VERSION ""

NS_ :

BS_:

BU_: ARM APIM_CDC APIM_CISM APIM ESPM DSP APIM_CIM FCIMB RACM_RCIM HUD_ADV WCM TRM_ITRM ACM GWM _delete IPC GENERIC TSTR

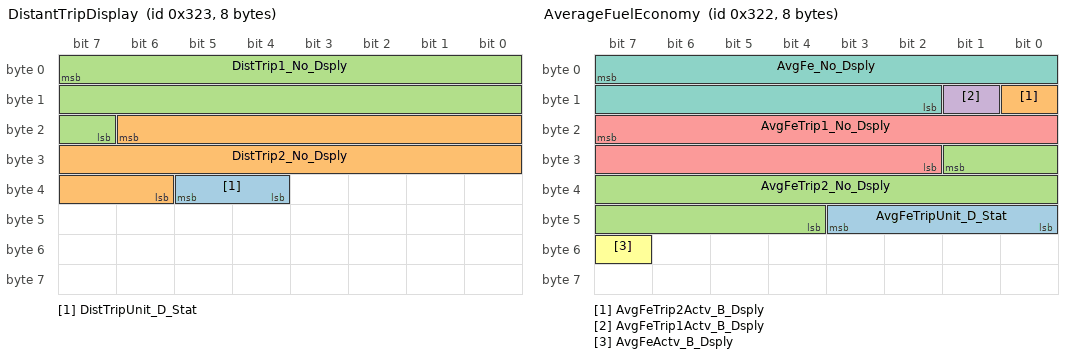
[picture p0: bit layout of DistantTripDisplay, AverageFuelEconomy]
BO_ 803 DistantTripDisplay: 8 IPC
 SG_ DistTripUnit_D_Stat : 37|2@0+ (1,0) [0|3] "SED"  APIM,APIM_CISM
 SG_ DistTrip2_No_Dsply : 22|17@0+ (0.1,0) [0|13107.1] "unitless"  APIM,APIM_CISM
 SG_ DistTrip1_No_Dsply : 7|17@0+ (0.1,0) [0|13107.1] "unitless"  APIM,APIM_CISM

BO_ 802 AverageFuelEconomy: 8 IPC
 SG_ AvgFeTripUnit_D_Stat : 43|4@0+ (1,0) [0|15] "SED"  APIM,APIM_CISM
 SG_ AvgFeTrip2Actv_B_Dsply : 8|1@0+ (1,0) [0|1] "SED"  APIM,APIM_CISM
 SG_ AvgFeTrip2_No_Dsply : 25|14@0+ (0.1,0) [0|1638.3] "unitless"  APIM,APIM_CISM
 SG_ AvgFeTrip1Actv_B_Dsply : 9|1@0+ (1,0) [0|1] "SED"  APIM,APIM_CISM
 SG_ AvgFeTrip1_No_Dsply : 23|14@0+ (0.1,0) [0|1638.3] "unitless"  APIM,APIM_CISM
 SG_ AvgFeActv_B_Dsply : 55|1@0+ (1,0) [0|1] "SED"  APIM,APIM_CISM
 SG_ AvgFe_No_Dsply : 7|14@0+ (0.1,0) [0|1638.3] "unitless"  APIM,APIM_CISM

BO_ 812 TimerDisplay_Data: 8 IPC
 SG_ TimerTrip2_T_Dsply : 29|26@0+ (1,0) [0|67108863] "second"  APIM,APIM_CISM
 SG_ TimerTrip1_T_Dsply : 7|26@0+ (1,0) [0|67108863] "second"  APIM,APIM_CISM

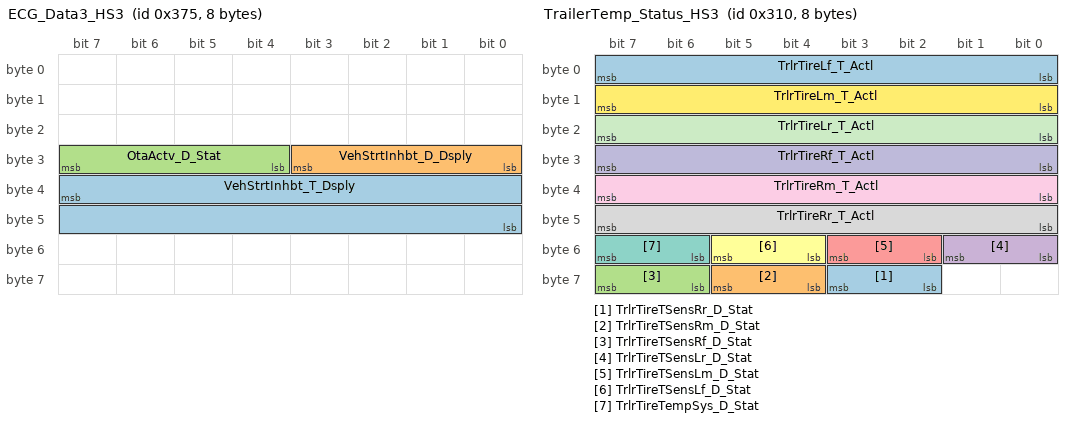
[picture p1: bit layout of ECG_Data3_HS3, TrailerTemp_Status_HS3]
BO_ 885 ECG_Data3_HS3: 8 GWM
 SG_ VehStrtInhbt_T_Dsply : 39|16@0+ (1,0) [0|65535] "second"  APIM_CDC,APIM_CIM,IPC
 SG_ VehStrtInhbt_D_Dsply : 27|4@0+ (1,0) [0|15] "SED"  APIM_CDC,APIM_CIM,IPC
 SG_ OtaActv_D_Stat : 31|4@0+ (1,0) [0|15] "SED"  APIM_CDC,APIM_CIM,IPC

BO_ 784 TrailerTemp_Status_HS3: 8 GWM
 SG_ TrlrTireTSensRr_D_Stat : 59|2@0+ (1,0) [0|3] "SED"  APIM_CDC,APIM_CIM,IPC
 SG_ TrlrTireTSensRm_D_Stat : 61|2@0+ (1,0) [0|3] "SED"  APIM_CDC,APIM_CIM,IPC
 SG_ TrlrTireTSensRf_D_Stat : 63|2@0+ (1,0) [0|3] "SED"  APIM_CDC,APIM_CIM,IPC
 SG_ TrlrTireTSensLr_D_Stat : 49|2@0+ (1,0) [0|3] "SED"  APIM_CDC,APIM_CIM,IPC
 SG_ TrlrTireTSensLm_D_Stat : 51|2@0+ (1,0) [0|3] "SED"  APIM_CDC,APIM_CIM,IPC
 SG_ TrlrTireTSensLf_D_Stat : 53|2@0+ (1,0) [0|3] "SED"  APIM_CDC,IPC,APIM_CIM
 SG_ TrlrTireTempSys_D_Stat : 55|2@0+ (1,0) [0|3] "SED"  APIM_CDC,IPC,APIM_CIM
 SG_ TrlrTireRr_T_Actl : 47|8@0+ (1,-60) [-60|193] "degC"  APIM_CDC,IPC,APIM_CIM
 SG_ TrlrTireRm_T_Actl : 39|8@0+ (1,-60) [-60|193] "degC"  APIM_CDC,IPC,APIM_CIM
 SG_ TrlrTireRf_T_Actl : 31|8@0+ (1,-60) [-60|193] "degC"  APIM_CDC,IPC,APIM_CIM
 SG_ TrlrTireLr_T_Actl : 23|8@0+ (1,-60) [-60|193] "degC"  APIM_CDC,APIM_CIM,IPC
 SG_ TrlrTireLm_T_Actl : 15|8@0+ (1,-60) [-60|193] "degC"  APIM_CDC,APIM_CIM,IPC
 SG_ TrlrTireLf_T_Actl : 7|8@0+ (1,-60) [-60|193] "degC"  APIM_CDC,APIM_CIM,IPC

BO_ 1119 LocationServices_Data2: 8 APIM_CIM
 SG_ LocationServices_2 : 7|64@0+ (1,0) [0|1.84467440737096E+019] "unitless"  GWM,IPC

BO_ 1118 LocationServices_Data1: 8 APIM_CIM
 SG_ LocationServices_1 : 7|64@0+ (1,0) [0|1.84467440737096E+019] "unitless"  IPC,GWM

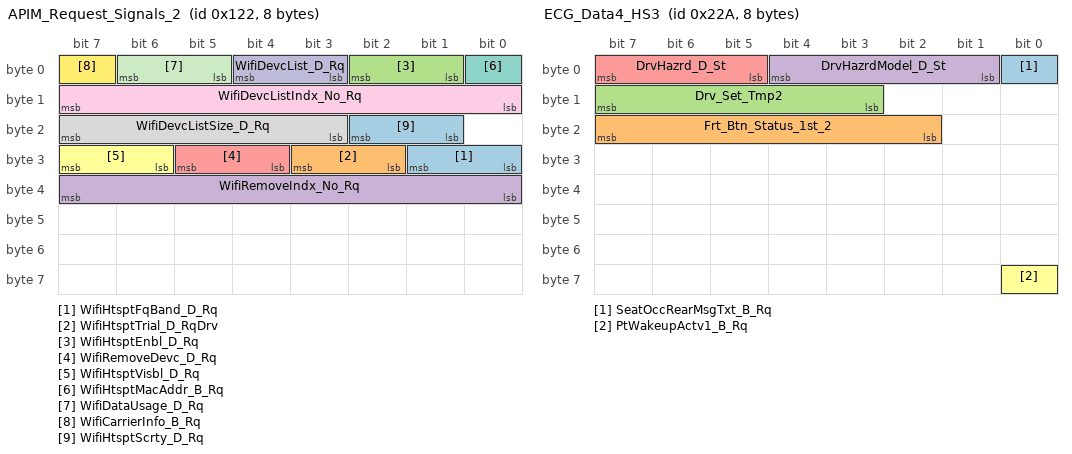
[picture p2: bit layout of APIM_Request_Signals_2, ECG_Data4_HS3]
BO_ 290 APIM_Request_Signals_2: 8 APIM
 SG_ WifiHtsptFqBand_D_Rq : 25|2@0+ (1,0) [0|3] "SED"  GWM
 SG_ WifiHtsptTrial_D_RqDrv : 27|2@0+ (1,0) [0|3] "SED"  GWM
 SG_ WifiHtsptEnbl_D_Rq : 2|2@0+ (1,0) [0|3] "SED"  GWM
 SG_ WifiRemoveIndx_No_Rq : 39|8@0+ (1,0) [0|255] "unitless"  GWM
 SG_ WifiRemoveDevc_D_Rq : 29|2@0+ (1,0) [0|3] "SED"  GWM
 SG_ WifiHtsptVisbl_D_Rq : 31|2@0+ (1,0) [0|3] "SED"  GWM
 SG_ WifiHtsptMacAddr_B_Rq : 0|1@0+ (1,0) [0|1] "SED"  GWM
 SG_ WifiDevcListSize_D_Rq : 23|5@0+ (1,0) [0|31] "unitless"  GWM
 SG_ WifiDevcListIndx_No_Rq : 15|8@0+ (1,0) [0|255] "unitless"  GWM
 SG_ WifiDevcList_D_Rq : 4|2@0+ (1,0) [0|3] "SED"  GWM
 SG_ WifiDataUsage_D_Rq : 6|2@0+ (1,0) [0|3] "SED"  GWM
 SG_ WifiCarrierInfo_B_Rq : 7|1@0+ (1,0) [0|1] "SED"  GWM
 SG_ WifiHtsptScrty_D_Rq : 18|2@0+ (1,0) [0|3] "SED"  GWM

BO_ 554 ECG_Data4_HS3: 8 GWM
 SG_ SeatOccRearMsgTxt_B_Rq : 0|1@0+ (1,0) [0|1] "SED"  APIM_CDC,APIM,APIM_CIM,APIM_CISM
 SG_ Frt_Btn_Status_1st_2 : 23|6@0+ (1,0) [0|63] "SED"  RACM_RCIM
 SG_ Drv_Set_Tmp2 : 15|5@0+ (1,0) [0|31] "SED"  RACM_RCIM
 SG_ DrvHazrdModel_D_St : 4|4@0+ (1,0) [0|15] "SED"  APIM_CDC,APIM,APIM_CISM,APIM_CIM,IPC
 SG_ DrvHazrd_D_St : 7|3@0+ (1,0) [0|7] "SED"  APIM_CDC,APIM,APIM_CISM,APIM_CIM,IPC
 SG_ PtWakeupActv1_B_Rq : 56|1@0+ (1,0) [0|1] "SED"  APIM_CDC,APIM,APIM_CISM,APIM_CIM

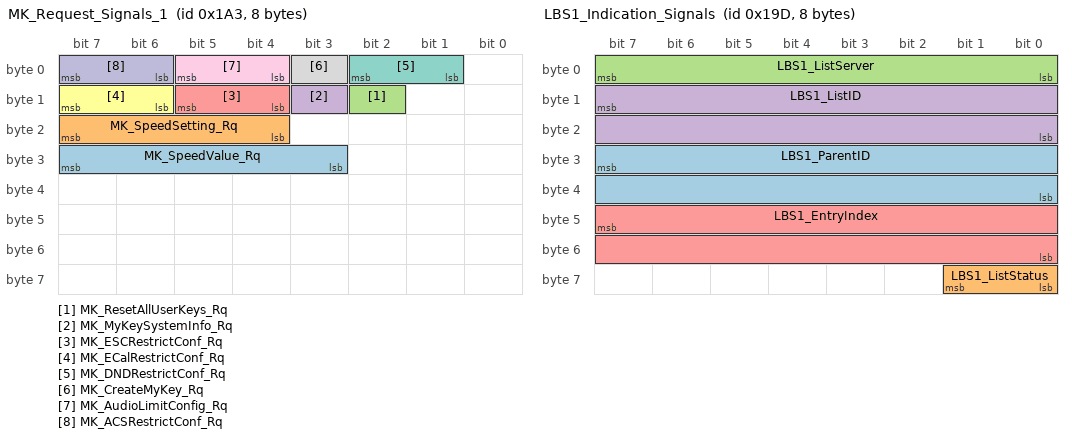
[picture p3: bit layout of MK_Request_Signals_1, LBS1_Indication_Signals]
BO_ 419 MK_Request_Signals_1: 8 APIM
 SG_ MK_SpeedValue_Rq : 31|5@0+ (1,0) [0|31] "SED"  IPC
 SG_ MK_SpeedSetting_Rq : 23|4@0+ (1,0) [0|15] "SED"  IPC
 SG_ MK_ResetAllUserKeys_Rq : 10|1@0+ (1,0) [0|1] "SED"  IPC
 SG_ MK_MyKeySystemInfo_Rq : 11|1@0+ (1,0) [0|1] "SED"  IPC
 SG_ MK_ESCRestrictConf_Rq : 13|2@0+ (1,0) [0|3] "SED"  IPC
 SG_ MK_ECalRestrictConf_Rq : 15|2@0+ (1,0) [0|3] "SED"  IPC
 SG_ MK_DNDRestrictConf_Rq : 2|2@0+ (1,0) [0|3] "SED"  IPC
 SG_ MK_CreateMyKey_Rq : 3|1@0+ (1,0) [0|1] "SED"  IPC
 SG_ MK_AudioLimitConfig_Rq : 5|2@0+ (1,0) [0|3] "SED"  IPC
 SG_ MK_ACSRestrictConf_Rq : 7|2@0+ (1,0) [0|3] "SED"  IPC

BO_ 542 LocationServices_3_HS3: 8 GWM
 SG_ LocationServices_3 : 7|64@0+ (1,0) [0|1.84467440737096E+019] "unitless"  APIM_CDC,APIM,APIM_CISM,APIM_CIM,IPC,ACM

BO_ 413 LBS1_Indication_Signals: 8 APIM
 SG_ LBS1_ParentID : 31|16@0+ (1,0) [0|65535] "unitless"  RACM_RCIM,IPC
 SG_ LBS1_ListStatus : 57|2@0+ (1,0) [0|3] "SED"  RACM_RCIM,IPC
 SG_ LBS1_ListServer : 7|8@0+ (1,0) [0|255] "unitless"  RACM_RCIM,IPC
 SG_ LBS1_ListID : 15|16@0+ (1,0) [0|65535] "unitless"  RACM_RCIM,IPC
 SG_ LBS1_EntryIndex : 47|16@0+ (1,0) [0|65535] "unitless"  RACM_RCIM,IPC

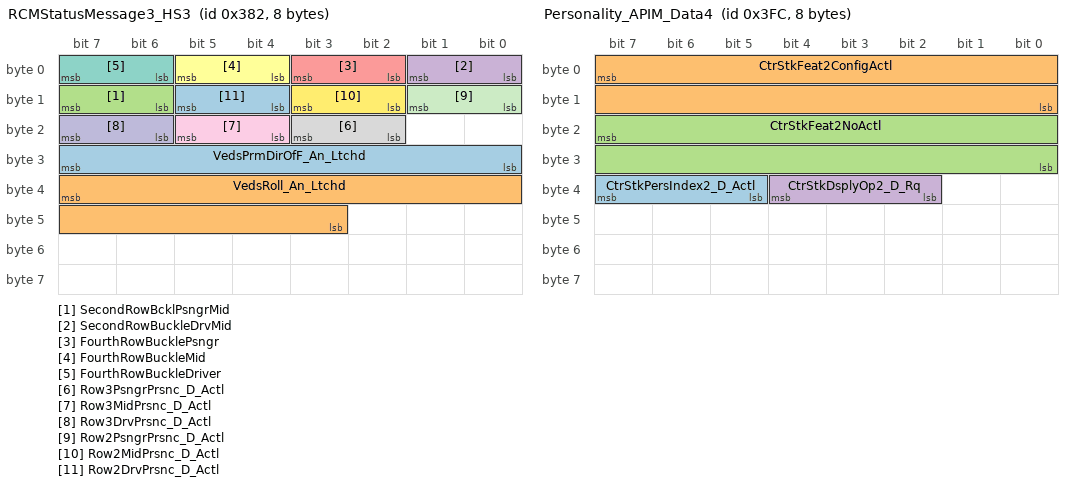
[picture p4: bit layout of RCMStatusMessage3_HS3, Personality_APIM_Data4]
BO_ 898 RCMStatusMessage3_HS3: 8 GWM
 SG_ VedsPrmDirOfF_An_Ltchd : 31|8@0+ (2,-180) [-178|326] "degree"  APIM_CDC,APIM_CIM,APIM_CISM,APIM
 SG_ VedsRoll_An_Ltchd : 39|13@0+ (0.5,-2048) [-2047.5|2046.5] "degree"  APIM_CDC,APIM_CIM,APIM_CISM,APIM
 SG_ SecondRowBcklPsngrMid : 15|2@0+ (1,0) [0|3] "SED"  APIM_CDC,APIM_CIM,IPC
 SG_ SecondRowBuckleDrvMid : 1|2@0+ (1,0) [0|3] "SED"  APIM_CDC,APIM_CIM,IPC
 SG_ FourthRowBucklePsngr : 3|2@0+ (1,0) [0|3] "SED"  APIM_CDC,APIM_CIM,IPC
 SG_ FourthRowBuckleMid : 5|2@0+ (1,0) [0|3] "SED"  APIM_CDC,APIM_CIM,IPC
 SG_ FourthRowBuckleDriver : 7|2@0+ (1,0) [0|3] "SED"  APIM_CDC,APIM_CIM,IPC
 SG_ Row3PsngrPrsnc_D_Actl : 19|2@0+ (1,0) [0|3] "SED"  APIM_CDC,APIM,APIM_CIM,APIM_CISM,IPC
 SG_ Row3MidPrsnc_D_Actl : 21|2@0+ (1,0) [0|3] "SED"  APIM_CDC,APIM,APIM_CIM,APIM_CISM,IPC
 SG_ Row3DrvPrsnc_D_Actl : 23|2@0+ (1,0) [0|3] "SED"  APIM_CDC,APIM,APIM_CIM,APIM_CISM,IPC
 SG_ Row2PsngrPrsnc_D_Actl : 9|2@0+ (1,0) [0|3] "SED"  APIM_CDC,APIM,APIM_CIM,APIM_CISM,IPC
 SG_ Row2MidPrsnc_D_Actl : 11|2@0+ (1,0) [0|3] "SED"  APIM_CDC,APIM,APIM_CIM,APIM_CISM,IPC
 SG_ Row2DrvPrsnc_D_Actl : 13|2@0+ (1,0) [0|3] "SED"  APIM_CDC,APIM,APIM_CIM,APIM_CISM,IPC

BO_ 1020 Personality_APIM_Data4: 8 APIM_CIM
 SG_ CtrStkPersIndex2_D_Actl : 39|3@0+ (1,0) [0|7] "SED"  HUD_ADV,IPC
 SG_ CtrStkFeat2ConfigActl : 7|16@0+ (1,0) [0|65535] "Undefined"  HUD_ADV,IPC
 SG_ CtrStkFeat2NoActl : 23|16@0+ (1,0) [0|65535] "Undefined"  HUD_ADV,IPC
 SG_ CtrStkDsplyOp2_D_Rq : 36|3@0+ (1,0) [0|7] "SED"  HUD_ADV,IPC

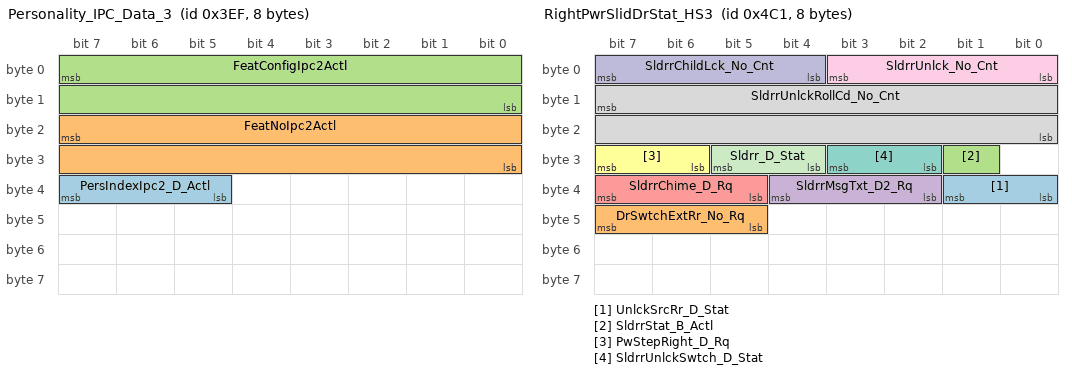
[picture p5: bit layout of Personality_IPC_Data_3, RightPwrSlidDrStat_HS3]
BO_ 1007 Personality_IPC_Data_3: 8 IPC
 SG_ PersIndexIpc2_D_Actl : 39|3@0+ (1,0) [0|7] "SED"  APIM,APIM_CISM
 SG_ FeatNoIpc2Actl : 23|16@0+ (1,0) [0|65535] "Number"  APIM,APIM_CISM
 SG_ FeatConfigIpc2Actl : 7|16@0+ (1,0) [0|65535] "unitless"  APIM,APIM_CISM

BO_ 1217 RightPwrSlidDrStat_HS3: 8 GWM
 SG_ UnlckSrcRr_D_Stat : 33|2@0+ (1,0) [0|3] "SED" Vector__XXX
 SG_ DrSwtchExtRr_No_Rq : 47|3@0+ (1,0) [0|7] "unitless" Vector__XXX
 SG_ SldrrStat_B_Actl : 25|1@0+ (1,0) [0|1] "SED"  APIM_CDC,APIM_CIM,IPC
 SG_ SldrrMsgTxt_D2_Rq : 36|3@0+ (1,0) [0|7] "SED"  APIM_CDC,APIM_CIM,IPC
 SG_ SldrrChime_D_Rq : 39|3@0+ (1,0) [0|7] "SED"  APIM_CDC,APIM_CIM,IPC
 SG_ PwStepRight_D_Rq : 31|2@0+ (1,0) [0|3] "SED" Vector__XXX
 SG_ SldrrUnlckSwtch_D_Stat : 27|2@0+ (1,0) [0|3] "SED" Vector__XXX
 SG_ SldrrUnlckRollCd_No_Cnt : 15|16@0+ (1,0) [0|65535] "unitless" Vector__XXX
 SG_ SldrrUnlck_No_Cnt : 3|4@0+ (1,0) [0|15] "unitless" Vector__XXX
 SG_ SldrrChildLck_No_Cnt : 7|4@0+ (1,0) [0|15] "unitless" Vector__XXX
 SG_ Sldrr_D_Stat : 29|2@0+ (1,0) [0|3] "SED" Vector__XXX

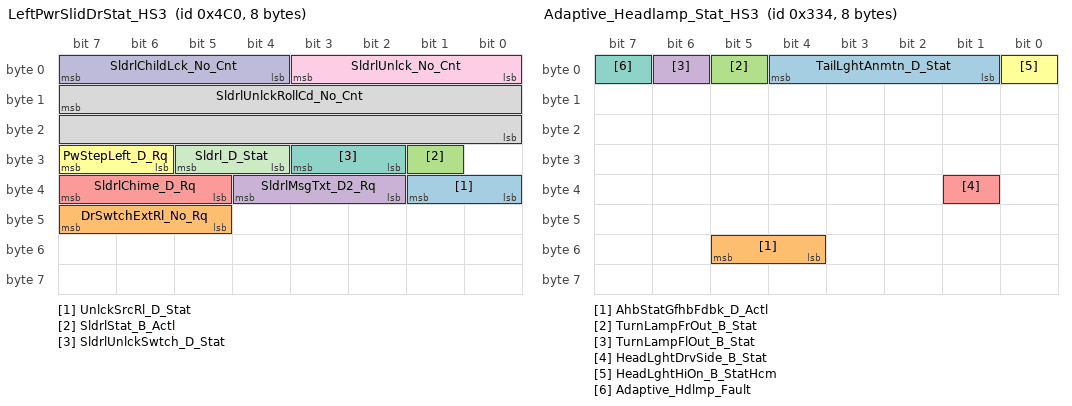
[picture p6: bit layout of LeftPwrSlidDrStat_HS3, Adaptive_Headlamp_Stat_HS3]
BO_ 1216 LeftPwrSlidDrStat_HS3: 8 GWM
 SG_ UnlckSrcRl_D_Stat : 33|2@0+ (1,0) [0|3] "SED" Vector__XXX
 SG_ DrSwtchExtRl_No_Rq : 47|3@0+ (1,0) [0|7] "unitless" Vector__XXX
 SG_ SldrlStat_B_Actl : 25|1@0+ (1,0) [0|1] "SED"  APIM_CDC,APIM_CIM,IPC
 SG_ SldrlMsgTxt_D2_Rq : 36|3@0+ (1,0) [0|7] "SED"  APIM_CDC,APIM_CIM,IPC
 SG_ SldrlChime_D_Rq : 39|3@0+ (1,0) [0|7] "SED"  APIM_CDC,APIM_CIM,IPC
 SG_ PwStepLeft_D_Rq : 31|2@0+ (1,0) [0|3] "SED" Vector__XXX
 SG_ SldrlUnlckSwtch_D_Stat : 27|2@0+ (1,0) [0|3] "SED" Vector__XXX
 SG_ SldrlUnlckRollCd_No_Cnt : 15|16@0+ (1,0) [0|65535] "unitless" Vector__XXX
 SG_ SldrlUnlck_No_Cnt : 3|4@0+ (1,0) [0|15] "unitless" Vector__XXX
 SG_ SldrlChildLck_No_Cnt : 7|4@0+ (1,0) [0|15] "unitless" Vector__XXX
 SG_ Sldrl_D_Stat : 29|2@0+ (1,0) [0|3] "SED" Vector__XXX

BO_ 820 Adaptive_Headlamp_Stat_HS3: 8 GWM
 SG_ TailLghtAnmtn_D_Stat : 4|4@0+ (1,0) [0|15] "SED"  APIM
 SG_ AhbStatGfhbFdbk_D_Actl : 53|2@0+ (1,0) [0|3] "SED" Vector__XXX
 SG_ TurnLampFrOut_B_Stat : 5|1@0+ (1,0) [0|1] "SED" Vector__XXX
 SG_ TurnLampFlOut_B_Stat : 6|1@0+ (1,0) [0|1] "SED" Vector__XXX
 SG_ HeadLghtDrvSide_B_Stat : 33|1@0+ (1,0) [0|1] "SED" Vector__XXX
 SG_ HeadLghtHiOn_B_StatHcm : 0|1@0+ (1,0) [0|1] "SED"  APIM_CDC,APIM_CIM,IPC
 SG_ Adaptive_Hdlmp_Fault : 7|1@0+ (1,0) [0|1] "SED"  APIM_CDC,APIM_CIM,IPC

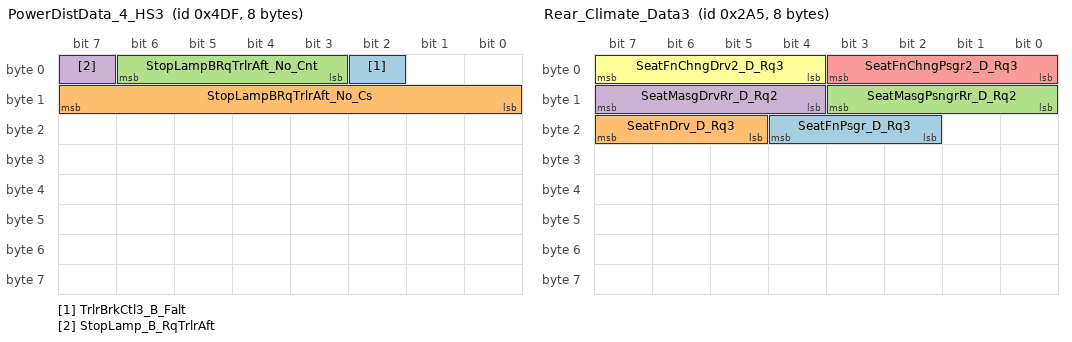
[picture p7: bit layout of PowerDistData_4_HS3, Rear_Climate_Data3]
BO_ 1247 PowerDistData_4_HS3: 8 GWM
 SG_ TrlrBrkCtl3_B_Falt : 2|1@0+ (1,0) [0|1] "SED"  TRM_ITRM
 SG_ StopLampBRqTrlrAft_No_Cs : 15|8@0+ (1,0) [0|255] "Unitless"  TRM_ITRM
 SG_ StopLampBRqTrlrAft_No_Cnt : 6|4@0+ (1,0) [0|15] "Unitless"  TRM_ITRM
 SG_ StopLamp_B_RqTrlrAft : 7|1@0+ (1,0) [0|1] "SED"  TRM_ITRM

BO_ 677 Rear_Climate_Data3: 8 RACM_RCIM
 SG_ SeatFnPsgr_D_Rq3 : 20|3@0+ (1,0) [0|7] "SED"  GWM
 SG_ SeatFnDrv_D_Rq3 : 23|3@0+ (1,0) [0|7] "SED"  GWM
 SG_ SeatMasgPsngrRr_D_Rq2 : 11|4@0+ (1,0) [0|15] "SED"  GWM
 SG_ SeatMasgDrvRr_D_Rq2 : 15|4@0+ (1,0) [0|15] "SED"  GWM
 SG_ SeatFnChngPsgr2_D_Rq3 : 3|4@0+ (1,0) [0|15] "SED"  GWM
 SG_ SeatFnChngDrv2_D_Rq3 : 7|4@0+ (1,0) [0|15] "SED"  GWM

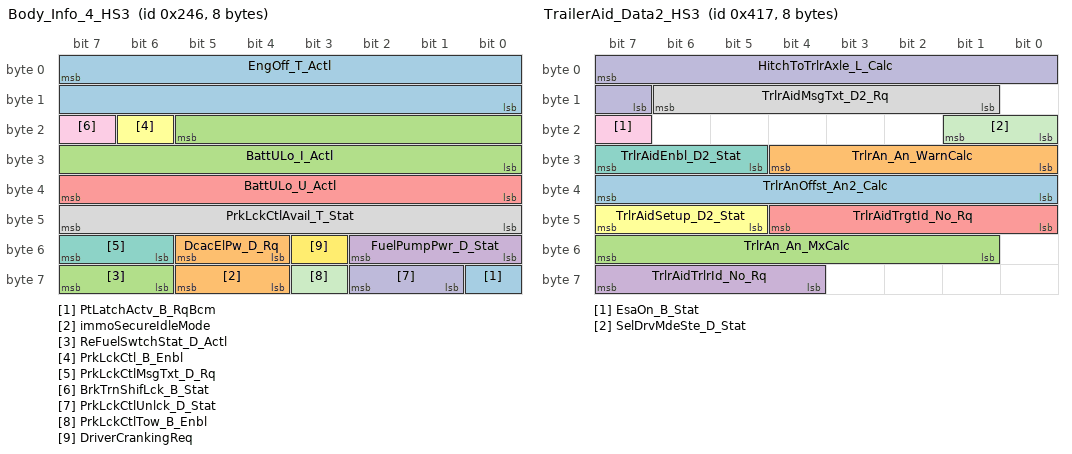
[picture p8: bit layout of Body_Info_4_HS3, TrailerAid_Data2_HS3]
BO_ 582 Body_Info_4_HS3: 8 GWM
 SG_ PtLatchActv_B_RqBcm : 56|1@0+ (1,0) [0|1] "SED"  APIM_CDC,APIM_CIM,IPC
 SG_ immoSecureIdleMode : 61|2@0+ (1,0) [0|3] "SED"  APIM_CDC,APIM,APIM_CISM,APIM_CIM
 SG_ ReFuelSwtchStat_D_Actl : 63|2@0+ (1,0) [0|3] "SED" Vector__XXX
 SG_ FuelPumpPwr_D_Stat : 50|3@0+ (1,0) [0|7] "SED" Vector__XXX
 SG_ BattULo_U_Actl : 39|8@0+ (0.0625,0) [0|15.875] "volt" Vector__XXX
 SG_ PrkLckCtl_B_Enbl : 22|1@0+ (1,0) [0|1] "SED"  APIM_CDC,APIM,APIM_CISM,IPC,APIM_CIM
 SG_ PrkLckCtlMsgTxt_D_Rq : 55|2@0+ (1,0) [0|3] "SED"  APIM_CDC,APIM_CIM,IPC
 SG_ PrkLckCtlAvail_T_Stat : 47|8@0+ (1,0) [0|255] "second"  APIM_CDC,APIM_CIM,IPC
 SG_ BrkTrnShifLck_B_Stat : 23|1@0+ (1,0) [0|1] "SED" Vector__XXX
 SG_ PrkLckCtlUnlck_D_Stat : 58|2@0+ (1,0) [0|3] "SED"  APIM_CDC,APIM_CIM,IPC
 SG_ PrkLckCtlTow_B_Enbl : 59|1@0+ (1,0) [0|1] "SED"  APIM_CDC,APIM_CIM,IPC
 SG_ DriverCrankingReq : 51|1@0+ (1,0) [0|1] "SED" Vector__XXX
 SG_ EngOff_T_Actl : 7|16@0+ (1,0) [0|65534] "second^0.5"  APIM_CDC,APIM_CIM,IPC
 SG_ DcacElPw_D_Rq : 53|2@0+ (1,0) [0|3] "SED" Vector__XXX
 SG_ BattULo_I_Actl : 21|14@0+ (0.0625,-512) [-512|511.875] "ampere" Vector__XXX

BO_ 1036 PedestrianAlert_Data_HS3: 8 GWM
 SG_ PdstrnAlrt_B_Falt : 7|1@0+ (1,0) [0|1] "SED"  APIM_CDC,APIM_CIM,IPC

BO_ 1047 TrailerAid_Data2_HS3: 8 GWM
 SG_ TrlrAnOffst_An2_Calc : 39|8@0+ (0.5,-64) [-64|63.5] "degrees" Vector__XXX
 SG_ TrlrAn_An_WarnCalc : 28|5@0+ (1,0) [0|31] "degrees" Vector__XXX
 SG_ TrlrAn_An_MxCalc : 55|7@0+ (1,0) [0|127] "degrees" Vector__XXX
 SG_ TrlrAidTrlrId_No_Rq : 63|4@0+ (1,0) [0|15] "unitless"  APIM_CDC,APIM,APIM_CISM,APIM_CIM,IPC
 SG_ TrlrAidTrgtId_No_Rq : 44|5@0+ (1,0) [0|31] "unitless" Vector__XXX
 SG_ TrlrAidSetup_D2_Stat : 47|3@0+ (1,0) [0|7] "SED" Vector__XXX
 SG_ TrlrAidEnbl_D2_Stat : 31|3@0+ (1,0) [0|7] "SED"  APIM_CDC,APIM,APIM_CISM,TRM_ITRM,APIM_CIM,IPC
 SG_ TrlrAidMsgTxt_D2_Rq : 14|6@0+ (1,0) [0|63] "SED"  APIM_CDC,APIM,APIM_CISM,APIM_CIM,IPC,TRM_ITRM
 SG_ EsaOn_B_Stat : 23|1@0+ (1,0) [0|1] "SED"  APIM_CDC,APIM_CIM,IPC
 SG_ HitchToTrlrAxle_L_Calc : 7|9@0+ (0.0254,0) [0|12.9794] "meter" Vector__XXX
 SG_ SelDrvMdeSte_D_Stat : 17|2@0+ (1,0) [0|3] "SED" Vector__XXX

BO_ 688 APIM_TCUB_Word_Rx_HS3: 8 GWM
 SG_ APIM_TCUB_Word_Rx : 7|64@0+ (1,0) [0|1.84467440737096E+019] "unitless"  APIM_CDC,APIM,APIM_CISM,APIM_CIM

BO_ 696 APIM_TCUB_Word_Tx: 8 APIM
 SG_ APIM_TCUB_Word_Tx : 7|64@0+ (1,0) [0|1.84467440737096E+019] "unitless"  GWM

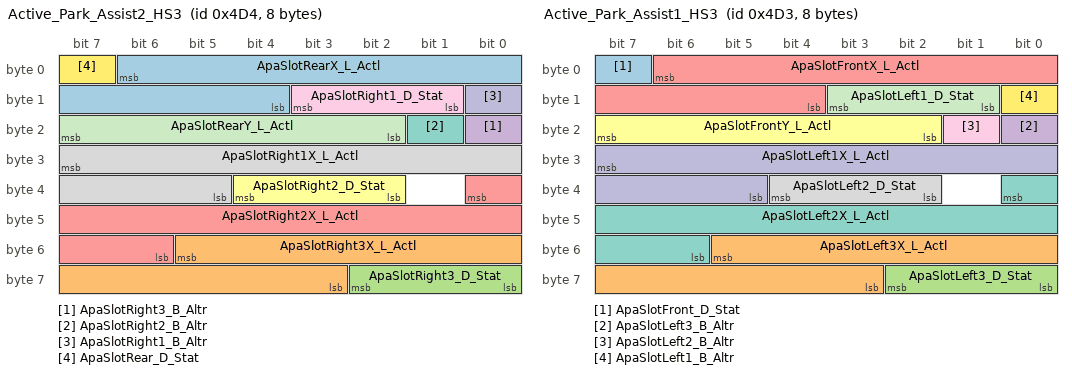
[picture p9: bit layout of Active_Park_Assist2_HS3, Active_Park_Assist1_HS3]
BO_ 1236 Active_Park_Assist2_HS3: 8 GWM
 SG_ ApaSlotRearX_L_Actl : 6|11@0+ (0.02,-20.96) [-20.96|19.98] "meter"  APIM_CDC,APIM,APIM_CISM,APIM_CIM
 SG_ ApaSlotRight3X_L_Actl : 53|11@0+ (0.02,-20.96) [-20.96|19.98] "meter"  APIM_CDC,APIM,APIM_CISM,APIM_CIM
 SG_ ApaSlotRight3_D_Stat : 58|3@0+ (1,0) [0|7] "SED"  APIM_CDC,APIM,APIM_CISM,APIM_CIM
 SG_ ApaSlotRight3_B_Altr : 16|1@0+ (1,0) [0|1] "SED"  APIM_CDC,APIM,APIM_CISM,APIM_CIM
 SG_ ApaSlotRight2X_L_Actl : 32|11@0+ (0.02,-20.96) [-20.96|19.98] "meter"  APIM_CDC,APIM,APIM_CISM,APIM_CIM
 SG_ ApaSlotRight2_D_Stat : 36|3@0+ (1,0) [0|7] "SED"  APIM_CDC,APIM,APIM_CISM,APIM_CIM
 SG_ ApaSlotRight2_B_Altr : 17|1@0+ (1,0) [0|1] "SED"  APIM_CDC,APIM,APIM_CISM,APIM_CIM
 SG_ ApaSlotRight1X_L_Actl : 31|11@0+ (0.02,-20.96) [-20.96|19.98] "meter"  APIM_CDC,APIM,APIM_CISM,APIM_CIM
 SG_ ApaSlotRight1_D_Stat : 11|3@0+ (1,0) [0|7] "SED"  APIM_CDC,APIM,APIM_CISM,APIM_CIM
 SG_ ApaSlotRight1_B_Altr : 8|1@0+ (1,0) [0|1] "SED"  APIM_CDC,APIM,APIM_CISM,APIM_CIM
 SG_ ApaSlotRearY_L_Actl : 23|6@0+ (0.2,-6.4) [-6.4|6.2] "meter"  APIM_CDC,APIM,APIM_CISM,APIM_CIM
 SG_ ApaSlotRear_D_Stat : 7|1@0+ (1,0) [0|1] "SED"  APIM_CDC,APIM,APIM_CISM,APIM_CIM

BO_ 1235 Active_Park_Assist1_HS3: 8 GWM
 SG_ ApaSlotFront_D_Stat : 7|1@0+ (1,0) [0|1] "SED"  APIM_CDC,APIM,APIM_CISM,APIM_CIM
 SG_ ApaSlotLeft3X_L_Actl : 53|11@0+ (0.02,-20.96) [-20.96|19.98] "meter"  APIM_CDC,APIM,APIM_CISM,APIM_CIM
 SG_ ApaSlotLeft3_D_Stat : 58|3@0+ (1,0) [0|7] "SED"  APIM_CDC,APIM,APIM_CISM,APIM_CIM
 SG_ ApaSlotLeft3_B_Altr : 16|1@0+ (1,0) [0|1] "SED"  APIM_CDC,APIM,APIM_CISM,APIM_CIM
 SG_ ApaSlotFrontX_L_Actl : 6|11@0+ (0.02,-20.96) [-20.96|19.98] "meter"  APIM_CDC,APIM,APIM_CISM,APIM_CIM
 SG_ ApaSlotFrontY_L_Actl : 23|6@0+ (0.2,-6.4) [-6.4|6.2] "meter"  APIM_CDC,APIM,APIM_CISM,APIM_CIM
 SG_ ApaSlotLeft2X_L_Actl : 32|11@0+ (0.02,-20.96) [-20.96|19.98] "meter"  APIM_CDC,APIM,APIM_CISM,APIM_CIM
 SG_ ApaSlotLeft2_D_Stat : 36|3@0+ (1,0) [0|7] "SED"  APIM_CDC,APIM,APIM_CISM,APIM_CIM
 SG_ ApaSlotLeft2_B_Altr : 17|1@0+ (1,0) [0|1] "SED"  APIM_CDC,APIM,APIM_CISM,APIM_CIM
 SG_ ApaSlotLeft1X_L_Actl : 31|11@0+ (0.02,-20.96) [-20.96|19.98] "meter"  APIM_CDC,APIM,APIM_CISM,APIM_CIM
 SG_ ApaSlotLeft1_D_Stat : 11|3@0+ (1,0) [0|7] "SED"  APIM_CDC,APIM,APIM_CISM,APIM_CIM
 SG_ ApaSlotLeft1_B_Altr : 8|1@0+ (1,0) [0|1] "SED"  APIM_CDC,APIM,APIM_CISM,APIM_CIM

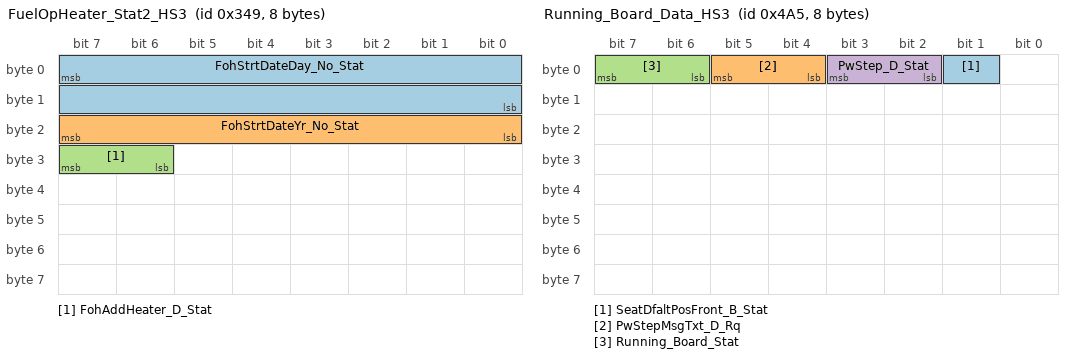
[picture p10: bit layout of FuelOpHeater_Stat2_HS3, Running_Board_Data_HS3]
BO_ 841 FuelOpHeater_Stat2_HS3: 8 GWM
 SG_ FohStrtDateDay_No_Stat : 7|16@0+ (1,0) [0|65535] "julian day"  APIM_CDC,IPC,APIM_CIM
 SG_ FohStrtDateYr_No_Stat : 23|8@0+ (1,2000) [2000|2255] "year"  APIM_CDC,IPC,APIM_CIM
 SG_ FohAddHeater_D_Stat : 31|2@0+ (1,0) [0|3] "SED"  APIM_CDC,APIM_CIM

BO_ 1189 Running_Board_Data_HS3: 8 GWM
 SG_ SeatDfaltPosFront_B_Stat : 1|1@0+ (1,0) [0|1] "SED" Vector__XXX
 SG_ PwStepMsgTxt_D_Rq : 5|2@0+ (1,0) [0|3] "SED"  APIM_CDC,APIM_CIM,IPC
 SG_ Running_Board_Stat : 7|2@0+ (1,0) [0|3] "SED"  APIM_CDC,APIM,APIM_CISM,APIM_CIM,IPC
 SG_ PwStep_D_Stat : 3|2@0+ (1,0) [0|3] "SED" Vector__XXX

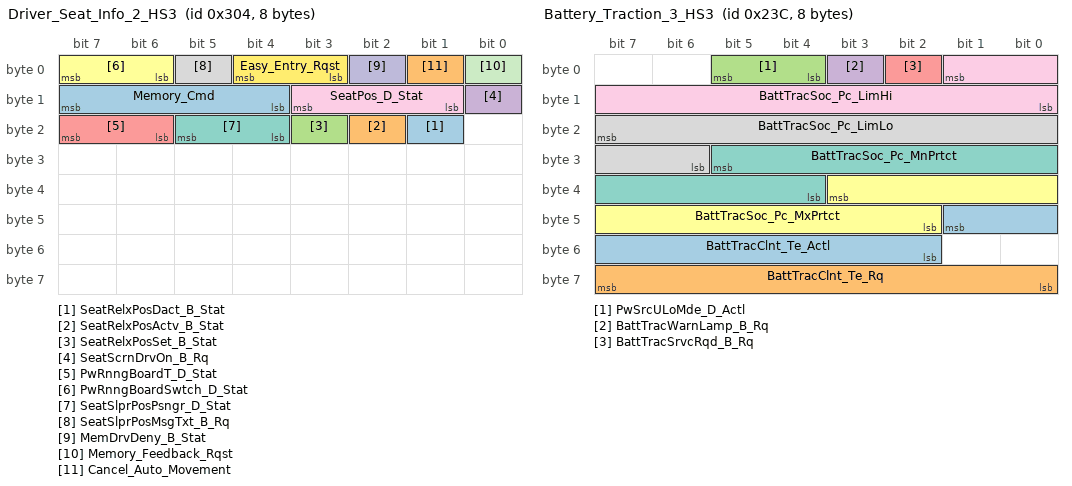
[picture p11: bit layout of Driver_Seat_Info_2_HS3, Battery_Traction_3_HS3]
BO_ 772 Driver_Seat_Info_2_HS3: 8 GWM
 SG_ SeatRelxPosDact_B_Stat : 17|1@0+ (1,0) [0|1] "SED"  APIM_CDC,APIM,APIM_CIM,APIM_CISM
 SG_ SeatRelxPosActv_B_Stat : 18|1@0+ (1,0) [0|1] "SED"  APIM_CDC,APIM,APIM_CIM,APIM_CISM
 SG_ SeatRelxPosSet_B_Stat : 19|1@0+ (1,0) [0|1] "SED"  APIM_CDC,APIM,APIM_CIM,APIM_CISM
 SG_ SeatScrnDrvOn_B_Rq : 8|1@0+ (1,0) [0|1] "SED"  APIM_CDC,APIM,APIM_CISM,APIM_CIM
 SG_ PwRnngBoardT_D_Stat : 23|2@0+ (1,0) [0|3] "SED"  APIM_CDC,APIM,APIM_CISM,APIM_CIM,IPC
 SG_ PwRnngBoardSwtch_D_Stat : 7|2@0+ (1,0) [0|3] "SED"  APIM_CDC,APIM,APIM_CISM,APIM_CIM,IPC
 SG_ SeatSlprPosPsngr_D_Stat : 21|2@0+ (1,0) [0|3] "SED" Vector__XXX
 SG_ SeatSlprPosMsgTxt_B_Rq : 5|1@0+ (1,0) [0|1] "SED"  APIM_CDC,IPC,APIM_CIM
 SG_ SeatPos_D_Stat : 11|3@0+ (1,0) [0|7] "SED" Vector__XXX
 SG_ MemDrvDeny_B_Stat : 2|1@0+ (1,0) [0|1] "SED"  APIM_CDC,APIM_CIM,IPC
 SG_ Memory_Feedback_Rqst : 0|1@0+ (1,0) [0|1] "SED"  APIM_CDC,APIM_CIM,IPC
 SG_ Easy_Entry_Rqst : 4|2@0+ (1,0) [0|3] "SED" Vector__XXX
 SG_ Memory_Cmd : 15|4@0+ (1,0) [0|15] "SED"  APIM_CDC,HUD_ADV,APIM_CIM,IPC
 SG_ Cancel_Auto_Movement : 1|1@0+ (1,0) [0|1] "SED"  APIM_CISM,APIM_CIM

BO_ 1054 BrakeSysFeatures_3_HS3: 8 GWM
 SG_ SelDrvMdeChassis3_D_Rq : 61|5@0+ (1,0) [0|31] "SED" Vector__XXX
 SG_ RbaBrk_D_Stat : 63|2@0+ (1,0) [0|3] "SED" Vector__XXX
 SG_ SelDrvMdeChassis2_D_Rq : 45|5@0+ (1,0) [0|31] "SED" Vector__XXX
 SG_ BrkBstrLoLampOn_B_Rq : 24|1@0+ (1,0) [0|1] "SED" Vector__XXX
 SG_ TrailCtl_D_Stat : 55|3@0+ (1,0) [0|7] "SED"  APIM_CDC,HUD_ADV,APIM,APIM_CISM,APIM_CIM,IPC
 SG_ TrailCtlMsgTxt_D_Rq : 52|4@0+ (1,0) [0|15] "SED"  APIM_CDC,APIM_CISM,APIM_CIM,IPC
 SG_ BrkPadMsgTxt_D_Rq : 31|2@0+ (1,0) [0|3] "SED"  APIM_CDC,IPC,APIM_CIM
 SG_ BrkBstrVac_D_Stat : 18|2@0+ (1,0) [0|3] "SED" Vector__XXX
 SG_ DrvSlipCtlOffLamp_D_Rq : 23|2@0+ (1,0) [0|3] "SED"  APIM_CDC,APIM,APIM_CIM,APIM_CISM,IPC
 SG_ DrvSlipCtlMdeMsg_D_Rq : 13|5@0+ (1,0) [0|31] "SED"  APIM_CDC,APIM,APIM_CISM,APIM_CIM,IPC
 SG_ HdcOn_B_Ind : 16|1@0+ (1,0) [0|1] "SED"  APIM_CDC,APIM,APIM_CISM,APIM_CIM,IPC
 SG_ AutoHoldMsgTxt_D_Rq : 4|4@0+ (1,0) [0|15] "SED"  APIM_CDC,APIM_CIM,IPC
 SG_ CtaBrk_D_Stat : 47|2@0+ (1,0) [0|3] "SED" Vector__XXX
 SG_ SelDrvMdeAwd_D_Rq : 29|5@0+ (1,0) [0|31] "SED" Vector__XXX
 SG_ AutoHoldSwMde_B_Ind : 0|1@0+ (1,0) [0|1] "SED"  APIM_CDC,APIM,APIM_CISM,APIM_CIM
 SG_ AutoHoldMde_D_Ind : 15|2@0+ (1,0) [0|3] "SED"  APIM_CDC,APIM_CIM,IPC,HUD_ADV
 SG_ BrkMdeInhbt_B_RqDsply : 8|1@0+ (1,0) [0|1] "SED"  APIM_CDC,APIM_CIM,IPC
 SG_ BrkLineLck_D_Stat : 21|3@0+ (1,0) [0|7] "SED"  APIM_CDC,APIM_CIM,IPC
 SG_ SelDrvMdeChassis_D_Rq : 39|5@0+ (1,0) [0|31] "SED" Vector__XXX
 SG_ ApaBrk_D_Stat : 34|2@0+ (1,0) [0|3] "SED" Vector__XXX
 SG_ FrontDiffElckrOpen_B_Rq : 48|1@0+ (1,0) [0|1] "SED" Vector__XXX
 SG_ OnePdlDrvDeny_B_Stat : 40|1@0+ (1,0) [0|1] "SED" Vector__XXX
 SG_ BrkDrvMde_D_Stat : 7|3@0+ (1,0) [0|7] "SED"  ACM,IPC
 SG_ TrailOnePdlTqLm_B_Actl : 56|1@0+ (1,0) [0|1] "SED" Vector__XXX

BO_ 572 Battery_Traction_3_HS3: 8 GWM
 SG_ BattTracClnt_Te_Actl : 41|8@0+ (0.5,-60) [-60|66.5] "degC" Vector__XXX
 SG_ BattTracClnt_Te_Rq : 63|8@0+ (0.5,-60) [-60|67.5] "degC" Vector__XXX
 SG_ PwSrcULoMde_D_Actl : 5|2@0+ (1,0) [0|3] "SED" Vector__XXX
 SG_ BattTracWarnLamp_B_Rq : 3|1@0+ (1,0) [0|1] "SED"  APIM_CDC,APIM_CIM,IPC
 SG_ BattTracSrvcRqd_B_Rq : 2|1@0+ (1,0) [0|1] "SED"  APIM_CDC,APIM_CIM,IPC
 SG_ BattTracSoc_Pc_MxPrtct : 35|10@0+ (0.1,0) [0|100] "%"  APIM_CDC,APIM,APIM_CIM,APIM_CISM
 SG_ BattTracSoc_Pc_MnPrtct : 29|10@0+ (0.1,0) [0|100] "%" Vector__XXX
 SG_ BattTracSoc_Pc_LimLo : 23|10@0+ (0.1,0) [0|100] "%" Vector__XXX
 SG_ BattTracSoc_Pc_LimHi : 1|10@0+ (0.1,0) [0|100] "%" Vector__XXX

BO_ 561 TransGearData_2_HS3: 8 GWM
 SG_ TrnMsgTxt2_D_Rq : 39|3@0+ (1,0) [0|7] "SED"  APIM_CDC,APIM_CISM,APIM_CIM,IPC
 SG_ TrnMsgTxt_D_Rq : 23|4@0+ (1,0) [0|15] "SED"  APIM_CDC,APIM_CIM,IPC

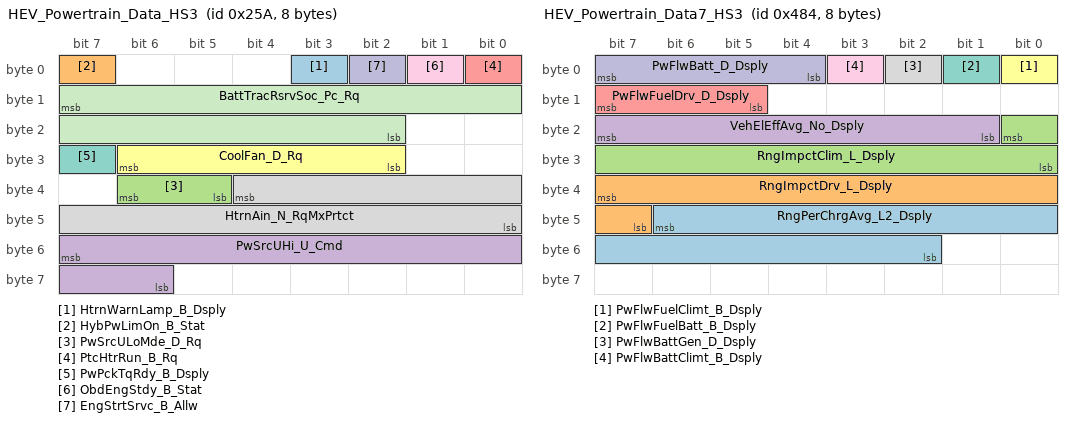
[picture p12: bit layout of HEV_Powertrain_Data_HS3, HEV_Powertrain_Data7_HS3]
BO_ 602 HEV_Powertrain_Data_HS3: 8 GWM
 SG_ HtrnWarnLamp_B_Dsply : 3|1@0+ (1,0) [0|1] "SED"  APIM_CDC,APIM_CIM,IPC
 SG_ HybPwLimOn_B_Stat : 7|1@0+ (1,0) [0|1] "SED" Vector__XXX
 SG_ PwSrcULoMde_D_Rq : 38|2@0+ (1,0) [0|3] "SED" Vector__XXX
 SG_ PwSrcUHi_U_Cmd : 55|10@0+ (0.5,0) [0|511.5] "volt" Vector__XXX
 SG_ PtcHtrRun_B_Rq : 0|1@0+ (1,0) [0|1] "SED" Vector__XXX
 SG_ CoolFan_D_Rq : 30|5@0+ (1,0) [0|31] "unitless" Vector__XXX
 SG_ PwPckTqRdy_B_Dsply : 31|1@0+ (1,0) [0|1] "SED"  APIM_CDC,APIM,APIM_CISM,APIM_CIM,IPC
 SG_ HtrnAin_N_RqMxPrtct : 36|13@0+ (2,0) [0|16382] "RPM" Vector__XXX
 SG_ ObdEngStdy_B_Stat : 1|1@0+ (1,0) [0|1] "SED" Vector__XXX
 SG_ EngStrtSrvc_B_Allw : 2|1@0+ (1,0) [0|1] "SED" Vector__XXX
 SG_ BattTracRsrvSoc_Pc_Rq : 15|14@0+ (0.01,0) [0|163.81] "percent" Vector__XXX

BO_ 92 Gear_Shift_by_Wire_3_HS3: 8 GWM
 SG_ TrnGearMsgTxt2_D_Rq : 53|5@0+ (1,0) [0|31] "SED"  APIM_CDC,IPC,APIM_CIM
 SG_ RaceTrakMde_D_Stat : 55|2@0+ (1,0) [0|3] "SED" Vector__XXX
 SG_ TrnLvrV_D_Rq : 43|2@0+ (1,0) [0|3] "SED" Vector__XXX
 SG_ TrnSbwSysHlth_D_Actl : 1|2@0+ (1,0) [0|3] "SED" Vector__XXX
 SG_ TrnDtpCmd_D_Actl : 46|3@0+ (1,0) [0|7] "SED" Vector__XXX
 SG_ TrnGearNtmAllow_B_Stat : 47|1@0+ (1,0) [0|1] "SED"  APIM_CDC,APIM,APIM_CISM,APIM_CIM,IPC
 SG_ GearSelLck_D_Rq : 41|2@0+ (1,0) [0|3] "SED" Vector__XXX
 SG_ TrnGearCmd_No_Cs : 31|8@0+ (1,0) [0|255] "unitless" Vector__XXX
 SG_ TrnValidGear_D_Cnfm : 11|2@0+ (1,0) [0|3] "SED" Vector__XXX
 SG_ TrnNtrlTowCmd_D_Actl : 6|2@0+ (1,0) [0|3] "SED" Vector__XXX
 SG_ TrnGearCmd_Pc_ActlPt : 9|10@0+ (0.1,0) [0|102.2] "percent duty cycle" Vector__XXX
 SG_ TrnGear_D_RqPt : 4|3@0+ (1,0) [0|7] "SED" Vector__XXX
 SG_ TrnCmdState_B_Actl : 39|1@0+ (1,0) [0|1] "SED" Vector__XXX
 SG_ TrnCmdCnt_B_Actl : 7|1@0+ (1,0) [0|1] "unitless" Vector__XXX
 SG_ PrkBrkActv_D_RqTrnGear : 38|2@0+ (1,0) [0|3] "SED" Vector__XXX
 SG_ TrnGearMsgTxt_D_Rq : 36|5@0+ (1,0) [0|31] "SED"  APIM_CDC,APIM,APIM_CIM,IPC
 SG_ TrnGearCmd_No_Cnt : 15|4@0+ (1,0) [0|15] "unitless" Vector__XXX

BO_ 1156 HEV_Powertrain_Data7_HS3: 8 GWM
 SG_ RngPerChrgAvg_L2_Dsply : 46|13@0+ (0.1,0) [0|818.9] "km"  APIM_CDC,APIM,APIM_CISM,APIM_CIM,IPC
 SG_ RngImpctDrv_L_Dsply : 39|9@0+ (1,-255) [-255|256] "km"  APIM_CDC,APIM_CIM,IPC
 SG_ RngImpctClim_L_Dsply : 16|9@0+ (1,-255) [-255|256] "km"  APIM_CDC,APIM_CIM,IPC
 SG_ VehElEffAvg_No_Dsply : 23|7@0+ (10,-100) [-100|1150] "wattHr/km"  APIM_CDC,APIM,APIM_CISM,IPC,APIM_CIM
 SG_ PwFlwFuelDrv_D_Dsply : 15|3@0+ (1,0) [0|7] "SED"  APIM_CDC,APIM,APIM_CISM,APIM_CIM
 SG_ PwFlwFuelClimt_B_Dsply : 0|1@0+ (1,0) [0|1] "SED"  APIM_CDC,APIM,APIM_CISM,APIM_CIM
 SG_ PwFlwFuelBatt_B_Dsply : 1|1@0+ (1,0) [0|1] "SED"  APIM_CDC,APIM,APIM_CISM,APIM_CIM
 SG_ PwFlwBattGen_D_Dsply : 2|1@0+ (1,0) [0|1] "SED"  APIM_CDC,APIM,APIM_CISM,APIM_CIM
 SG_ PwFlwBattClimt_B_Dsply : 3|1@0+ (1,0) [0|1] "SED"  APIM_CDC,APIM,APIM_CISM,APIM_CIM
 SG_ PwFlwBatt_D_Dsply : 7|4@0+ (1,0) [0|15] "SED"  APIM_CDC,APIM,APIM_CISM,APIM_CIM

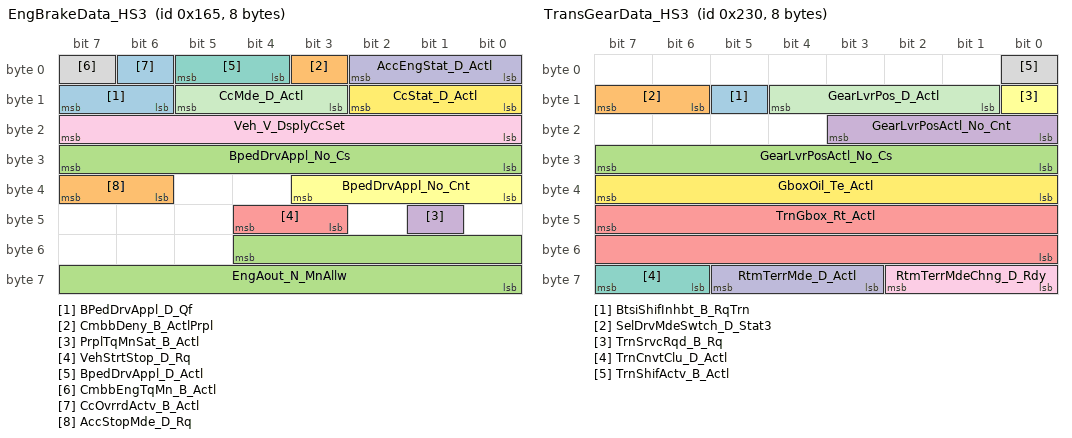
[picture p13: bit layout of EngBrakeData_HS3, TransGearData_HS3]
BO_ 357 EngBrakeData_HS3: 8 GWM
 SG_ BPedDrvAppl_D_Qf : 15|2@0+ (1,0) [0|3] "SED" Vector__XXX
 SG_ CmbbDeny_B_ActlPrpl : 3|1@0+ (1,0) [0|1] "SED" Vector__XXX
 SG_ BpedDrvAppl_No_Cs : 31|8@0+ (1,0) [0|255] "unitless" Vector__XXX
 SG_ PrplTqMnSat_B_Actl : 41|1@0+ (1,0) [0|1] "SED" Vector__XXX
 SG_ VehStrtStop_D_Rq : 44|2@0+ (1,0) [0|3] "SED" Vector__XXX
 SG_ BpedDrvAppl_No_Cnt : 35|4@0+ (1,0) [0|15] "unitless" Vector__XXX
 SG_ BpedDrvAppl_D_Actl : 5|2@0+ (1,0) [0|3] "SED"  APIM_CDC,APIM,APIM_CISM,APIM_CIM,IPC,TRM_ITRM
 SG_ CmbbEngTqMn_B_Actl : 7|1@0+ (1,0) [0|1] "SED" Vector__XXX
 SG_ Veh_V_DsplyCcSet : 23|8@0+ (1,0) [0|253] "unitless"  APIM_CDC,APIM_CIM,HUD_ADV,IPC
 SG_ AccEngStat_D_Actl : 2|3@0+ (1,0) [0|7] "SED" Vector__XXX
 SG_ CcMde_D_Actl : 13|3@0+ (1,0) [0|7] "SED" Vector__XXX
 SG_ CcStat_D_Actl : 10|3@0+ (1,0) [0|7] "SED"  APIM_CDC,APIM_CIM,IPC,HUD_ADV
 SG_ CcOvrrdActv_B_Actl : 6|1@0+ (1,0) [0|1] "SED"  APIM_CDC,APIM_CIM,HUD_ADV,IPC
 SG_ AccStopMde_D_Rq : 39|2@0+ (1,0) [0|3] "SED" Vector__XXX
 SG_ EngAout_N_MnAllw : 52|13@0+ (2,0) [0|16382] "rpm" Vector__XXX

BO_ 1100 PowertrainData_9_HS3: 8 GWM
 SG_ RearDiffLckLamp_D_Rq2 : 21|2@0+ (1,0) [0|3] "SED"  APIM_CDC,APIM_CIM,IPC
 SG_ RvltnMatchAllw_D_Stat : 41|2@0+ (1,0) [0|3] "SED"  APIM_CDC,APIM_CIM,IPC
 SG_ WakeAlarm1_T_Rq : 55|15@0+ (1,0) [0|32767] "minute" Vector__XXX
 SG_ WakeAlarm1_B_Typ : 56|1@0+ (1,0) [0|1] "SED" Vector__XXX
 SG_ TrnNtrlIdlExit_B_Rq : 38|1@0+ (1,0) [0|1] "SED" Vector__XXX
 SG_ Veh_V_DsplyTrailCtlSet : 47|6@0+ (0.5,0) [0|31] "unitless"  APIM_CDC,HUD_ADV,APIM_CIM,IPC
 SG_ TrailCtlPt_B_Falt : 36|2@0+ (1,0) [0|3] "SED" Vector__XXX
 SG_ TrnNtrlIdlInhbt_B_Rq : 37|1@0+ (1,0) [0|1] "SED" Vector__XXX
 SG_ AutoTowAllw_D_StatMnu : 25|2@0+ (1,0) [0|3] "SED"  APIM_CDC,APIM_CIM,IPC
 SG_ AutoTowActv_B_Stat : 39|1@0+ (1,0) [0|1] "SED"  APIM_CDC,APIM_CIM,IPC
 SG_ SpareTireDetct_B_Stat : 30|1@0+ (1,0) [0|1] "SED" Vector__XXX
 SG_ RearDiffSumpOil_Te_Est : 15|8@0+ (1,-40) [-40|213] "degC" Vector__XXX
 SG_ RearDiffMtrRun_B_Stat : 31|1@0+ (1,0) [0|1] "SED" Vector__XXX
 SG_ EngTrlrCnnct_D_Stat : 23|2@0+ (1,0) [0|3] "SED" Vector__XXX
 SG_ GrossTrainWeight_M_Est : 7|8@0+ (100,0) [0|25300] "kilogram" Vector__XXX
 SG_ SuspVlimMsgTxt_B_Rq : 29|1@0+ (1,0) [0|1] "SED"  APIM_CDC,APIM_CIM,IPC
 SG_ RearDiffLckMsg2_D_Rq : 19|4@0+ (1,0) [0|15] "SED"  APIM_CDC,APIM_CIM,IPC
 SG_ EngExhMdeQuiet_D2_Stat : 28|3@0+ (1,0) [0|7] "SED"  APIM_CDC,APIM,APIM_CISM,ACM,APIM_CIM,IPC
 SG_ HvacCmprLim_D_Stat : 34|3@0+ (1,0) [0|7] "SED" Vector__XXX

BO_ 1152 HEV_Powertrain_Data6_HS3: 8 GWM
 SG_ PwCabinEnblScnd_B_Rq : 28|1@0+ (1,0) [0|1] "SED" Vector__XXX
 SG_ PwCabinEnbl_B_Rq : 29|1@0+ (1,0) [0|1] "SED" Vector__XXX
 SG_ PwTrnkFrntEnblScnd_B_Rq : 30|1@0+ (1,0) [0|1] "SED" Vector__XXX
 SG_ PwTrnkFrntEnbl_B_Rq : 31|1@0+ (1,0) [0|1] "SED" Vector__XXX
 SG_ PwOutlet8EnblScnd_B_Rq : 16|1@0+ (1,0) [0|1] "SED" Vector__XXX
 SG_ PwOutlet8Enbl_B_Rq : 17|1@0+ (1,0) [0|1] "SED" Vector__XXX
 SG_ PwOutlet7EnblScnd_B_Rq : 18|1@0+ (1,0) [0|1] "SED" Vector__XXX
 SG_ PwOutlet7Enbl_B_Rq : 19|1@0+ (1,0) [0|1] "SED" Vector__XXX
 SG_ PwOutlet6EnblScnd_B_Rq : 20|1@0+ (1,0) [0|1] "SED" Vector__XXX
 SG_ PwOutlet6Enbl_B_Rq : 21|1@0+ (1,0) [0|1] "SED" Vector__XXX
 SG_ HybPwULoLamp_B_Rq : 22|1@0+ (1,0) [0|1] "SED" Vector__XXX
 SG_ StopStrtVThres_D_Stat : 1|2@0+ (1,0) [0|3] "SED"  APIM_CDC,APIM,APIM_CIM,IPC
 SG_ GrdAsstActv_B_Stat : 8|1@0+ (1,0) [0|1] "SED"  APIM_CDC,APIM_CIM,IPC
 SG_ EngTeHi_B_Actl : 5|1@0+ (1,0) [0|1] "SED" Vector__XXX
 SG_ DcdcOn_B_Rq : 6|1@0+ (1,0) [0|1] "SED" Vector__XXX
 SG_ ULoBattSpprtSustn_B_Rq : 7|1@0+ (1,0) [0|1] "SED" Vector__XXX
 SG_ OnePdlDrv_D_Dsply : 4|2@0+ (1,0) [0|3] "SED"  APIM_CDC,APIM,APIM_CISM,APIM_CIM,IPC
 SG_ OnePdlDrvLamp_B_Rq : 23|1@0+ (1,0) [0|1] "SED"  APIM_CDC,APIM_CIM,IPC
 SG_ BattTracDiagClr_B_Stat : 2|1@0+ (1,0) [0|1] "SED" Vector__XXX
 SG_ VehElEff_No_Avg : 15|7@0+ (10,-100) [-100|1150] "watt*hr/km" Vector__XXX

BO_ 839 FuelOpHeater_Stat_HS3: 8 GWM
 SG_ FohStop_B_Stat : 49|2@0+ (1,0) [0|3] "SED"  APIM_CDC,APIM_CIM
 SG_ FohMsgTxt_D_Rq : 4|3@0+ (1,0) [0|7] "SED"  APIM_CDC,APIM_CIM
 SG_ FohKeyOff_B_Rq : 6|1@0+ (1,0) [0|1] "SED"  APIM_CDC,APIM_CIM
 SG_ FohEnbl_B_Rq : 7|1@0+ (1,0) [0|1] "SED"  APIM_CDC,APIM_CIM
 SG_ FohTAllEnable_B_Stat : 17|2@0+ (1,0) [0|3] "SED"  APIM_CDC,APIM_CIM
 SG_ FohT2Mnte_T_Stat : 55|6@0+ (1,0) [0|63] "minute"  APIM_CDC,APIM_CIM
 SG_ FohT2Hr_T_Stat : 47|5@0+ (1,0) [0|31] "hour"  APIM_CDC,APIM_CIM
 SG_ FohT2Enable_B_Stat : 63|1@0+ (1,0) [0|1] "SED"  APIM_CDC,APIM_CIM
 SG_ FohT1Mnte_T_Stat : 39|6@0+ (1,0) [0|63] "minute"  APIM_CDC,APIM_CIM
 SG_ FohT1Hr_T_Stat : 31|5@0+ (1,0) [0|31] "hour"  APIM_CDC,APIM_CIM
 SG_ FohT1Enable_B_Stat : 0|1@0+ (1,0) [0|1] "SED"  APIM_CDC,APIM_CIM
 SG_ FohStrtMnte_T_Stat : 23|6@0+ (1,0) [0|63] "minute"  APIM_CDC,APIM_CIM
 SG_ FohStrtHr_T_Stat : 15|5@0+ (1,0) [0|31] "hour"  APIM_CDC,APIM_CIM
 SG_ FohStrtEnable_B_Stat : 1|1@0+ (1,0) [0|1] "SED"  APIM_CDC,APIM_CIM
 SG_ FohContOn_B_Stat : 33|2@0+ (1,0) [0|3] "SED"  APIM_CDC,APIM_CIM
 SG_ FohStrtDay_T_Stat : 10|3@0+ (1,0) [0|7] "SED"  APIM_CDC,APIM_CIM
 SG_ FohT2Wednesday_T_Stat : 56|1@0+ (1,0) [0|1] "SED"  APIM_CDC,APIM_CIM
 SG_ FohT2Tuesday_T_Stat : 57|1@0+ (1,0) [0|1] "SED"  APIM_CDC,APIM_CIM
 SG_ FohT2Thursday_T_Stat : 58|1@0+ (1,0) [0|1] "SED"  APIM_CDC,APIM_CIM
 SG_ FohT2Sunday_T_Stat : 59|1@0+ (1,0) [0|1] "SED"  APIM_CDC,APIM_CIM
 SG_ FohT2Saturday_T_Stat : 60|1@0+ (1,0) [0|1] "SED"  APIM_CDC,APIM_CIM
 SG_ FohT2Monday_T_Stat : 61|1@0+ (1,0) [0|1] "SED"  APIM_CDC,APIM_CIM
 SG_ FohT2Friday_T_Stat : 62|1@0+ (1,0) [0|1] "SED"  APIM_CDC,APIM_CIM
 SG_ FohT1Wednesday_T_Stat : 40|1@0+ (1,0) [0|1] "SED"  APIM_CDC,APIM_CIM
 SG_ FohT1Tuesday_T_Stat : 41|1@0+ (1,0) [0|1] "SED"  APIM_CDC,APIM_CIM
 SG_ FohT1Thursday_T_Stat : 42|1@0+ (1,0) [0|1] "SED"  APIM_CDC,APIM_CIM
 SG_ FohT1Sunday_T_Stat : 24|1@0+ (1,0) [0|1] "SED"  APIM_CDC,APIM_CIM
 SG_ FohT1Saturday_T_Stat : 25|1@0+ (1,0) [0|1] "SED"  APIM_CDC,APIM_CIM
 SG_ FohT1Monday_T_Stat : 26|1@0+ (1,0) [0|1] "SED"  APIM_CDC,APIM_CIM
 SG_ FohT1Friday_T_Stat : 5|1@0+ (1,0) [0|1] "SED"  APIM_CDC,APIM_CIM

BO_ 2612224064 PARSEDPushWCMtoGWM_ECG: 8 WCM
 SG_ PARSEDPushWCMtoGWM_ECG : 7|29@0+ (1,0) [0|536870911] "unitless"  GWM

BO_ 2612068568 PARSEDPushFcGWM_ECGtoWCM: 8 GWM
 SG_ PARSEDPushFcGWM_ECGtoWCM : 7|29@0+ (1,0) [0|536870911] "unitless"  WCM

BO_ 2611175488 PARSEDPhysWCMtoGWM_ECG: 8 WCM
 SG_ PARSEDPhysWCMtoGWM_ECG : 7|29@0+ (1,0) [0|536870911] "unitless"  GWM

BO_ 2611019992 PARSEDPhysGWM_ECGtoWCM: 8 GWM
 SG_ PARSEDPhysGWM_ECGtoWCM : 7|29@0+ (1,0) [0|536870911] "unitless"  WCM

BO_ 2610126912 OTAPhysWCMtoGWM_ECG: 8 WCM
 SG_ OTAPhysWCMtoGWM_ECG : 7|29@0+ (1,0) [0|536870911] "unitless"  GWM

BO_ 2609971416 OTAPhysGWM_ECGtoWCM: 8 GWM
 SG_ OTAPhysGWM_ECGtoWCM : 7|29@0+ (1,0) [0|536870911] "unitless"  WCM

BO_ 652 TCUB_Send_Signals_HS3: 8 GWM
 SG_ TelematicsSrvc_D_St2 : 7|3@0+ (1,0) [0|7] "SED"  APIM_CDC,APIM,APIM_CISM,APIM_CIM

BO_ 560 TransGearData_HS3: 8 GWM
 SG_ BtsiShifInhbt_B_RqTrn : 13|1@0+ (1,0) [0|1] "SED" Vector__XXX
 SG_ SelDrvMdeSwtch_D_Stat3 : 15|2@0+ (1,0) [0|3] "SED" Vector__XXX
 SG_ GearLvrPosActl_No_Cs : 31|8@0+ (1,0) [0|255] "unitless"  TRM_ITRM
 SG_ GearLvrPosActl_No_Cnt : 19|4@0+ (1,0) [0|15] "unitless"  TRM_ITRM
 SG_ TrnGbox_Rt_Actl : 47|16@0+ (0.001,0) [0|65.533] "unitless" Vector__XXX
 SG_ TrnSrvcRqd_B_Rq : 8|1@0+ (1,0) [0|1] "SED"  APIM_CDC,APIM_CIM,IPC
 SG_ TrnCnvtClu_D_Actl : 63|2@0+ (1,0) [0|3] "SED" Vector__XXX
 SG_ TrnShifActv_B_Actl : 0|1@0+ (1,0) [0|1] "SED" Vector__XXX
 SG_ RtmTerrMdeChng_D_Rdy : 58|3@0+ (1,0) [0|7] "SED" Vector__XXX
 SG_ RtmTerrMde_D_Actl : 61|3@0+ (1,0) [0|7] "SED" Vector__XXX
 SG_ GearLvrPos_D_Actl : 12|4@0+ (1,0) [0|15] "SED"  APIM_CDC,APIM,APIM_CISM,ACM,DSP,APIM_CIM,IPC,TRM_ITRM
 SG_ GboxOil_Te_Actl : 39|8@0+ (1,-60) [-60|193] "degC"  APIM_CDC,APIM,APIM_CIM,APIM_CISM,IPC

BO_ 1153 All_Terrain_Data_HS3: 8 GWM
 SG_ TerrStat_D_RqDsply : 7|4@0+ (1,0) [0|15] "SED"  GENERIC
 SG_ TerrMde_D_RqDrv : 3|3@0+ (1,0) [0|7] "SED" Vector__XXX

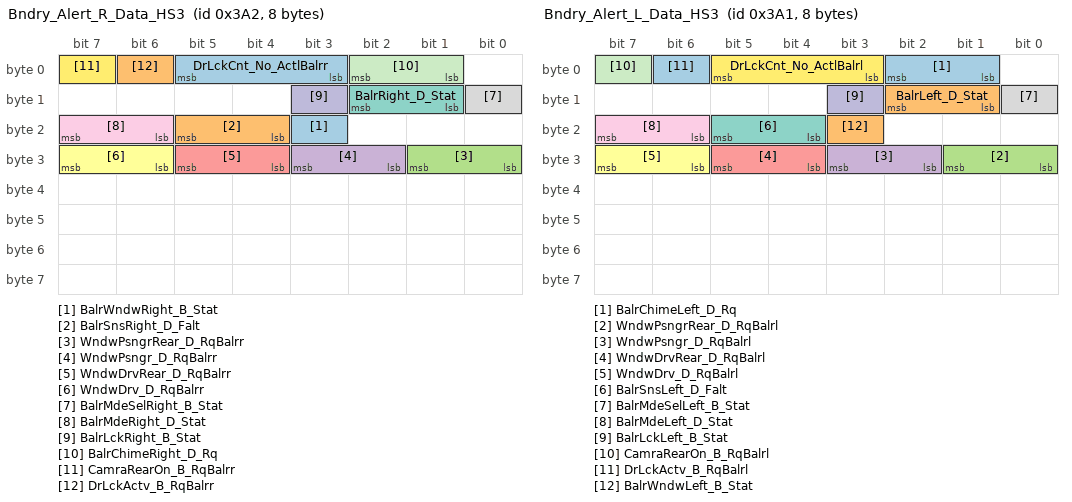
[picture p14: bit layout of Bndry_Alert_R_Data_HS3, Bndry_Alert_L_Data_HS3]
BO_ 930 Bndry_Alert_R_Data_HS3: 8 GWM
 SG_ BalrWndwRight_B_Stat : 19|1@0+ (1,0) [0|1] "SED"  APIM_CDC,IPC,APIM_CIM
 SG_ BalrSnsRight_D_Falt : 21|2@0+ (1,0) [0|3] "SED"  APIM_CDC,IPC,APIM_CIM
 SG_ WndwPsngrRear_D_RqBalrr : 25|2@0+ (1,0) [0|3] "SED" Vector__XXX
 SG_ WndwPsngr_D_RqBalrr : 27|2@0+ (1,0) [0|3] "SED" Vector__XXX
 SG_ WndwDrvRear_D_RqBalrr : 29|2@0+ (1,0) [0|3] "SED" Vector__XXX
 SG_ WndwDrv_D_RqBalrr : 31|2@0+ (1,0) [0|3] "SED" Vector__XXX
 SG_ BalrRight_D_Stat : 10|2@0+ (1,0) [0|3] "SED"  APIM_CDC,IPC,APIM_CIM
 SG_ BalrMdeSelRight_B_Stat : 8|1@0+ (1,0) [0|1] "SED"  APIM_CDC,IPC,APIM_CIM
 SG_ BalrMdeRight_D_Stat : 23|2@0+ (1,0) [0|3] "SED"  APIM_CDC,IPC,APIM_CIM
 SG_ BalrLckRight_B_Stat : 11|1@0+ (1,0) [0|1] "SED"  APIM_CDC,IPC,APIM_CIM
 SG_ BalrChimeRight_D_Rq : 2|2@0+ (1,0) [0|3] "SED"  APIM_CDC,IPC,APIM_CIM
 SG_ CamraRearOn_B_RqBalrr : 7|1@0+ (1,0) [0|1] "SED"  APIM_CDC,APIM,APIM_CISM,APIM_CIM,ACM,TRM_ITRM
 SG_ DrLckCnt_No_ActlBalrr : 5|3@0+ (1,0) [0|7] "unitless" Vector__XXX
 SG_ DrLckActv_B_RqBalrr : 6|1@0+ (1,0) [0|1] "SED" Vector__XXX

BO_ 929 Bndry_Alert_L_Data_HS3: 8 GWM
 SG_ BalrChimeLeft_D_Rq : 2|2@0+ (1,0) [0|3] "SED"  APIM_CDC,IPC,APIM_CIM
 SG_ BalrLeft_D_Stat : 10|2@0+ (1,0) [0|3] "SED"  APIM_CDC,IPC,APIM_CIM
 SG_ WndwPsngrRear_D_RqBalrl : 25|2@0+ (1,0) [0|3] "SED" Vector__XXX
 SG_ WndwPsngr_D_RqBalrl : 27|2@0+ (1,0) [0|3] "SED" Vector__XXX
 SG_ WndwDrvRear_D_RqBalrl : 29|2@0+ (1,0) [0|3] "SED" Vector__XXX
 SG_ WndwDrv_D_RqBalrl : 31|2@0+ (1,0) [0|3] "SED" Vector__XXX
 SG_ BalrSnsLeft_D_Falt : 21|2@0+ (1,0) [0|3] "SED"  APIM_CDC,IPC,APIM_CIM
 SG_ BalrMdeSelLeft_B_Stat : 8|1@0+ (1,0) [0|1] "SED"  APIM_CDC,IPC,APIM_CIM
 SG_ BalrMdeLeft_D_Stat : 23|2@0+ (1,0) [0|3] "SED"  APIM_CDC,IPC,APIM_CIM
 SG_ BalrLckLeft_B_Stat : 11|1@0+ (1,0) [0|1] "SED"  APIM_CDC,IPC,APIM_CIM
 SG_ CamraRearOn_B_RqBalrl : 7|1@0+ (1,0) [0|1] "SED"  APIM_CDC,APIM,APIM_CISM,APIM_CIM,ACM,TRM_ITRM
 SG_ DrLckCnt_No_ActlBalrl : 5|3@0+ (1,0) [0|7] "unitless" Vector__XXX
 SG_ DrLckActv_B_RqBalrl : 6|1@0+ (1,0) [0|1] "SED" Vector__XXX
 SG_ BalrWndwLeft_B_Stat : 19|1@0+ (1,0) [0|1] "SED"  APIM_CDC,IPC,APIM_CIM

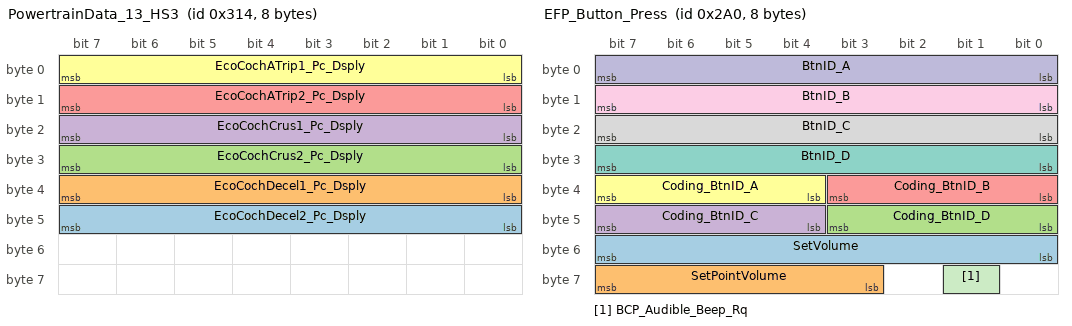
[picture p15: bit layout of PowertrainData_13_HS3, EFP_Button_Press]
BO_ 788 PowertrainData_13_HS3: 8 GWM
 SG_ EcoCochDecel2_Pc_Dsply : 47|8@0+ (0.392157,0) [0|100.000035] "percent"  APIM_CDC,APIM,APIM_CIM,APIM_CISM
 SG_ EcoCochDecel1_Pc_Dsply : 39|8@0+ (0.392157,0) [0|100.000035] "percent"  APIM_CDC,APIM,APIM_CIM,APIM_CISM
 SG_ EcoCochCrus2_Pc_Dsply : 31|8@0+ (0.392157,0) [0|100.000035] "percent"  APIM_CDC,APIM,APIM_CIM,APIM_CISM
 SG_ EcoCochCrus1_Pc_Dsply : 23|8@0+ (0.392157,0) [0|100.000035] "percent"  APIM_CDC,APIM,APIM_CIM,APIM_CISM
 SG_ EcoCochATrip2_Pc_Dsply : 15|8@0+ (0.392157,0) [0|100.000035] "percent"  APIM_CDC,APIM,APIM_CIM,APIM_CISM
 SG_ EcoCochATrip1_Pc_Dsply : 7|8@0+ (0.392157,0) [0|100.000035] "percent"  APIM_CDC,APIM,APIM_CIM,APIM_CISM

BO_ 391 ACU_Request_Signals_3: 8 ACM
 SG_ ACU_CtrlChimeChan_Rq : 7|2@0+ (1,0) [0|3] "SED"  DSP

BO_ 670 Driver_Dr_Stat2_HS3: 8 GWM
 SG_ DrHandleOuterRl_D_Stat : 4|3@0+ (1,0) [0|7] "SED"  APIM_CDC,APIM_CIM,IPC
 SG_ DrHandleOuterFl_D_Stat : 7|3@0+ (1,0) [0|7] "SED"  APIM_CDC,APIM_CIM,IPC

BO_ 672 EFP_Button_Press: 8 FCIMB
 SG_ SetVolume : 55|8@0+ (1,-30) [-30|30] "unitless"  APIM_CDC,APIM,APIM_CISM,GWM,APIM_CIM,DSP,ACM
 SG_ SetPointVolume : 63|5@0+ (1,0) [0|31] "unitless"  APIM_CDC,APIM,APIM_CISM,GWM,APIM_CIM,DSP,ACM
 SG_ Coding_BtnID_D : 43|4@0+ (1,0) [0|15] "SED"  APIM_CDC,APIM,APIM_CISM,APIM_CIM,ACM
 SG_ Coding_BtnID_C : 47|4@0+ (1,0) [0|15] "SED"  APIM_CDC,APIM,APIM_CISM,APIM_CIM,ACM
 SG_ Coding_BtnID_B : 35|4@0+ (1,0) [0|15] "SED"  APIM_CDC,APIM,APIM_CISM,APIM_CIM,ACM
 SG_ Coding_BtnID_A : 39|4@0+ (1,0) [0|15] "SED"  APIM_CDC,APIM,APIM_CISM,APIM_CIM,ACM
 SG_ BtnID_D : 31|8@0+ (1,0) [0|255] "unitless"  APIM_CDC,APIM,APIM_CISM,APIM_CIM,ACM
 SG_ BtnID_C : 23|8@0+ (1,0) [0|255] "unitless"  APIM_CDC,APIM,APIM_CISM,APIM_CIM,ACM
 SG_ BtnID_B : 15|8@0+ (1,0) [0|255] "unitless"  APIM_CDC,APIM,APIM_CISM,APIM_CIM,ACM
 SG_ BtnID_A : 7|8@0+ (1,0) [0|255] "unitless"  APIM_CDC,APIM,APIM_CISM,APIM_CIM,ACM
 SG_ BCP_Audible_Beep_Rq : 57|1@0+ (1,0) [0|1] "SED"  APIM_CDC,APIM_CISM,APIM_CIM,ACM,DSP

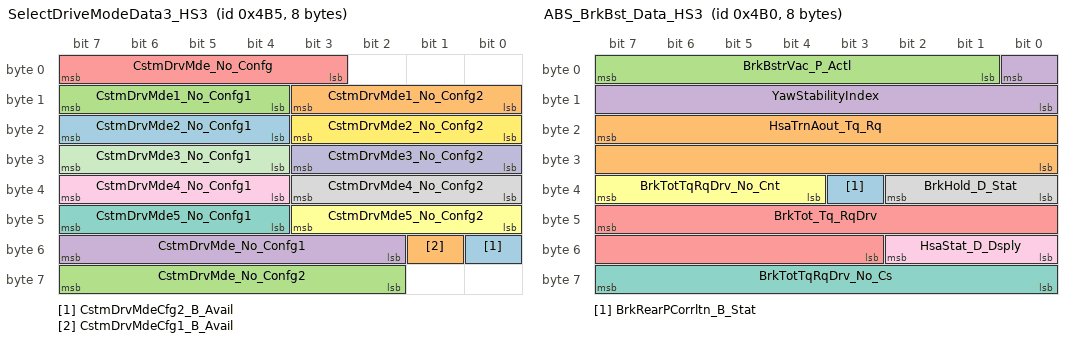
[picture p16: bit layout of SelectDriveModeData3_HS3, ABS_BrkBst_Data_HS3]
BO_ 1205 SelectDriveModeData3_HS3: 8 GWM
 SG_ CstmDrvMdeCfg2_B_Avail : 48|1@0+ (1,0) [0|1] "SED"  APIM_CDC,APIM_CIM,IPC
 SG_ CstmDrvMdeCfg1_B_Avail : 49|1@0+ (1,0) [0|1] "SED"  APIM_CDC,APIM_CIM,IPC
 SG_ CstmDrvMde_No_Confg2 : 63|6@0+ (1,0) [0|63] "unitless"  APIM_CDC,APIM_CIM,IPC
 SG_ CstmDrvMde_No_Confg1 : 55|6@0+ (1,0) [0|63] "unitless"  APIM_CDC,APIM_CIM,IPC
 SG_ CstmDrvMde_No_Confg : 7|5@0+ (1,0) [0|31] "unitless"  APIM_CDC,APIM_CIM,IPC
 SG_ CstmDrvMde5_No_Confg2 : 43|4@0+ (1,0) [0|15] "unitless"  APIM_CDC,APIM_CIM,IPC
 SG_ CstmDrvMde5_No_Confg1 : 47|4@0+ (1,0) [0|15] "unitless"  APIM_CDC,APIM_CIM,IPC
 SG_ CstmDrvMde4_No_Confg2 : 35|4@0+ (1,0) [0|15] "unitless"  APIM_CDC,APIM_CIM,IPC
 SG_ CstmDrvMde4_No_Confg1 : 39|4@0+ (1,0) [0|15] "unitless"  APIM_CDC,APIM_CIM,IPC
 SG_ CstmDrvMde3_No_Confg2 : 27|4@0+ (1,0) [0|15] "unitless"  APIM_CDC,APIM_CIM,IPC
 SG_ CstmDrvMde3_No_Confg1 : 31|4@0+ (1,0) [0|15] "unitless"  APIM_CDC,APIM_CIM,IPC
 SG_ CstmDrvMde2_No_Confg2 : 19|4@0+ (1,0) [0|15] "unitless"  APIM_CDC,APIM_CIM,IPC
 SG_ CstmDrvMde2_No_Confg1 : 23|4@0+ (1,0) [0|15] "unitless"  APIM_CDC,APIM_CIM,IPC
 SG_ CstmDrvMde1_No_Confg2 : 11|4@0+ (1,0) [0|15] "unitless"  APIM_CDC,APIM_CIM,IPC
 SG_ CstmDrvMde1_No_Confg1 : 15|4@0+ (1,0) [0|15] "unitless"  APIM_CDC,APIM_CIM,IPC

BO_ 1200 ABS_BrkBst_Data_HS3: 8 GWM
 SG_ BrkRearPCorrltn_B_Stat : 35|1@0+ (1,0) [0|1] "SED" Vector__XXX
 SG_ HsaTrnAout_Tq_Rq : 23|16@0+ (4,-131072) [-131072|131060] "Nm" Vector__XXX
 SG_ BrkBstrVac_P_Actl : 7|7@0+ (8,0) [0|1008] "millibar" Vector__XXX
 SG_ YawStabilityIndex : 0|9@0+ (1,-256) [-256|255] "%" Vector__XXX
 SG_ BrkTot_Tq_RqDrv : 47|13@0+ (4,0) [0|32760] "Nm"  APIM,APIM_CISM,APIM_CIM
 SG_ BrkTotTqRqDrv_No_Cnt : 39|4@0+ (1,0) [0|15] "unitless" Vector__XXX
 SG_ BrkTotTqRqDrv_No_Cs : 63|8@0+ (1,0) [0|255] "unitless" Vector__XXX
 SG_ BrkHold_D_Stat : 34|3@0+ (1,0) [0|7] "SED" Vector__XXX
 SG_ HsaStat_D_Dsply : 50|3@0+ (1,0) [0|7] "SED" Vector__XXX

BO_ 593 ECG_MC_WORD_Tx: 8 GWM
 SG_ ECG_MC_WORD_Tx : 7|64@0+ (1,0) [0|1.84467440737096E+019] "unitless"  APIM_CDC,IPC

BO_ 601 ECG_MC_WORD_Rx: 8 IPC
 SG_ ECG_MC_WORD_Rx : 7|64@0+ (1,0) [0|1.84467440737096E+019] "unitless"  GWM

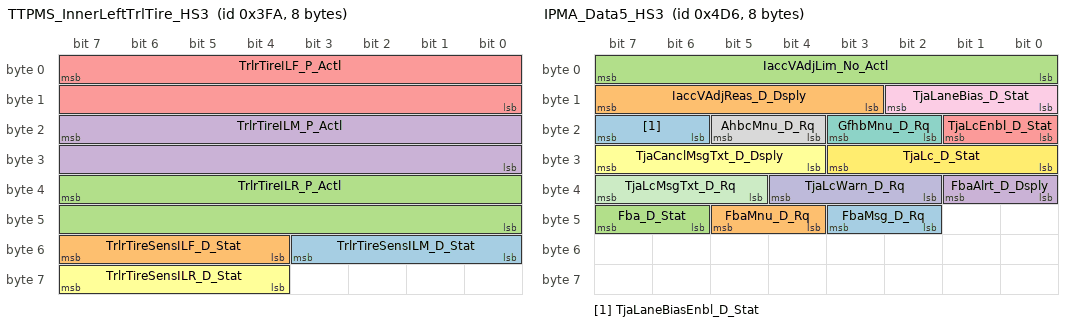
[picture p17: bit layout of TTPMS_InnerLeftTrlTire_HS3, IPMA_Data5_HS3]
BO_ 1018 TTPMS_InnerLeftTrlTire_HS3: 8 GWM
 SG_ TrlrTireSensILM_D_Stat : 51|4@0+ (1,0) [0|15] "SED"  APIM_CDC,APIM,APIM_CISM,APIM_CIM,IPC
 SG_ TrlrTireSensILF_D_Stat : 55|4@0+ (1,0) [0|15] "SED"  APIM_CDC,APIM,APIM_CISM,APIM_CIM,IPC
 SG_ TrlrTireILR_P_Actl : 39|16@0+ (1,0) [0|65533] "kilopascal"  APIM_CDC,APIM,APIM_CISM,APIM_CIM,IPC
 SG_ TrlrTireILM_P_Actl : 23|16@0+ (1,0) [0|65533] "kilopascal"  APIM_CDC,APIM,APIM_CISM,APIM_CIM,IPC
 SG_ TrlrTireILF_P_Actl : 7|16@0+ (1,0) [0|65533] "kilopascal"  APIM_CDC,APIM,APIM_CISM,APIM_CIM,IPC
 SG_ TrlrTireSensILR_D_Stat : 63|4@0+ (1,0) [0|15] "SED"  APIM_CDC,APIM,APIM_CISM,APIM_CIM,IPC

BO_ 1238 IPMA_Data5_HS3: 8 GWM
 SG_ FbaMsg_D_Rq : 43|2@0+ (1,0) [0|3] "SED"  IPC
 SG_ FbaMnu_D_Rq : 45|2@0+ (1,0) [0|3] "SED"  APIM
 SG_ Fba_D_Stat : 47|2@0+ (1,0) [0|3] "SED"  APIM
 SG_ FbaAlrt_D_Dsply : 33|2@0+ (1,0) [0|3] "SED"  APIM,IPC
 SG_ TjaLcEnbl_D_Stat : 17|2@0+ (1,0) [0|3] "SED"  APIM_CDC,APIM_CIM,APIM_CISM,APIM
 SG_ TjaCanclMsgTxt_D_Dsply : 31|4@0+ (1,0) [0|15] "SED" Vector__XXX
 SG_ GfhbMnu_D_Rq : 19|2@0+ (1,0) [0|3] "SED"  APIM_CDC,APIM,APIM_CIM,IPC,APIM_CISM
 SG_ AhbcMnu_D_Rq : 21|2@0+ (1,0) [0|3] "SED"  APIM_CDC,APIM,APIM_CIM,IPC,APIM_CISM
 SG_ TjaLaneBias_D_Stat : 10|3@0+ (1,0) [0|7] "SED"  APIM_CDC,APIM_CIM,IPC
 SG_ TjaLcWarn_D_Rq : 36|3@0+ (1,0) [0|7] "SED"  HUD_ADV,IPC
 SG_ TjaLcMsgTxt_D_Rq : 39|3@0+ (1,0) [0|7] "SED"  HUD_ADV,IPC
 SG_ TjaLc_D_Stat : 27|4@0+ (1,0) [0|15] "SED"  IPC,HUD_ADV
 SG_ TjaLaneBiasEnbl_D_Stat : 23|2@0+ (1,0) [0|3] "SED"  APIM_CDC,APIM,APIM_CISM,APIM_CIM
 SG_ IaccVAdjReas_D_Dsply : 15|5@0+ (1,0) [0|31] "SED"  APIM_CDC,HUD_ADV,APIM,APIM_CISM,APIM_CIM,IPC
 SG_ IaccVAdjLim_No_Actl : 7|8@0+ (1,0) [0|255] "unitless"  APIM_CDC,HUD_ADV,APIM,APIM_CISM,APIM_CIM,IPC

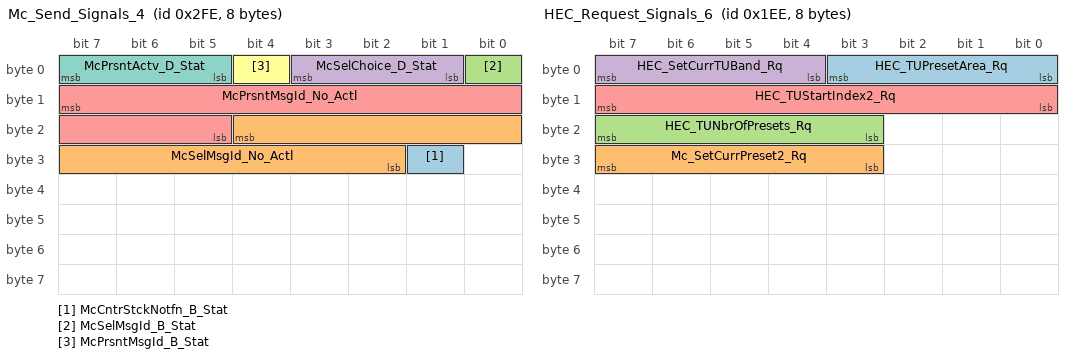
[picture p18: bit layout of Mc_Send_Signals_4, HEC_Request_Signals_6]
BO_ 766 Mc_Send_Signals_4: 8 APIM
 SG_ McCntrStckNotfn_B_Stat : 25|1@0+ (1,0) [0|1] "SED"  IPC
 SG_ McSelMsgId_No_Actl : 20|11@0+ (1,0) [0|2047] "unitless"  IPC
 SG_ McSelMsgId_B_Stat : 0|1@0+ (1,0) [0|1] "SED"  IPC
 SG_ McSelChoice_D_Stat : 3|3@0+ (1,0) [0|7] "SED"  IPC
 SG_ McPrsntMsgId_No_Actl : 15|11@0+ (1,0) [0|2047] "unitless"  IPC
 SG_ McPrsntMsgId_B_Stat : 4|1@0+ (1,0) [0|1] "SED"  IPC
 SG_ McPrsntActv_D_Stat : 7|3@0+ (1,0) [0|7] "SED"  IPC

BO_ 840 FoH_Day_Req: 8 IPC
 SG_ FohAddHeater_D_Rq : 9|2@0+ (1,0) [0|3] "SED"  GWM
 SG_ FohStrtDateYr_No_Rq : 39|8@0+ (1,2000) [2000|2255] "year"  GWM
 SG_ FohStrtDateDay_No_Rq : 23|16@0+ (1,0) [0|65535] "julian day"  GWM
 SG_ FohT2Friday_T_Rq : 0|1@0+ (1,0) [0|1] "SED"  GWM
 SG_ FohT1Friday_T_Rq : 7|1@0+ (1,0) [0|1] "SED"  GWM
 SG_ FohT2Wednesday_T_Rq : 10|1@0+ (1,0) [0|1] "SED"  GWM
 SG_ FohT2Tuesday_T_Rq : 11|1@0+ (1,0) [0|1] "SED"  GWM
 SG_ FohT2Thursday_T_Rq : 12|1@0+ (1,0) [0|1] "SED"  GWM
 SG_ FohT2Sunday_T_Rq : 13|1@0+ (1,0) [0|1] "SED"  GWM
 SG_ FohT2Saturday_T_Rq : 14|1@0+ (1,0) [0|1] "SED"  GWM
 SG_ FohT2Monday_T_Rq : 15|1@0+ (1,0) [0|1] "SED"  GWM
 SG_ FohT1Wednesday_T_Rq : 1|1@0+ (1,0) [0|1] "SED"  GWM
 SG_ FohT1Tuesday_T_Rq : 2|1@0+ (1,0) [0|1] "SED"  GWM
 SG_ FohT1Thursday_T_Rq : 3|1@0+ (1,0) [0|1] "SED"  GWM
 SG_ FohT1Sunday_T_Rq : 4|1@0+ (1,0) [0|1] "SED"  GWM
 SG_ FohT1Saturday_T_Rq : 5|1@0+ (1,0) [0|1] "SED"  GWM
 SG_ FohT1Monday_T_Rq : 6|1@0+ (1,0) [0|1] "SED"  GWM

BO_ 494 HEC_Request_Signals_6: 8 IPC
 SG_ HEC_TUPresetArea_Rq : 3|4@0+ (1,0) [0|15] "SED"  APIM_CISM,ACM
 SG_ Mc_SetCurrPreset2_Rq : 31|5@0+ (1,0) [0|30] "SED"  APIM_CISM,ACM
 SG_ HEC_TUNbrOfPresets_Rq : 23|5@0+ (1,0) [0|30] "unitless"  APIM_CISM,ACM
 SG_ HEC_SetCurrTUBand_Rq : 7|4@0+ (1,0) [0|15] "SED"  APIM_CISM,ACM
 SG_ HEC_TUStartIndex2_Rq : 15|8@0+ (1,0) [0|255] "unitless"  APIM_CISM,ACM

BO_ 714 SDARS_MC_WORD_Rx: 8 IPC
 SG_ SDARS_MC_WORD_Rx : 7|64@0+ (1,0) [0|1.84467440737096E+019] "unitless"  APIM_CISM,ACM

BO_TX_BU_ 803 : APIM_CDC,IPC;
BO_TX_BU_ 802 : APIM_CDC,IPC;
BO_TX_BU_ 1119 : APIM,APIM_CDC,APIM_CISM,APIM_CIM;
BO_TX_BU_ 1118 : APIM,APIM_CDC,APIM_CISM,APIM_CIM;
BO_TX_BU_ 290 : APIM_CDC,APIM_CIM,APIM_CISM,APIM;
BO_TX_BU_ 419 : APIM_CISM,APIM;
BO_TX_BU_ 413 : APIM_CDC,APIM_CIM,APIM_CISM,APIM;
BO_TX_BU_ 1020 : APIM_CISM,APIM,APIM_CIM;
BO_TX_BU_ 696 : APIM_CDC,APIM_CIM,APIM_CISM,APIM;
BO_TX_BU_ 391 : APIM_CIM,APIM_CISM,ACM;
BO_TX_BU_ 672 : GWM,FCIMB;
BO_TX_BU_ 601 : APIM_CDC,IPC;
BO_TX_BU_ 766 : APIM_CISM,APIM;
BO_TX_BU_ 840 : APIM_CDC,APIM_CIM,IPC;
BO_TX_BU_ 494 : APIM_CDC,IPC;
BO_TX_BU_ 714 : APIM_CDC,IPC;
CM_ BO_ 885 "NOTE: START BITS 8-11 MUST BE OPEN SPEC REQUIREMENT";
CM_ SG_ 1119 LocationServices_2 "Tx by HS3 APIM";
CM_ SG_ 1118 LocationServices_1 "Tx by HS3 APIM";
CM_ BO_ 554 "TCU_CPPM Tx";
CM_ SG_ 419 MK_SpeedValue_Rq "Object MyKey.1 SpeedSettingConfig_Rq.SpeedValue (Parameter2)";
CM_ SG_ 419 MK_SpeedSetting_Rq "Object MyKey.1 SpeedSettingConfig_Rq.SpeedSetting (Parameter1)";
CM_ SG_ 419 MK_ResetAllUserKeys_Rq "Object MyKey.ResetAllKeys_Rq";
CM_ SG_ 419 MK_MyKeySystemInfo_Rq "Object MyKey.MyKeySystemInfo_Rq";
CM_ SG_ 419 MK_ESCRestrictConf_Rq "Object MyKey.ESCRestrictionConfig_Rq";
CM_ SG_ 419 MK_ECalRestrictConf_Rq "Object MyKey.ECallRestrictionConfig_Rq";
CM_ SG_ 419 MK_DNDRestrictConf_Rq "Object MyKey.DNDRestrictionConfig_Rq";
CM_ SG_ 419 MK_CreateMyKey_Rq "Object MyKey.CreateMyKey_Rq";
CM_ SG_ 419 MK_AudioLimitConfig_Rq "Object MyKey.AudioLimitConfig_Rq";
CM_ SG_ 419 MK_ACSRestrictConf_Rq "Object MyKey.ACSRestrictionConfig_Rq";
CM_ SG_ 542 LocationServices_3 "Tx by HS3 APIM";
CM_ SG_ 413 LBS1_ParentID "Object. ListBrowser.ItemInf.Rq.ActiveListID
0x0000:Root
0xFFFF:Reserved";
CM_ SG_ 413 LBS1_ListID "Object. ListBrowser.ItemInf.Rq.ItemIndex
0x0000:BrowseActiveListID
0x0001:EntryIndex_1
0xFFFF:ParentOfActiveListID";
CM_ SG_ 413 LBS1_EntryIndex "Object. ListBrowser.ItemInf.Rq.ActiveListID
0x0000:Root
0xFFFF:Reserved";
CM_ BO_ 688 "TP message";
CM_ SG_ 696 APIM_TCUB_Word_Tx "Tx by HS3 APIM";
CM_ SG_ 1189 Running_Board_Stat "Update msg. $115 to Event @ INIT in CMDB v4.06, 5/27/05.";
CM_ SG_ 772 Memory_Feedback_Rqst "Updated to 1 bit for CGEA, Not backwards compatible";
CM_ SG_ 92 TrnGearMsgTxt2_D_Rq "Signal not transmitted on vehicles that do not have shift by wire.";
CM_ SG_ 92 TrnSbwSysHlth_D_Actl "Signal not transmitted on vehicles that do not have shift by wire.";
CM_ SG_ 92 TrnDtpCmd_D_Actl "Signal not transmitted on vehicles that do not have shift by wire.";
CM_ SG_ 92 TrnGearNtmAllow_B_Stat "Signal not transmitted on vehicles that do not have shift by wire.";
CM_ SG_ 92 TrnGearCmd_No_Cs "Signal not transmitted on vehicles that do not have shift by wire.";
CM_ SG_ 92 TrnValidGear_D_Cnfm "Signal not transmitted on vehicles that do not have shift by wire.";
CM_ SG_ 92 TrnNtrlTowCmd_D_Actl "Signal not transmitted on vehicles that do not have shift by wire.";
CM_ SG_ 92 TrnGearCmd_Pc_ActlPt "Signal not transmitted on vehicles that do not have shift by wire.";
CM_ SG_ 92 TrnGear_D_RqPt "Signal not transmitted on vehicles that do not have shift by wire.";
CM_ SG_ 92 TrnCmdState_B_Actl "Signal not transmitted on vehicles that do not have shift by wire.";
CM_ SG_ 92 TrnCmdCnt_B_Actl "Signal not transmitted on vehicles that do not have shift by wire.";
CM_ SG_ 92 PrkBrkActv_D_RqTrnGear "Signal not transmitted on vehicles that do not have shift by wire.";
CM_ SG_ 92 TrnGearMsgTxt_D_Rq "Signal not transmitted on vehicles that do not have shift by wire.";
CM_ SG_ 92 TrnGearCmd_No_Cnt "Signal not transmitted on vehicles that do not have shift by wire.";
CM_ SG_ 357 BpedDrvAppl_D_Actl "CCMGenSigTimeoutTime=1000";
CM_ SG_ 357 CcStat_D_Actl "ABSGenSigTimeoutTime=1000";
CM_ SG_ 357 AccStopMde_D_Rq "ABSGenSigTimeoutTime=1000";
CM_ SG_ 839 FohStop_B_Stat "Signal not transmitted on vehicles that do not have the Fuel operated heater feature.";
CM_ SG_ 839 FohMsgTxt_D_Rq "Signal not transmitted on vehicles that do not have the Fuel operated heater feature.";
CM_ SG_ 839 FohKeyOff_B_Rq "Signal not transmitted on vehicles that do not have the Fuel operated heater feature.";
CM_ SG_ 839 FohEnbl_B_Rq "Signal not transmitted on vehicles that do not have the Fuel operated heater feature.";
CM_ SG_ 839 FohTAllEnable_B_Stat "Signal not transmitted on vehicles that do not have the Fuel operated heater feature.";
CM_ SG_ 839 FohT2Mnte_T_Stat "Signal not transmitted on vehicles that do not have the Fuel operated heater feature.";
CM_ SG_ 839 FohT2Hr_T_Stat "Signal not transmitted on vehicles that do not have the Fuel operated heater feature.";
CM_ SG_ 839 FohT2Enable_B_Stat "Signal not transmitted on vehicles that do not have the Fuel operated heater feature.";
CM_ SG_ 839 FohT1Mnte_T_Stat "Signal not transmitted on vehicles that do not have the Fuel operated heater feature.";
CM_ SG_ 839 FohT1Hr_T_Stat "Signal not transmitted on vehicles that do not have the Fuel operated heater feature.";
CM_ SG_ 839 FohT1Enable_B_Stat "Signal not transmitted on vehicles that do not have the Fuel operated heater feature.";
CM_ SG_ 839 FohStrtMnte_T_Stat "Signal not transmitted on vehicles that do not have the Fuel operated heater feature.";
CM_ SG_ 839 FohStrtHr_T_Stat "Signal not transmitted on vehicles that do not have the Fuel operated heater feature.";
CM_ SG_ 839 FohStrtEnable_B_Stat "Signal not transmitted on vehicles that do not have the Fuel operated heater feature.";
CM_ SG_ 839 FohContOn_B_Stat "Signal not transmitted on vehicles that do not have the Fuel operated heater feature.";
CM_ SG_ 839 FohStrtDay_T_Stat "Signal not transmitted on vehicles that do not have the Fuel operated heater feature.";
CM_ SG_ 839 FohT2Wednesday_T_Stat "Signal not transmitted on vehicles that do not have the Fuel operated heater feature.";
CM_ SG_ 839 FohT2Tuesday_T_Stat "Signal not transmitted on vehicles that do not have the Fuel operated heater feature.";
CM_ SG_ 839 FohT2Thursday_T_Stat "Signal not transmitted on vehicles that do not have the Fuel operated heater feature.";
CM_ SG_ 839 FohT2Sunday_T_Stat "Signal not transmitted on vehicles that do not have the Fuel operated heater feature.";
CM_ SG_ 839 FohT2Saturday_T_Stat "Signal not transmitted on vehicles that do not have the Fuel operated heater feature.";
CM_ SG_ 839 FohT2Monday_T_Stat "Signal not transmitted on vehicles that do not have the Fuel operated heater feature.";
CM_ SG_ 839 FohT2Friday_T_Stat "Signal not transmitted on vehicles that do not have the Fuel operated heater feature.";
CM_ SG_ 839 FohT1Wednesday_T_Stat "Signal not transmitted on vehicles that do not have the Fuel operated heater feature.";
CM_ SG_ 839 FohT1Tuesday_T_Stat "Signal not transmitted on vehicles that do not have the Fuel operated heater feature.";
CM_ SG_ 839 FohT1Thursday_T_Stat "Signal not transmitted on vehicles that do not have the Fuel operated heater feature.";
CM_ SG_ 839 FohT1Sunday_T_Stat "Signal not transmitted on vehicles that do not have the Fuel operated heater feature.";
CM_ SG_ 839 FohT1Saturday_T_Stat "Signal not transmitted on vehicles that do not have the Fuel operated heater feature.";
CM_ SG_ 839 FohT1Monday_T_Stat "Signal not transmitted on vehicles that do not have the Fuel operated heater feature.";
CM_ SG_ 839 FohT1Friday_T_Stat "Signal not transmitted on vehicles that do not have the Fuel operated heater feature.";
CM_ BO_ 560 "MHT (U611/625) the HPCM will Rx 0x230 from the PCM_HEV
Powersplit FWD HEV’s (Cx482/3 430) the HPCM will Tx 0x230";
CM_ SG_ 560 SelDrvMdeSwtch_D_Stat3 "ECM_HEV does not support or Transmit signal.";
CM_ SG_ 560 GearLvrPosActl_No_Cs "Signal not transmitted on Gas & HEV variants. MHT(U611/625) HPCM Rx 0x230 from PCM_HEV. Powersplit FWD HEV’s(Cx482/3 430) HPCM Tx 0x230.";
CM_ SG_ 560 GearLvrPosActl_No_Cnt "Signal not transmitted on Gas & HEV variants. MHT(U611/625) HPCM Rx 0x230 from PCM_HEV. Powersplit FWD HEV’s(Cx482/3 430) HPCM Tx 0x230.";
CM_ SG_ 560 TrnGbox_Rt_Actl "Signal not transmitted on Gas & HEV variants. MHT(U611/625) HPCM Rx 0x230 from PCM_HEV. Powersplit FWD HEV’s(Cx482/3 430) HPCM Tx 0x230.";
CM_ SG_ 560 TrnSrvcRqd_B_Rq "Signal not transmitted on Diesel & HEV variants. MHT(U611/625) HPCM Rx 0x230 from PCM_HEV. Powersplit FWD HEV’s(Cx482/3 430) HPCM Tx 0x230.";
CM_ SG_ 560 TrnCnvtClu_D_Actl "Signal not transmitted on Gas & HEV variants. MHT(U611/625) HPCM Rx 0x230 from PCM_HEV. Powersplit FWD HEV’s(Cx482/3 430) HPCM Tx 0x230.";
CM_ SG_ 560 TrnShifActv_B_Actl "Signal not transmitted on HEV variants. MHT(U611/625) HPCM Rx 0x230 from PCM_HEV. Powersplit FWD HEV’s(Cx482/3 430) HPCM Tx 0x230.";
CM_ SG_ 560 GboxOil_Te_Actl "Signal not transmitted on HEV variants. MHT(U611/625) HPCM Rx 0x230 from PCM_HEV. Powersplit FWD HEV’s(Cx482/3 430) HPCM Tx 0x230.";
CM_ SG_ 391 ACU_CtrlChimeChan_Rq "Object BodyInterface.StdChimeIF.ControlChimeChannel.Rq";
CM_ SG_ 672 SetVolume "$0: -30Steps
$1: -29Steps
$2: -28Steps
$1D: -1Step
$1E: NotPressed_Inactive
$1F: +1Step
$20: +2Steps
$21: +3Steps
$3C: +30Steps";
CM_ SG_ 672 SetPointVolume "Method: EFP_Button_Press
0x0:Inactive
$0: Inactive
$1: No_Volume
$2: Volume_Step1
$3: Vol_Step2
$1F: Vol_Step30";
CM_ SG_ 672 Coding_BtnID_D "Object InputControlInterface ICI ButtonCoding_D
Object InputControlInterface ICI ButtonID_D";
CM_ SG_ 672 Coding_BtnID_C "Object InputControlInterface.ICI ButtonCoding_C
Object InputControlInterface.ICI ButtonID_C";
CM_ SG_ 672 Coding_BtnID_B "Object InputControlInterface ICI ButtonCoding_B
Object InputControlInterface.ICI ButtonID_B";
CM_ SG_ 672 Coding_BtnID_A "Object InputControlInterface ICI ButtonCoding_A
Object InputControlInterface.ICI ButtonID A";
CM_ SG_ 672 BtnID_D "Object InputControlInterface ICI ButtonID_D... 0xFF: Inactive";
CM_ SG_ 672 BtnID_C "Object InputControlInterface ICI ButtonID_D... 0xFF: Inactive";
CM_ SG_ 672 BtnID_B "Object InputControlInterface ICI ButtonID_D... 0xFF: Inactive";
CM_ SG_ 672 BtnID_A "Object InputControlInterface ICI ButtonID_D... 0xFF: Inactive";
CM_ SG_ 672 BCP_Audible_Beep_Rq "Object.AlertMethod.BCP_Audible_Beep";
CM_ SG_ 1200 BrkTot_Tq_RqDrv "DCR 1836 to update Tx from GWM to EP100ms rejected due MPS6 TCM requires BrkTot_Tq_RqDrv at 20ms (bshu1).";
CM_ SG_ 840 FohT2Friday_T_Rq "Signal not transmitted on vehicles that do not have the Fuel operated heater feature.";
CM_ SG_ 840 FohT1Friday_T_Rq "Signal not transmitted on vehicles that do not have the Fuel operated heater feature.";
CM_ SG_ 840 FohT2Wednesday_T_Rq "Signal not transmitted on vehicles that do not have the Fuel operated heater feature.";
CM_ SG_ 840 FohT2Tuesday_T_Rq "Signal not transmitted on vehicles that do not have the Fuel operated heater feature.";
CM_ SG_ 840 FohT2Thursday_T_Rq "Signal not transmitted on vehicles that do not have the Fuel operated heater feature.";
CM_ SG_ 840 FohT2Sunday_T_Rq "Signal not transmitted on vehicles that do not have the Fuel operated heater feature.";
CM_ SG_ 840 FohT2Saturday_T_Rq "Signal not transmitted on vehicles that do not have the Fuel operated heater feature.";
CM_ SG_ 840 FohT2Monday_T_Rq "Signal not transmitted on vehicles that do not have the Fuel operated heater feature.";
CM_ SG_ 840 FohT1Wednesday_T_Rq "Signal not transmitted on vehicles that do not have the Fuel operated heater feature.";
CM_ SG_ 840 FohT1Tuesday_T_Rq "Signal not transmitted on vehicles that do not have the Fuel operated heater feature.";
CM_ SG_ 840 FohT1Thursday_T_Rq "Signal not transmitted on vehicles that do not have the Fuel operated heater feature.";
CM_ SG_ 840 FohT1Sunday_T_Rq "Signal not transmitted on vehicles that do not have the Fuel operated heater feature.";
CM_ SG_ 840 FohT1Saturday_T_Rq "Signal not transmitted on vehicles that do not have the Fuel operated heater feature.";
CM_ SG_ 840 FohT1Monday_T_Rq "Signal not transmitted on vehicles that do not have the Fuel operated heater feature.";
CM_ SG_ 494 HEC_TUPresetArea_Rq "Object Tuner.GetTUPresetInfo.PresetArea

$5: Get AMAST (MW) Preset Data
$6: Get AM (LW) Preset Data";
CM_ SG_ 494 Mc_SetCurrPreset2_Rq "Object Tuner.SetCurrentPreset2

$1-$1E: Preset 1 to 30
$0: Inactive
";
CM_ SG_ 494 HEC_TUNbrOfPresets_Rq "Object Tuner.GetTUPresetInfo.NumberOfPresets

$1-$1E: Preset 1 to 30";
CM_ SG_ 494 HEC_SetCurrTUBand_Rq "Object Tuner.SetCurrTUBand
$5: AM (LLN, HLN: MW)
$6: AM AST (LLN, HLN: LW)";
CM_ SG_ 494 HEC_TUStartIndex2_Rq "Object Tuner.GetTUPresetInfo.StartIndex2

$1-$FF: Preset 1 to 255";
BA_DEF_ BO_  "FrameRouting" STRING ;
BA_DEF_ BO_  "NetworkInitialization" ENUM  "No","Yes";
BA_DEF_ BO_  "GenMsgStartDelayTime" INT 0 10000;
BA_DEF_ BO_  "GenMsgNrOfRepetition" INT 0 100;
BA_DEF_ BO_  "GenMsgDelayTime" INT 0 1000;
BA_DEF_ BO_  "GenMsgCycleTime" INT 0 100000;
BA_DEF_ BO_  "GenMsgSendType" ENUM  "FixedPeriodic","Event","EnabledPeriodic","NotUsed","NotUsed","EventPeriodic","NotUsed","NotUsed","NoMsgSendType";
BA_DEF_ SG_  "U_P702_MY2024_Tx" ENUM  "No","Yes";
BA_DEF_ SG_  "U_V710_MY2023_Tx" ENUM  "No","Yes";
BA_DEF_ SG_  "U_CDX74X_MY2024_Tx" ENUM  "No","Yes";
BA_DEF_ SG_  "U_CDX707_MY2023_Tx" ENUM  "No","Yes";
BA_DEF_ SG_  "U_P708_MY2023_Tx" ENUM  "No","Yes";
BA_DEF_ SG_  "U_V713AV_MY2022_Tx" ENUM  "No","Yes";
BA_DEF_ SG_  "U_V713N_MY2022_Tx" ENUM  "No","Yes";
BA_DEF_ SG_  "ECGUsedTxSignal" ENUM  "No","Yes";
BA_DEF_ SG_  "U_P702_MY2024_Rx" ENUM  "No","Yes";
BA_DEF_ SG_  "U_V710_MY2023_Rx" ENUM  "No","Yes";
BA_DEF_ SG_  "U_CDX74X_MY2024_Rx" ENUM  "No","Yes";
BA_DEF_ SG_  "U_CDX707_MY2023_Rx" ENUM  "No","Yes";
BA_DEF_ SG_  "U_P708_MY2023_Rx" ENUM  "No","Yes";
BA_DEF_ SG_  "U_V713AV_MY2022_Rx" ENUM  "No","Yes";
BA_DEF_ SG_  "U_V713N_MY2022_Rx" ENUM  "No","Yes";
BA_DEF_ SG_  "ECGUsedRxSignal" ENUM  "No","Yes";
BA_DEF_ SG_  "UsedOnPgmDBC" ENUM  "No","Yes";
BA_DEF_ SG_  "ContentDependant" ENUM  "No","Yes";
BA_DEF_ SG_  "GenSigStartValue" HEX 0 268435455;
BA_DEF_ SG_  "MetaData" ENUM  "No","Yes";
BA_DEF_ SG_  "WakeupSignal" ENUM  "No","Yes";
BA_DEF_ SG_  "GenSigInactiveValue" INT 0 100000;
BA_DEF_ SG_  "GenSigSendType" ENUM  "Cyclic","OnWrite","vector_leerstring","OnChange","vector_leerstring","IfActive","vector_leerstring","NoSigSendType";
BA_DEF_ BO_  "TpTxIndex" INT 0 536870911;
BA_DEF_ BO_  "OvtpPushApplication" ENUM  "FALSE","TRUE";
BA_DEF_ BO_  "SCP_FreshnessValueLength" INT 0 512;
BA_DEF_ BO_  "SCP_DataId" INT 0 17663;
BA_DEF_ BO_  "SCP_FreshnessValueTxLength" INT 0 512;
BA_DEF_ BO_  "SCP_AuthInfoTxLength" INT 0 512;
BA_DEF_ BO_  "SC_Message" ENUM  "No","Yes";
BA_DEF_ BO_  "GenMsgRoutingTimeoutTime" INT 0 5000;
BA_DEF_ BO_  "MessageGateway" ENUM  "No","Yes";
BA_DEF_ BO_  "NmAsrMessage" ENUM  "No","Yes";
BA_DEF_ BO_  "DiagState" ENUM  "No","Yes";
BA_DEF_ BO_  "DiagRequest" ENUM  "No","Yes";
BA_DEF_ BO_  "DiagResponse" ENUM  "No","Yes";
BA_DEF_ BO_  "NmMessage" ENUM  "No","Yes";
BA_DEF_ BO_  "GenMsgILSupport" ENUM  "No","Yes";
BA_DEF_DEF_  "FrameRouting" "";
BA_DEF_DEF_  "NetworkInitialization" "Yes";
BA_DEF_DEF_  "GenMsgStartDelayTime" 0;
BA_DEF_DEF_  "GenMsgNrOfRepetition" 1;
BA_DEF_DEF_  "GenMsgDelayTime" 20;
BA_DEF_DEF_  "GenMsgCycleTime" 0;
BA_DEF_DEF_  "GenMsgSendType" "NoMsgSendType";
BA_DEF_DEF_  "U_P702_MY2024_Tx" "No";
BA_DEF_DEF_  "U_V710_MY2023_Tx" "No";
BA_DEF_DEF_  "U_CDX74X_MY2024_Tx" "No";
BA_DEF_DEF_  "U_CDX707_MY2023_Tx" "No";
BA_DEF_DEF_  "U_P708_MY2023_Tx" "No";
BA_DEF_DEF_  "U_V713AV_MY2022_Tx" "No";
BA_DEF_DEF_  "U_V713N_MY2022_Tx" "No";
BA_DEF_DEF_  "ECGUsedTxSignal" "No";
BA_DEF_DEF_  "U_P702_MY2024_Rx" "No";
BA_DEF_DEF_  "U_V710_MY2023_Rx" "No";
BA_DEF_DEF_  "U_CDX74X_MY2024_Rx" "No";
BA_DEF_DEF_  "U_CDX707_MY2023_Rx" "No";
BA_DEF_DEF_  "U_P708_MY2023_Rx" "No";
BA_DEF_DEF_  "U_V713AV_MY2022_Rx" "No";
BA_DEF_DEF_  "U_V713N_MY2022_Rx" "No";
BA_DEF_DEF_  "ECGUsedRxSignal" "No";
BA_DEF_DEF_  "UsedOnPgmDBC" "Yes";
BA_DEF_DEF_  "ContentDependant" "No";
BA_DEF_DEF_  "GenSigStartValue" 0;
BA_DEF_DEF_  "MetaData" "No";
BA_DEF_DEF_  "WakeupSignal" "No";
BA_DEF_DEF_  "GenSigInactiveValue" 0;
BA_DEF_DEF_  "GenSigSendType" "NoSigSendType";
BA_DEF_DEF_  "TpTxIndex" 0;
BA_DEF_DEF_  "OvtpPushApplication" "FALSE";
BA_DEF_DEF_  "SCP_FreshnessValueLength" 64;
BA_DEF_DEF_  "SCP_DataId" 0;
BA_DEF_DEF_  "SCP_FreshnessValueTxLength" 11;
BA_DEF_DEF_  "SCP_AuthInfoTxLength" 53;
BA_DEF_DEF_  "SC_Message" "No";
BA_DEF_DEF_  "GenMsgRoutingTimeoutTime" 0;
BA_DEF_DEF_  "MessageGateway" "No";
BA_DEF_DEF_  "NmAsrMessage" "No";
BA_DEF_DEF_  "DiagState" "No";
BA_DEF_DEF_  "DiagRequest" "No";
BA_DEF_DEF_  "DiagResponse" "No";
BA_DEF_DEF_  "NmMessage" "No";
BA_DEF_DEF_  "GenMsgILSupport" "Yes";
BA_ "GenMsgSendType" BO_ 803 5;
BA_ "GenMsgCycleTime" BO_ 803 1000;
BA_ "GenMsgSendType" BO_ 802 5;
BA_ "GenMsgCycleTime" BO_ 802 1000;
BA_ "GenMsgSendType" BO_ 812 5;
BA_ "GenMsgCycleTime" BO_ 812 1000;
BA_ "GenMsgSendType" BO_ 885 0;
BA_ "GenMsgCycleTime" BO_ 885 200;
BA_ "FrameRouting" BO_ 784 "MS2_CAN,0x310;";
BA_ "GenMsgSendType" BO_ 1119 1;
BA_ "GenMsgSendType" BO_ 1118 1;
BA_ "GenMsgSendType" BO_ 290 1;
BA_ "GenMsgSendType" BO_ 554 5;
BA_ "GenMsgCycleTime" BO_ 554 1000;
BA_ "GenMsgSendType" BO_ 419 1;
BA_ "FrameRouting" BO_ 542 "FD2_CAN,0x21E;";
BA_ "GenMsgSendType" BO_ 413 1;
BA_ "FrameRouting" BO_ 898 "HS2_CAN,0x382;FD1_CAN,0x382";
BA_ "GenMsgSendType" BO_ 1020 5;
BA_ "GenMsgCycleTime" BO_ 1020 1000;
BA_ "GenMsgSendType" BO_ 1007 5;
BA_ "GenMsgCycleTime" BO_ 1007 1000;
BA_ "FrameRouting" BO_ 1217 "FD3_CAN,0x4C1;";
BA_ "FrameRouting" BO_ 1216 "FD3_CAN,0x4C0;";
BA_ "FrameRouting" BO_ 820 "FD1_CAN,0x334;FD3_CAN,0x334";
BA_ "FrameRouting" BO_ 1247 "FD1_CAN,0x4DF;";
BA_ "GenMsgSendType" BO_ 677 5;
BA_ "GenMsgCycleTime" BO_ 677 1000;
BA_ "FrameRouting" BO_ 582 "FD1_CAN,0x242;";
BA_ "FrameRouting" BO_ 1036 "HS2_CAN,0x40C;";
BA_ "FrameRouting" BO_ 1047 "FD1_CAN,0x417;FD3_CAN,0x417";
BA_ "TpTxIndex" BO_ 688 121;
BA_ "FrameRouting" BO_ 688 "FD2_CAN,0x2B0;";
BA_ "TpTxIndex" BO_ 696 121;
BA_ "FrameRouting" BO_ 1236 "FD1_CAN,0x4D4;FD3_CAN,0x4D4";
BA_ "FrameRouting" BO_ 1235 "FD1_CAN,0x4D3;FD3_CAN,0x4D3";
BA_ "FrameRouting" BO_ 841 "MS1_CAN,0x349;";
BA_ "FrameRouting" BO_ 1189 "MS1_CAN,0x4A5;";
BA_ "FrameRouting" BO_ 772 "MS1_CAN,0x304;";
BA_ "FrameRouting" BO_ 1054 "FD1_CAN,0x41E;";
BA_ "FrameRouting" BO_ 572 "HS2_CAN,0x24B;";
BA_ "FrameRouting" BO_ 561 "FD1_CAN,0x231;";
BA_ "FrameRouting" BO_ 602 "FD1_CAN,0x25A;";
BA_ "FrameRouting" BO_ 92 "FD1_CAN,0x5C;";
BA_ "FrameRouting" BO_ 1156 "FD1_CAN,0x36D;";
BA_ "GenMsgRoutingTimeoutTime" BO_ 357 60;
BA_ "FrameRouting" BO_ 357 "FD1_CAN,0x165;";
BA_ "FrameRouting" BO_ 1100 "FD1_CAN,0x44C;";
BA_ "FrameRouting" BO_ 1152 "FD1_CAN,0x480;";
BA_ "FrameRouting" BO_ 839 "MS1_CAN,0x347;";
BA_ "OvtpPushApplication" BO_ 2612224064 1;
BA_ "TpTxIndex" BO_ 2612224064 464584920;
BA_ "GenMsgSendType" BO_ 2612224064 1;
BA_ "GenMsgDelayTime" BO_ 2612224064 0;
BA_ "NetworkInitialization" BO_ 2612224064 0;
BA_ "OvtpPushApplication" BO_ 2612068568 1;
BA_ "TpTxIndex" BO_ 2612068568 464584920;
BA_ "GenMsgSendType" BO_ 2612068568 1;
BA_ "GenMsgDelayTime" BO_ 2612068568 0;
BA_ "NetworkInitialization" BO_ 2612068568 0;
BA_ "TpTxIndex" BO_ 2611175488 463536344;
BA_ "GenMsgSendType" BO_ 2611175488 1;
BA_ "GenMsgDelayTime" BO_ 2611175488 0;
BA_ "NetworkInitialization" BO_ 2611175488 0;
BA_ "TpTxIndex" BO_ 2611019992 463536344;
BA_ "GenMsgSendType" BO_ 2611019992 1;
BA_ "GenMsgDelayTime" BO_ 2611019992 0;
BA_ "NetworkInitialization" BO_ 2611019992 0;
BA_ "TpTxIndex" BO_ 2610126912 462487768;
BA_ "GenMsgSendType" BO_ 2610126912 1;
BA_ "GenMsgDelayTime" BO_ 2610126912 0;
BA_ "NetworkInitialization" BO_ 2610126912 0;
BA_ "TpTxIndex" BO_ 2609971416 462487768;
BA_ "GenMsgSendType" BO_ 2609971416 1;
BA_ "GenMsgDelayTime" BO_ 2609971416 0;
BA_ "NetworkInitialization" BO_ 2609971416 0;
BA_ "FrameRouting" BO_ 652 "FD2_CAN,0x28C;";
BA_ "FrameRouting" BO_ 560 "FD1_CAN,0x230;";
BA_ "FrameRouting" BO_ 1153 "HS2_CAN,0x481;";
BA_ "FrameRouting" BO_ 930 "FD3_CAN,0x3A2;";
BA_ "FrameRouting" BO_ 929 "FD3_CAN,0x3A1;";
BA_ "FrameRouting" BO_ 788 "FD1_CAN,0x314;";
BA_ "GenMsgSendType" BO_ 391 1;
BA_ "FrameRouting" BO_ 670 "FD3_CAN,0x29E;";
BA_ "FrameRouting" BO_ 672 "MS1_CAN,0x2A0;";
BA_ "GenMsgSendType" BO_ 672 5;
BA_ "GenMsgCycleTime" BO_ 672 1000;
BA_ "GenMsgStartDelayTime" BO_ 672 150;
BA_ "FrameRouting" BO_ 1205 "FD1_CAN,0x4B5;";
BA_ "FrameRouting" BO_ 1200 "FD1_CAN,0x4B0;";
BA_ "TpTxIndex" BO_ 593 58;
BA_ "TpTxIndex" BO_ 601 58;
BA_ "NetworkInitialization" BO_ 601 0;
BA_ "FrameRouting" BO_ 1018 "MS2_CAN,0x3FA;";
BA_ "FrameRouting" BO_ 1238 "FD1_CAN,0x4D6;FD3_CAN,0x4D6";
BA_ "GenMsgSendType" BO_ 766 5;
BA_ "GenMsgCycleTime" BO_ 766 1000;
BA_ "GenMsgSendType" BO_ 840 5;
BA_ "GenMsgCycleTime" BO_ 840 1000;
BA_ "GenMsgSendType" BO_ 494 1;
BA_ "NetworkInitialization" BO_ 494 0;
BA_ "TpTxIndex" BO_ 714 28;
BA_ "NetworkInitialization" BO_ 714 0;
BA_ "GenSigSendType" SG_ 803 DistTripUnit_D_Stat 3;
BA_ "U_P708_MY2023_Rx" SG_ 803 DistTripUnit_D_Stat 1;
BA_ "U_V713N_MY2022_Tx" SG_ 803 DistTripUnit_D_Stat 1;
BA_ "U_V713AV_MY2022_Tx" SG_ 803 DistTripUnit_D_Stat 1;
BA_ "U_P708_MY2023_Tx" SG_ 803 DistTripUnit_D_Stat 1;
BA_ "U_V710_MY2023_Tx" SG_ 803 DistTripUnit_D_Stat 1;
BA_ "U_P702_MY2024_Tx" SG_ 803 DistTripUnit_D_Stat 1;
BA_ "GenSigSendType" SG_ 803 DistTrip2_No_Dsply 3;
BA_ "U_P708_MY2023_Rx" SG_ 803 DistTrip2_No_Dsply 1;
BA_ "U_V713N_MY2022_Tx" SG_ 803 DistTrip2_No_Dsply 1;
BA_ "U_V713AV_MY2022_Tx" SG_ 803 DistTrip2_No_Dsply 1;
BA_ "U_P708_MY2023_Tx" SG_ 803 DistTrip2_No_Dsply 1;
BA_ "U_V710_MY2023_Tx" SG_ 803 DistTrip2_No_Dsply 1;
BA_ "U_P702_MY2024_Tx" SG_ 803 DistTrip2_No_Dsply 1;
BA_ "GenSigSendType" SG_ 803 DistTrip1_No_Dsply 3;
BA_ "U_P708_MY2023_Rx" SG_ 803 DistTrip1_No_Dsply 1;
BA_ "U_V713N_MY2022_Tx" SG_ 803 DistTrip1_No_Dsply 1;
BA_ "U_V713AV_MY2022_Tx" SG_ 803 DistTrip1_No_Dsply 1;
BA_ "U_P708_MY2023_Tx" SG_ 803 DistTrip1_No_Dsply 1;
BA_ "U_V710_MY2023_Tx" SG_ 803 DistTrip1_No_Dsply 1;
BA_ "U_P702_MY2024_Tx" SG_ 803 DistTrip1_No_Dsply 1;
BA_ "GenSigSendType" SG_ 802 AvgFeTripUnit_D_Stat 3;
BA_ "U_P708_MY2023_Rx" SG_ 802 AvgFeTripUnit_D_Stat 1;
BA_ "U_V713N_MY2022_Tx" SG_ 802 AvgFeTripUnit_D_Stat 1;
BA_ "U_V713AV_MY2022_Tx" SG_ 802 AvgFeTripUnit_D_Stat 1;
BA_ "U_P708_MY2023_Tx" SG_ 802 AvgFeTripUnit_D_Stat 1;
BA_ "U_V710_MY2023_Tx" SG_ 802 AvgFeTripUnit_D_Stat 1;
BA_ "U_P702_MY2024_Tx" SG_ 802 AvgFeTripUnit_D_Stat 1;
BA_ "GenSigSendType" SG_ 802 AvgFeTrip2Actv_B_Dsply 3;
BA_ "U_P708_MY2023_Rx" SG_ 802 AvgFeTrip2Actv_B_Dsply 1;
BA_ "U_V713N_MY2022_Tx" SG_ 802 AvgFeTrip2Actv_B_Dsply 1;
BA_ "U_V713AV_MY2022_Tx" SG_ 802 AvgFeTrip2Actv_B_Dsply 1;
BA_ "U_P708_MY2023_Tx" SG_ 802 AvgFeTrip2Actv_B_Dsply 1;
BA_ "U_V710_MY2023_Tx" SG_ 802 AvgFeTrip2Actv_B_Dsply 1;
BA_ "U_P702_MY2024_Tx" SG_ 802 AvgFeTrip2Actv_B_Dsply 1;
BA_ "GenSigSendType" SG_ 802 AvgFeTrip2_No_Dsply 3;
BA_ "U_P708_MY2023_Rx" SG_ 802 AvgFeTrip2_No_Dsply 1;
BA_ "U_V713N_MY2022_Tx" SG_ 802 AvgFeTrip2_No_Dsply 1;
BA_ "U_V713AV_MY2022_Tx" SG_ 802 AvgFeTrip2_No_Dsply 1;
BA_ "U_P708_MY2023_Tx" SG_ 802 AvgFeTrip2_No_Dsply 1;
BA_ "U_V710_MY2023_Tx" SG_ 802 AvgFeTrip2_No_Dsply 1;
BA_ "U_P702_MY2024_Tx" SG_ 802 AvgFeTrip2_No_Dsply 1;
BA_ "GenSigSendType" SG_ 802 AvgFeTrip1Actv_B_Dsply 3;
BA_ "U_P708_MY2023_Rx" SG_ 802 AvgFeTrip1Actv_B_Dsply 1;
BA_ "U_V713N_MY2022_Tx" SG_ 802 AvgFeTrip1Actv_B_Dsply 1;
BA_ "U_V713AV_MY2022_Tx" SG_ 802 AvgFeTrip1Actv_B_Dsply 1;
BA_ "U_P708_MY2023_Tx" SG_ 802 AvgFeTrip1Actv_B_Dsply 1;
BA_ "U_V710_MY2023_Tx" SG_ 802 AvgFeTrip1Actv_B_Dsply 1;
BA_ "U_P702_MY2024_Tx" SG_ 802 AvgFeTrip1Actv_B_Dsply 1;
BA_ "GenSigSendType" SG_ 802 AvgFeTrip1_No_Dsply 3;
BA_ "U_P708_MY2023_Rx" SG_ 802 AvgFeTrip1_No_Dsply 1;
BA_ "U_V713N_MY2022_Tx" SG_ 802 AvgFeTrip1_No_Dsply 1;
BA_ "U_V713AV_MY2022_Tx" SG_ 802 AvgFeTrip1_No_Dsply 1;
BA_ "U_P708_MY2023_Tx" SG_ 802 AvgFeTrip1_No_Dsply 1;
BA_ "U_V710_MY2023_Tx" SG_ 802 AvgFeTrip1_No_Dsply 1;
BA_ "U_P702_MY2024_Tx" SG_ 802 AvgFeTrip1_No_Dsply 1;
BA_ "GenSigSendType" SG_ 802 AvgFeActv_B_Dsply 3;
BA_ "U_P708_MY2023_Rx" SG_ 802 AvgFeActv_B_Dsply 1;
BA_ "U_V713N_MY2022_Tx" SG_ 802 AvgFeActv_B_Dsply 1;
BA_ "U_V713AV_MY2022_Tx" SG_ 802 AvgFeActv_B_Dsply 1;
BA_ "U_P708_MY2023_Tx" SG_ 802 AvgFeActv_B_Dsply 1;
BA_ "U_V710_MY2023_Tx" SG_ 802 AvgFeActv_B_Dsply 1;
BA_ "U_P702_MY2024_Tx" SG_ 802 AvgFeActv_B_Dsply 1;
BA_ "GenSigSendType" SG_ 802 AvgFe_No_Dsply 3;
BA_ "U_P708_MY2023_Rx" SG_ 802 AvgFe_No_Dsply 1;
BA_ "U_V713N_MY2022_Tx" SG_ 802 AvgFe_No_Dsply 1;
BA_ "U_V713AV_MY2022_Tx" SG_ 802 AvgFe_No_Dsply 1;
BA_ "U_P708_MY2023_Tx" SG_ 802 AvgFe_No_Dsply 1;
BA_ "U_V710_MY2023_Tx" SG_ 802 AvgFe_No_Dsply 1;
BA_ "U_P702_MY2024_Tx" SG_ 802 AvgFe_No_Dsply 1;
BA_ "GenSigSendType" SG_ 812 TimerTrip2_T_Dsply 3;
BA_ "U_P708_MY2023_Rx" SG_ 812 TimerTrip2_T_Dsply 1;
BA_ "U_P708_MY2023_Tx" SG_ 812 TimerTrip2_T_Dsply 1;
BA_ "U_V710_MY2023_Tx" SG_ 812 TimerTrip2_T_Dsply 1;
BA_ "GenSigSendType" SG_ 812 TimerTrip1_T_Dsply 3;
BA_ "U_P708_MY2023_Rx" SG_ 812 TimerTrip1_T_Dsply 1;
BA_ "U_P708_MY2023_Tx" SG_ 812 TimerTrip1_T_Dsply 1;
BA_ "U_V710_MY2023_Tx" SG_ 812 TimerTrip1_T_Dsply 1;
BA_ "U_V713AV_MY2022_Rx" SG_ 885 VehStrtInhbt_T_Dsply 1;
BA_ "U_P708_MY2023_Rx" SG_ 885 VehStrtInhbt_T_Dsply 1;
BA_ "U_V710_MY2023_Rx" SG_ 885 VehStrtInhbt_T_Dsply 1;
BA_ "U_P702_MY2024_Rx" SG_ 885 VehStrtInhbt_T_Dsply 1;
BA_ "ECGUsedTxSignal" SG_ 885 VehStrtInhbt_T_Dsply 1;
BA_ "U_V713N_MY2022_Tx" SG_ 885 VehStrtInhbt_T_Dsply 1;
BA_ "U_V713AV_MY2022_Tx" SG_ 885 VehStrtInhbt_T_Dsply 1;
BA_ "U_P708_MY2023_Tx" SG_ 885 VehStrtInhbt_T_Dsply 1;
BA_ "U_CDX74X_MY2024_Tx" SG_ 885 VehStrtInhbt_T_Dsply 1;
BA_ "U_V710_MY2023_Tx" SG_ 885 VehStrtInhbt_T_Dsply 1;
BA_ "U_V713AV_MY2022_Rx" SG_ 885 VehStrtInhbt_D_Dsply 1;
BA_ "U_P708_MY2023_Rx" SG_ 885 VehStrtInhbt_D_Dsply 1;
BA_ "U_V710_MY2023_Rx" SG_ 885 VehStrtInhbt_D_Dsply 1;
BA_ "U_P702_MY2024_Rx" SG_ 885 VehStrtInhbt_D_Dsply 1;
BA_ "ECGUsedTxSignal" SG_ 885 VehStrtInhbt_D_Dsply 1;
BA_ "U_V713N_MY2022_Tx" SG_ 885 VehStrtInhbt_D_Dsply 1;
BA_ "U_V713AV_MY2022_Tx" SG_ 885 VehStrtInhbt_D_Dsply 1;
BA_ "U_P708_MY2023_Tx" SG_ 885 VehStrtInhbt_D_Dsply 1;
BA_ "U_CDX74X_MY2024_Tx" SG_ 885 VehStrtInhbt_D_Dsply 1;
BA_ "U_V710_MY2023_Tx" SG_ 885 VehStrtInhbt_D_Dsply 1;
BA_ "U_V713AV_MY2022_Rx" SG_ 885 OtaActv_D_Stat 1;
BA_ "U_P708_MY2023_Rx" SG_ 885 OtaActv_D_Stat 1;
BA_ "U_V710_MY2023_Rx" SG_ 885 OtaActv_D_Stat 1;
BA_ "U_P702_MY2024_Rx" SG_ 885 OtaActv_D_Stat 1;
BA_ "ECGUsedTxSignal" SG_ 885 OtaActv_D_Stat 1;
BA_ "U_V713N_MY2022_Tx" SG_ 885 OtaActv_D_Stat 1;
BA_ "U_V713AV_MY2022_Tx" SG_ 885 OtaActv_D_Stat 1;
BA_ "U_P708_MY2023_Tx" SG_ 885 OtaActv_D_Stat 1;
BA_ "U_CDX74X_MY2024_Tx" SG_ 885 OtaActv_D_Stat 1;
BA_ "U_V710_MY2023_Tx" SG_ 885 OtaActv_D_Stat 1;
BA_ "U_V713N_MY2022_Rx" SG_ 784 TrlrTireTSensRr_D_Stat 1;
BA_ "U_P708_MY2023_Rx" SG_ 784 TrlrTireTSensRr_D_Stat 1;
BA_ "U_V713AV_MY2022_Rx" SG_ 784 TrlrTireTSensRr_D_Stat 1;
BA_ "U_V710_MY2023_Rx" SG_ 784 TrlrTireTSensRr_D_Stat 1;
BA_ "U_P702_MY2024_Rx" SG_ 784 TrlrTireTSensRr_D_Stat 1;
BA_ "U_V713N_MY2022_Rx" SG_ 784 TrlrTireTSensRm_D_Stat 1;
BA_ "U_P708_MY2023_Rx" SG_ 784 TrlrTireTSensRm_D_Stat 1;
BA_ "U_V713AV_MY2022_Rx" SG_ 784 TrlrTireTSensRm_D_Stat 1;
BA_ "U_V710_MY2023_Rx" SG_ 784 TrlrTireTSensRm_D_Stat 1;
BA_ "U_P702_MY2024_Rx" SG_ 784 TrlrTireTSensRm_D_Stat 1;
BA_ "U_V713N_MY2022_Rx" SG_ 784 TrlrTireTSensRf_D_Stat 1;
BA_ "U_P708_MY2023_Rx" SG_ 784 TrlrTireTSensRf_D_Stat 1;
BA_ "U_V713AV_MY2022_Rx" SG_ 784 TrlrTireTSensRf_D_Stat 1;
BA_ "U_V710_MY2023_Rx" SG_ 784 TrlrTireTSensRf_D_Stat 1;
BA_ "U_P702_MY2024_Rx" SG_ 784 TrlrTireTSensRf_D_Stat 1;
BA_ "U_V713N_MY2022_Rx" SG_ 784 TrlrTireTSensLr_D_Stat 1;
BA_ "U_P708_MY2023_Rx" SG_ 784 TrlrTireTSensLr_D_Stat 1;
BA_ "U_V713AV_MY2022_Rx" SG_ 784 TrlrTireTSensLr_D_Stat 1;
BA_ "U_V710_MY2023_Rx" SG_ 784 TrlrTireTSensLr_D_Stat 1;
BA_ "U_P702_MY2024_Rx" SG_ 784 TrlrTireTSensLr_D_Stat 1;
BA_ "U_V713N_MY2022_Rx" SG_ 784 TrlrTireTSensLm_D_Stat 1;
BA_ "U_P708_MY2023_Rx" SG_ 784 TrlrTireTSensLm_D_Stat 1;
BA_ "U_V713AV_MY2022_Rx" SG_ 784 TrlrTireTSensLm_D_Stat 1;
BA_ "U_V710_MY2023_Rx" SG_ 784 TrlrTireTSensLm_D_Stat 1;
BA_ "U_P702_MY2024_Rx" SG_ 784 TrlrTireTSensLm_D_Stat 1;
BA_ "U_V713N_MY2022_Rx" SG_ 784 TrlrTireTSensLf_D_Stat 1;
BA_ "U_P708_MY2023_Rx" SG_ 784 TrlrTireTSensLf_D_Stat 1;
BA_ "U_V713AV_MY2022_Rx" SG_ 784 TrlrTireTSensLf_D_Stat 1;
BA_ "U_V710_MY2023_Rx" SG_ 784 TrlrTireTSensLf_D_Stat 1;
BA_ "U_P702_MY2024_Rx" SG_ 784 TrlrTireTSensLf_D_Stat 1;
BA_ "GenSigStartValue" SG_ 784 TrlrTireTempSys_D_Stat 3;
BA_ "U_V713N_MY2022_Rx" SG_ 784 TrlrTireTempSys_D_Stat 1;
BA_ "U_P708_MY2023_Rx" SG_ 784 TrlrTireTempSys_D_Stat 1;
BA_ "U_V713AV_MY2022_Rx" SG_ 784 TrlrTireTempSys_D_Stat 1;
BA_ "U_V710_MY2023_Rx" SG_ 784 TrlrTireTempSys_D_Stat 1;
BA_ "U_P702_MY2024_Rx" SG_ 784 TrlrTireTempSys_D_Stat 1;
BA_ "GenSigStartValue" SG_ 784 TrlrTireRr_T_Actl 253;
BA_ "U_V713N_MY2022_Rx" SG_ 784 TrlrTireRr_T_Actl 1;
BA_ "U_P708_MY2023_Rx" SG_ 784 TrlrTireRr_T_Actl 1;
BA_ "U_V710_MY2023_Rx" SG_ 784 TrlrTireRr_T_Actl 1;
BA_ "U_P702_MY2024_Rx" SG_ 784 TrlrTireRr_T_Actl 1;
BA_ "GenSigStartValue" SG_ 784 TrlrTireRm_T_Actl 253;
BA_ "U_V713N_MY2022_Rx" SG_ 784 TrlrTireRm_T_Actl 1;
BA_ "U_P708_MY2023_Rx" SG_ 784 TrlrTireRm_T_Actl 1;
BA_ "U_V710_MY2023_Rx" SG_ 784 TrlrTireRm_T_Actl 1;
BA_ "U_P702_MY2024_Rx" SG_ 784 TrlrTireRm_T_Actl 1;
BA_ "GenSigStartValue" SG_ 784 TrlrTireRf_T_Actl 253;
BA_ "U_V713N_MY2022_Rx" SG_ 784 TrlrTireRf_T_Actl 1;
BA_ "U_P708_MY2023_Rx" SG_ 784 TrlrTireRf_T_Actl 1;
BA_ "U_V710_MY2023_Rx" SG_ 784 TrlrTireRf_T_Actl 1;
BA_ "U_P702_MY2024_Rx" SG_ 784 TrlrTireRf_T_Actl 1;
BA_ "GenSigStartValue" SG_ 784 TrlrTireLr_T_Actl 253;
BA_ "U_V713N_MY2022_Rx" SG_ 784 TrlrTireLr_T_Actl 1;
BA_ "U_P708_MY2023_Rx" SG_ 784 TrlrTireLr_T_Actl 1;
BA_ "U_V710_MY2023_Rx" SG_ 784 TrlrTireLr_T_Actl 1;
BA_ "U_P702_MY2024_Rx" SG_ 784 TrlrTireLr_T_Actl 1;
BA_ "GenSigStartValue" SG_ 784 TrlrTireLm_T_Actl 253;
BA_ "U_V713N_MY2022_Rx" SG_ 784 TrlrTireLm_T_Actl 1;
BA_ "U_P708_MY2023_Rx" SG_ 784 TrlrTireLm_T_Actl 1;
BA_ "U_V710_MY2023_Rx" SG_ 784 TrlrTireLm_T_Actl 1;
BA_ "U_P702_MY2024_Rx" SG_ 784 TrlrTireLm_T_Actl 1;
BA_ "GenSigStartValue" SG_ 784 TrlrTireLf_T_Actl 253;
BA_ "U_V713N_MY2022_Rx" SG_ 784 TrlrTireLf_T_Actl 1;
BA_ "U_P708_MY2023_Rx" SG_ 784 TrlrTireLf_T_Actl 1;
BA_ "U_V710_MY2023_Rx" SG_ 784 TrlrTireLf_T_Actl 1;
BA_ "U_P702_MY2024_Rx" SG_ 784 TrlrTireLf_T_Actl 1;
BA_ "GenSigSendType" SG_ 1119 LocationServices_2 1;
BA_ "U_P708_MY2023_Rx" SG_ 1119 LocationServices_2 1;
BA_ "ECGUsedRxSignal" SG_ 1119 LocationServices_2 1;
BA_ "U_V713N_MY2022_Rx" SG_ 1119 LocationServices_2 1;
BA_ "U_V713AV_MY2022_Rx" SG_ 1119 LocationServices_2 1;
BA_ "U_CDX74X_MY2024_Rx" SG_ 1119 LocationServices_2 1;
BA_ "U_V710_MY2023_Rx" SG_ 1119 LocationServices_2 1;
BA_ "U_V710_MY2023_Tx" SG_ 1119 LocationServices_2 1;
BA_ "U_P708_MY2023_Tx" SG_ 1119 LocationServices_2 1;
BA_ "U_P702_MY2024_Tx" SG_ 1119 LocationServices_2 1;
BA_ "GenSigSendType" SG_ 1118 LocationServices_1 1;
BA_ "U_V713N_MY2022_Rx" SG_ 1118 LocationServices_1 1;
BA_ "U_P708_MY2023_Rx" SG_ 1118 LocationServices_1 1;
BA_ "ECGUsedRxSignal" SG_ 1118 LocationServices_1 1;
BA_ "U_V713AV_MY2022_Rx" SG_ 1118 LocationServices_1 1;
BA_ "U_CDX74X_MY2024_Rx" SG_ 1118 LocationServices_1 1;
BA_ "U_V710_MY2023_Rx" SG_ 1118 LocationServices_1 1;
BA_ "U_V710_MY2023_Tx" SG_ 1118 LocationServices_1 1;
BA_ "U_P708_MY2023_Tx" SG_ 1118 LocationServices_1 1;
BA_ "U_P702_MY2024_Tx" SG_ 1118 LocationServices_1 1;
BA_ "GenSigSendType" SG_ 290 WifiHtsptFqBand_D_Rq 3;
BA_ "U_V710_MY2023_Tx" SG_ 290 WifiHtsptFqBand_D_Rq 1;
BA_ "U_P708_MY2023_Tx" SG_ 290 WifiHtsptFqBand_D_Rq 1;
BA_ "U_P702_MY2024_Tx" SG_ 290 WifiHtsptFqBand_D_Rq 1;
BA_ "GenSigSendType" SG_ 290 WifiHtsptTrial_D_RqDrv 3;
BA_ "U_V710_MY2023_Tx" SG_ 290 WifiHtsptTrial_D_RqDrv 1;
BA_ "U_P708_MY2023_Tx" SG_ 290 WifiHtsptTrial_D_RqDrv 1;
BA_ "U_P702_MY2024_Tx" SG_ 290 WifiHtsptTrial_D_RqDrv 1;
BA_ "GenSigSendType" SG_ 290 WifiHtsptEnbl_D_Rq 3;
BA_ "U_V710_MY2023_Tx" SG_ 290 WifiHtsptEnbl_D_Rq 1;
BA_ "U_P708_MY2023_Tx" SG_ 290 WifiHtsptEnbl_D_Rq 1;
BA_ "U_P702_MY2024_Tx" SG_ 290 WifiHtsptEnbl_D_Rq 1;
BA_ "GenSigStartValue" SG_ 290 WifiRemoveIndx_No_Rq 20;
BA_ "U_V710_MY2023_Tx" SG_ 290 WifiRemoveIndx_No_Rq 1;
BA_ "U_P708_MY2023_Tx" SG_ 290 WifiRemoveIndx_No_Rq 1;
BA_ "U_P702_MY2024_Tx" SG_ 290 WifiRemoveIndx_No_Rq 1;
BA_ "GenSigSendType" SG_ 290 WifiRemoveDevc_D_Rq 3;
BA_ "U_V710_MY2023_Tx" SG_ 290 WifiRemoveDevc_D_Rq 1;
BA_ "U_P708_MY2023_Tx" SG_ 290 WifiRemoveDevc_D_Rq 1;
BA_ "U_P702_MY2024_Tx" SG_ 290 WifiRemoveDevc_D_Rq 1;
BA_ "GenSigSendType" SG_ 290 WifiHtsptVisbl_D_Rq 3;
BA_ "U_V710_MY2023_Tx" SG_ 290 WifiHtsptVisbl_D_Rq 1;
BA_ "U_P708_MY2023_Tx" SG_ 290 WifiHtsptVisbl_D_Rq 1;
BA_ "U_P702_MY2024_Tx" SG_ 290 WifiHtsptVisbl_D_Rq 1;
BA_ "GenSigSendType" SG_ 290 WifiHtsptMacAddr_B_Rq 3;
BA_ "U_V710_MY2023_Tx" SG_ 290 WifiHtsptMacAddr_B_Rq 1;
BA_ "U_P708_MY2023_Tx" SG_ 290 WifiHtsptMacAddr_B_Rq 1;
BA_ "U_P702_MY2024_Tx" SG_ 290 WifiHtsptMacAddr_B_Rq 1;
BA_ "U_V710_MY2023_Tx" SG_ 290 WifiDevcListSize_D_Rq 1;
BA_ "U_P708_MY2023_Tx" SG_ 290 WifiDevcListSize_D_Rq 1;
BA_ "U_P702_MY2024_Tx" SG_ 290 WifiDevcListSize_D_Rq 1;
BA_ "GenSigStartValue" SG_ 290 WifiDevcListIndx_No_Rq 22;
BA_ "U_V710_MY2023_Tx" SG_ 290 WifiDevcListIndx_No_Rq 1;
BA_ "U_P708_MY2023_Tx" SG_ 290 WifiDevcListIndx_No_Rq 1;
BA_ "U_P702_MY2024_Tx" SG_ 290 WifiDevcListIndx_No_Rq 1;
BA_ "GenSigSendType" SG_ 290 WifiDevcList_D_Rq 3;
BA_ "U_V710_MY2023_Tx" SG_ 290 WifiDevcList_D_Rq 1;
BA_ "U_P708_MY2023_Tx" SG_ 290 WifiDevcList_D_Rq 1;
BA_ "U_P702_MY2024_Tx" SG_ 290 WifiDevcList_D_Rq 1;
BA_ "GenSigSendType" SG_ 290 WifiDataUsage_D_Rq 3;
BA_ "U_V710_MY2023_Tx" SG_ 290 WifiDataUsage_D_Rq 1;
BA_ "U_P708_MY2023_Tx" SG_ 290 WifiDataUsage_D_Rq 1;
BA_ "U_P702_MY2024_Tx" SG_ 290 WifiDataUsage_D_Rq 1;
BA_ "GenSigSendType" SG_ 290 WifiCarrierInfo_B_Rq 3;
BA_ "U_V710_MY2023_Tx" SG_ 290 WifiCarrierInfo_B_Rq 1;
BA_ "U_P708_MY2023_Tx" SG_ 290 WifiCarrierInfo_B_Rq 1;
BA_ "U_P702_MY2024_Tx" SG_ 290 WifiCarrierInfo_B_Rq 1;
BA_ "GenSigSendType" SG_ 290 WifiHtsptScrty_D_Rq 3;
BA_ "U_V710_MY2023_Tx" SG_ 290 WifiHtsptScrty_D_Rq 1;
BA_ "U_P708_MY2023_Tx" SG_ 290 WifiHtsptScrty_D_Rq 1;
BA_ "U_P702_MY2024_Tx" SG_ 290 WifiHtsptScrty_D_Rq 1;
BA_ "GenSigSendType" SG_ 554 SeatOccRearMsgTxt_B_Rq 3;
BA_ "U_V710_MY2023_Rx" SG_ 554 SeatOccRearMsgTxt_B_Rq 1;
BA_ "U_P708_MY2023_Rx" SG_ 554 SeatOccRearMsgTxt_B_Rq 1;
BA_ "U_P702_MY2024_Rx" SG_ 554 SeatOccRearMsgTxt_B_Rq 1;
BA_ "ECGUsedTxSignal" SG_ 554 SeatOccRearMsgTxt_B_Rq 1;
BA_ "U_CDX74X_MY2024_Tx" SG_ 554 SeatOccRearMsgTxt_B_Rq 1;
BA_ "U_V710_MY2023_Tx" SG_ 554 SeatOccRearMsgTxt_B_Rq 1;
BA_ "GenSigSendType" SG_ 554 Frt_Btn_Status_1st_2 3;
BA_ "U_CDX74X_MY2024_Rx" SG_ 554 Frt_Btn_Status_1st_2 1;
BA_ "ECGUsedTxSignal" SG_ 554 Frt_Btn_Status_1st_2 1;
BA_ "U_CDX74X_MY2024_Tx" SG_ 554 Frt_Btn_Status_1st_2 1;
BA_ "U_V710_MY2023_Tx" SG_ 554 Frt_Btn_Status_1st_2 1;
BA_ "GenSigSendType" SG_ 554 Drv_Set_Tmp2 3;
BA_ "U_CDX74X_MY2024_Rx" SG_ 554 Drv_Set_Tmp2 1;
BA_ "ECGUsedTxSignal" SG_ 554 Drv_Set_Tmp2 1;
BA_ "U_CDX74X_MY2024_Tx" SG_ 554 Drv_Set_Tmp2 1;
BA_ "U_V710_MY2023_Tx" SG_ 554 Drv_Set_Tmp2 1;
BA_ "GenSigSendType" SG_ 554 DrvHazrdModel_D_St 3;
BA_ "U_V713AV_MY2022_Rx" SG_ 554 DrvHazrdModel_D_St 1;
BA_ "U_P708_MY2023_Rx" SG_ 554 DrvHazrdModel_D_St 1;
BA_ "U_V710_MY2023_Rx" SG_ 554 DrvHazrdModel_D_St 1;
BA_ "U_P702_MY2024_Rx" SG_ 554 DrvHazrdModel_D_St 1;
BA_ "ECGUsedTxSignal" SG_ 554 DrvHazrdModel_D_St 1;
BA_ "U_V713N_MY2022_Tx" SG_ 554 DrvHazrdModel_D_St 1;
BA_ "U_V713AV_MY2022_Tx" SG_ 554 DrvHazrdModel_D_St 1;
BA_ "U_CDX74X_MY2024_Tx" SG_ 554 DrvHazrdModel_D_St 1;
BA_ "U_V710_MY2023_Tx" SG_ 554 DrvHazrdModel_D_St 1;
BA_ "GenSigStartValue" SG_ 554 DrvHazrd_D_St 2;
BA_ "GenSigSendType" SG_ 554 DrvHazrd_D_St 3;
BA_ "U_V713AV_MY2022_Rx" SG_ 554 DrvHazrd_D_St 1;
BA_ "U_P708_MY2023_Rx" SG_ 554 DrvHazrd_D_St 1;
BA_ "U_V710_MY2023_Rx" SG_ 554 DrvHazrd_D_St 1;
BA_ "U_P702_MY2024_Rx" SG_ 554 DrvHazrd_D_St 1;
BA_ "ECGUsedTxSignal" SG_ 554 DrvHazrd_D_St 1;
BA_ "U_V713N_MY2022_Tx" SG_ 554 DrvHazrd_D_St 1;
BA_ "U_V713AV_MY2022_Tx" SG_ 554 DrvHazrd_D_St 1;
BA_ "U_CDX74X_MY2024_Tx" SG_ 554 DrvHazrd_D_St 1;
BA_ "U_V710_MY2023_Tx" SG_ 554 DrvHazrd_D_St 1;
BA_ "WakeupSignal" SG_ 554 PtWakeupActv1_B_Rq 1;
BA_ "GenSigSendType" SG_ 554 PtWakeupActv1_B_Rq 3;
BA_ "U_V710_MY2023_Rx" SG_ 554 PtWakeupActv1_B_Rq 1;
BA_ "U_P708_MY2023_Rx" SG_ 554 PtWakeupActv1_B_Rq 1;
BA_ "U_P702_MY2024_Rx" SG_ 554 PtWakeupActv1_B_Rq 1;
BA_ "ECGUsedTxSignal" SG_ 554 PtWakeupActv1_B_Rq 1;
BA_ "U_V713N_MY2022_Tx" SG_ 554 PtWakeupActv1_B_Rq 1;
BA_ "U_V713AV_MY2022_Tx" SG_ 554 PtWakeupActv1_B_Rq 1;
BA_ "U_CDX74X_MY2024_Tx" SG_ 554 PtWakeupActv1_B_Rq 1;
BA_ "U_V710_MY2023_Tx" SG_ 554 PtWakeupActv1_B_Rq 1;
BA_ "U_V713N_MY2022_Rx" SG_ 419 MK_SpeedValue_Rq 1;
BA_ "U_V713AV_MY2022_Rx" SG_ 419 MK_SpeedValue_Rq 1;
BA_ "U_P708_MY2023_Rx" SG_ 419 MK_SpeedValue_Rq 1;
BA_ "U_V710_MY2023_Rx" SG_ 419 MK_SpeedValue_Rq 1;
BA_ "U_P708_MY2023_Tx" SG_ 419 MK_SpeedValue_Rq 1;
BA_ "GenSigSendType" SG_ 419 MK_SpeedSetting_Rq 3;
BA_ "U_V713N_MY2022_Rx" SG_ 419 MK_SpeedSetting_Rq 1;
BA_ "U_V713AV_MY2022_Rx" SG_ 419 MK_SpeedSetting_Rq 1;
BA_ "U_P708_MY2023_Rx" SG_ 419 MK_SpeedSetting_Rq 1;
BA_ "U_V710_MY2023_Rx" SG_ 419 MK_SpeedSetting_Rq 1;
BA_ "U_P708_MY2023_Tx" SG_ 419 MK_SpeedSetting_Rq 1;
BA_ "GenSigSendType" SG_ 419 MK_ResetAllUserKeys_Rq 3;
BA_ "U_V713N_MY2022_Rx" SG_ 419 MK_ResetAllUserKeys_Rq 1;
BA_ "U_V713AV_MY2022_Rx" SG_ 419 MK_ResetAllUserKeys_Rq 1;
BA_ "U_P708_MY2023_Rx" SG_ 419 MK_ResetAllUserKeys_Rq 1;
BA_ "U_V710_MY2023_Rx" SG_ 419 MK_ResetAllUserKeys_Rq 1;
BA_ "U_P708_MY2023_Tx" SG_ 419 MK_ResetAllUserKeys_Rq 1;
BA_ "GenSigSendType" SG_ 419 MK_MyKeySystemInfo_Rq 3;
BA_ "U_V713N_MY2022_Rx" SG_ 419 MK_MyKeySystemInfo_Rq 1;
BA_ "U_V713AV_MY2022_Rx" SG_ 419 MK_MyKeySystemInfo_Rq 1;
BA_ "U_P708_MY2023_Rx" SG_ 419 MK_MyKeySystemInfo_Rq 1;
BA_ "U_V710_MY2023_Rx" SG_ 419 MK_MyKeySystemInfo_Rq 1;
BA_ "U_P708_MY2023_Tx" SG_ 419 MK_MyKeySystemInfo_Rq 1;
BA_ "GenSigSendType" SG_ 419 MK_ESCRestrictConf_Rq 3;
BA_ "U_V713N_MY2022_Rx" SG_ 419 MK_ESCRestrictConf_Rq 1;
BA_ "U_V713AV_MY2022_Rx" SG_ 419 MK_ESCRestrictConf_Rq 1;
BA_ "U_P708_MY2023_Rx" SG_ 419 MK_ESCRestrictConf_Rq 1;
BA_ "U_V710_MY2023_Rx" SG_ 419 MK_ESCRestrictConf_Rq 1;
BA_ "U_P708_MY2023_Tx" SG_ 419 MK_ESCRestrictConf_Rq 1;
BA_ "GenSigSendType" SG_ 419 MK_ECalRestrictConf_Rq 3;
BA_ "U_V713N_MY2022_Rx" SG_ 419 MK_ECalRestrictConf_Rq 1;
BA_ "U_V713AV_MY2022_Rx" SG_ 419 MK_ECalRestrictConf_Rq 1;
BA_ "U_P708_MY2023_Rx" SG_ 419 MK_ECalRestrictConf_Rq 1;
BA_ "U_V710_MY2023_Rx" SG_ 419 MK_ECalRestrictConf_Rq 1;
BA_ "U_P708_MY2023_Tx" SG_ 419 MK_ECalRestrictConf_Rq 1;
BA_ "GenSigSendType" SG_ 419 MK_DNDRestrictConf_Rq 3;
BA_ "U_V713N_MY2022_Rx" SG_ 419 MK_DNDRestrictConf_Rq 1;
BA_ "U_V713AV_MY2022_Rx" SG_ 419 MK_DNDRestrictConf_Rq 1;
BA_ "U_P708_MY2023_Rx" SG_ 419 MK_DNDRestrictConf_Rq 1;
BA_ "U_V710_MY2023_Rx" SG_ 419 MK_DNDRestrictConf_Rq 1;
BA_ "U_P708_MY2023_Tx" SG_ 419 MK_DNDRestrictConf_Rq 1;
BA_ "GenSigSendType" SG_ 419 MK_CreateMyKey_Rq 3;
BA_ "U_V713N_MY2022_Rx" SG_ 419 MK_CreateMyKey_Rq 1;
BA_ "U_V713AV_MY2022_Rx" SG_ 419 MK_CreateMyKey_Rq 1;
BA_ "U_P708_MY2023_Rx" SG_ 419 MK_CreateMyKey_Rq 1;
BA_ "U_V710_MY2023_Rx" SG_ 419 MK_CreateMyKey_Rq 1;
BA_ "U_P708_MY2023_Tx" SG_ 419 MK_CreateMyKey_Rq 1;
BA_ "GenSigSendType" SG_ 419 MK_AudioLimitConfig_Rq 3;
BA_ "U_V713N_MY2022_Rx" SG_ 419 MK_AudioLimitConfig_Rq 1;
BA_ "U_V713AV_MY2022_Rx" SG_ 419 MK_AudioLimitConfig_Rq 1;
BA_ "U_P708_MY2023_Rx" SG_ 419 MK_AudioLimitConfig_Rq 1;
BA_ "U_V710_MY2023_Rx" SG_ 419 MK_AudioLimitConfig_Rq 1;
BA_ "U_P708_MY2023_Tx" SG_ 419 MK_AudioLimitConfig_Rq 1;
BA_ "GenSigSendType" SG_ 419 MK_ACSRestrictConf_Rq 3;
BA_ "U_V713N_MY2022_Rx" SG_ 419 MK_ACSRestrictConf_Rq 1;
BA_ "U_V713AV_MY2022_Rx" SG_ 419 MK_ACSRestrictConf_Rq 1;
BA_ "U_P708_MY2023_Rx" SG_ 419 MK_ACSRestrictConf_Rq 1;
BA_ "U_V710_MY2023_Rx" SG_ 419 MK_ACSRestrictConf_Rq 1;
BA_ "U_P708_MY2023_Tx" SG_ 419 MK_ACSRestrictConf_Rq 1;
BA_ "U_V713N_MY2022_Rx" SG_ 542 LocationServices_3 1;
BA_ "U_V713AV_MY2022_Rx" SG_ 542 LocationServices_3 1;
BA_ "U_P708_MY2023_Rx" SG_ 542 LocationServices_3 1;
BA_ "U_V710_MY2023_Rx" SG_ 542 LocationServices_3 1;
BA_ "U_P702_MY2024_Rx" SG_ 542 LocationServices_3 1;
BA_ "U_P708_MY2023_Rx" SG_ 413 LBS1_ParentID 1;
BA_ "U_CDX74X_MY2024_Rx" SG_ 413 LBS1_ParentID 1;
BA_ "U_V710_MY2023_Tx" SG_ 413 LBS1_ParentID 1;
BA_ "U_P708_MY2023_Tx" SG_ 413 LBS1_ParentID 1;
BA_ "GenSigSendType" SG_ 413 LBS1_ListStatus 3;
BA_ "U_P708_MY2023_Rx" SG_ 413 LBS1_ListStatus 1;
BA_ "U_CDX74X_MY2024_Rx" SG_ 413 LBS1_ListStatus 1;
BA_ "U_V710_MY2023_Tx" SG_ 413 LBS1_ListStatus 1;
BA_ "U_P708_MY2023_Tx" SG_ 413 LBS1_ListStatus 1;
BA_ "U_P708_MY2023_Rx" SG_ 413 LBS1_ListServer 1;
BA_ "U_CDX74X_MY2024_Rx" SG_ 413 LBS1_ListServer 1;
BA_ "U_V710_MY2023_Tx" SG_ 413 LBS1_ListServer 1;
BA_ "U_P708_MY2023_Tx" SG_ 413 LBS1_ListServer 1;
BA_ "U_P708_MY2023_Rx" SG_ 413 LBS1_ListID 1;
BA_ "U_CDX74X_MY2024_Rx" SG_ 413 LBS1_ListID 1;
BA_ "U_V710_MY2023_Tx" SG_ 413 LBS1_ListID 1;
BA_ "U_P708_MY2023_Tx" SG_ 413 LBS1_ListID 1;
BA_ "U_P708_MY2023_Rx" SG_ 413 LBS1_EntryIndex 1;
BA_ "U_CDX74X_MY2024_Rx" SG_ 413 LBS1_EntryIndex 1;
BA_ "U_V710_MY2023_Tx" SG_ 413 LBS1_EntryIndex 1;
BA_ "U_P708_MY2023_Tx" SG_ 413 LBS1_EntryIndex 1;
BA_ "GenSigStartValue" SG_ 898 VedsPrmDirOfF_An_Ltchd 90;
BA_ "U_P708_MY2023_Rx" SG_ 898 VedsPrmDirOfF_An_Ltchd 1;
BA_ "U_P702_MY2024_Rx" SG_ 898 VedsPrmDirOfF_An_Ltchd 1;
BA_ "GenSigStartValue" SG_ 898 VedsRoll_An_Ltchd 4096;
BA_ "U_P708_MY2023_Rx" SG_ 898 VedsRoll_An_Ltchd 1;
BA_ "U_P702_MY2024_Rx" SG_ 898 VedsRoll_An_Ltchd 1;
BA_ "GenSigStartValue" SG_ 898 SecondRowBcklPsngrMid 3;
BA_ "U_P708_MY2023_Rx" SG_ 898 SecondRowBcklPsngrMid 1;
BA_ "U_V710_MY2023_Rx" SG_ 898 SecondRowBcklPsngrMid 1;
BA_ "U_P702_MY2024_Rx" SG_ 898 SecondRowBcklPsngrMid 1;
BA_ "GenSigStartValue" SG_ 898 SecondRowBuckleDrvMid 3;
BA_ "U_P708_MY2023_Rx" SG_ 898 SecondRowBuckleDrvMid 1;
BA_ "U_V710_MY2023_Rx" SG_ 898 SecondRowBuckleDrvMid 1;
BA_ "U_P702_MY2024_Rx" SG_ 898 SecondRowBuckleDrvMid 1;
BA_ "GenSigStartValue" SG_ 898 FourthRowBucklePsngr 3;
BA_ "U_P708_MY2023_Rx" SG_ 898 FourthRowBucklePsngr 1;
BA_ "U_V710_MY2023_Rx" SG_ 898 FourthRowBucklePsngr 1;
BA_ "U_P702_MY2024_Rx" SG_ 898 FourthRowBucklePsngr 1;
BA_ "GenSigStartValue" SG_ 898 FourthRowBuckleMid 3;
BA_ "U_P708_MY2023_Rx" SG_ 898 FourthRowBuckleMid 1;
BA_ "U_V710_MY2023_Rx" SG_ 898 FourthRowBuckleMid 1;
BA_ "U_P702_MY2024_Rx" SG_ 898 FourthRowBuckleMid 1;
BA_ "GenSigStartValue" SG_ 898 FourthRowBuckleDriver 3;
BA_ "U_P708_MY2023_Rx" SG_ 898 FourthRowBuckleDriver 1;
BA_ "U_V710_MY2023_Rx" SG_ 898 FourthRowBuckleDriver 1;
BA_ "U_P702_MY2024_Rx" SG_ 898 FourthRowBuckleDriver 1;
BA_ "GenSigStartValue" SG_ 898 Row3PsngrPrsnc_D_Actl 3;
BA_ "U_P708_MY2023_Rx" SG_ 898 Row3PsngrPrsnc_D_Actl 1;
BA_ "U_V710_MY2023_Rx" SG_ 898 Row3PsngrPrsnc_D_Actl 1;
BA_ "U_P702_MY2024_Rx" SG_ 898 Row3PsngrPrsnc_D_Actl 1;
BA_ "GenSigStartValue" SG_ 898 Row3MidPrsnc_D_Actl 3;
BA_ "U_P708_MY2023_Rx" SG_ 898 Row3MidPrsnc_D_Actl 1;
BA_ "U_V710_MY2023_Rx" SG_ 898 Row3MidPrsnc_D_Actl 1;
BA_ "U_P702_MY2024_Rx" SG_ 898 Row3MidPrsnc_D_Actl 1;
BA_ "GenSigStartValue" SG_ 898 Row3DrvPrsnc_D_Actl 3;
BA_ "U_P708_MY2023_Rx" SG_ 898 Row3DrvPrsnc_D_Actl 1;
BA_ "U_V710_MY2023_Rx" SG_ 898 Row3DrvPrsnc_D_Actl 1;
BA_ "U_P702_MY2024_Rx" SG_ 898 Row3DrvPrsnc_D_Actl 1;
BA_ "GenSigStartValue" SG_ 898 Row2PsngrPrsnc_D_Actl 3;
BA_ "U_P708_MY2023_Rx" SG_ 898 Row2PsngrPrsnc_D_Actl 1;
BA_ "U_V710_MY2023_Rx" SG_ 898 Row2PsngrPrsnc_D_Actl 1;
BA_ "U_P702_MY2024_Rx" SG_ 898 Row2PsngrPrsnc_D_Actl 1;
BA_ "GenSigStartValue" SG_ 898 Row2MidPrsnc_D_Actl 3;
BA_ "U_P708_MY2023_Rx" SG_ 898 Row2MidPrsnc_D_Actl 1;
BA_ "U_V710_MY2023_Rx" SG_ 898 Row2MidPrsnc_D_Actl 1;
BA_ "U_P702_MY2024_Rx" SG_ 898 Row2MidPrsnc_D_Actl 1;
BA_ "GenSigStartValue" SG_ 898 Row2DrvPrsnc_D_Actl 3;
BA_ "U_P708_MY2023_Rx" SG_ 898 Row2DrvPrsnc_D_Actl 1;
BA_ "U_V710_MY2023_Rx" SG_ 898 Row2DrvPrsnc_D_Actl 1;
BA_ "U_P702_MY2024_Rx" SG_ 898 Row2DrvPrsnc_D_Actl 1;
BA_ "GenSigStartValue" SG_ 1020 CtrStkPersIndex2_D_Actl 4;
BA_ "GenSigSendType" SG_ 1020 CtrStkPersIndex2_D_Actl 3;
BA_ "U_P708_MY2023_Rx" SG_ 1020 CtrStkPersIndex2_D_Actl 1;
BA_ "U_V710_MY2023_Rx" SG_ 1020 CtrStkPersIndex2_D_Actl 1;
BA_ "U_P708_MY2023_Tx" SG_ 1020 CtrStkPersIndex2_D_Actl 1;
BA_ "GenSigSendType" SG_ 1020 CtrStkFeat2ConfigActl 3;
BA_ "U_V710_MY2023_Rx" SG_ 1020 CtrStkFeat2ConfigActl 1;
BA_ "U_P708_MY2023_Tx" SG_ 1020 CtrStkFeat2ConfigActl 1;
BA_ "GenSigSendType" SG_ 1020 CtrStkFeat2NoActl 3;
BA_ "U_P708_MY2023_Rx" SG_ 1020 CtrStkFeat2NoActl 1;
BA_ "U_V710_MY2023_Rx" SG_ 1020 CtrStkFeat2NoActl 1;
BA_ "U_P708_MY2023_Tx" SG_ 1020 CtrStkFeat2NoActl 1;
BA_ "GenSigSendType" SG_ 1020 CtrStkDsplyOp2_D_Rq 3;
BA_ "U_P708_MY2023_Rx" SG_ 1020 CtrStkDsplyOp2_D_Rq 1;
BA_ "U_V710_MY2023_Rx" SG_ 1020 CtrStkDsplyOp2_D_Rq 1;
BA_ "U_P708_MY2023_Tx" SG_ 1020 CtrStkDsplyOp2_D_Rq 1;
BA_ "GenSigStartValue" SG_ 1007 PersIndexIpc2_D_Actl 4;
BA_ "GenSigSendType" SG_ 1007 PersIndexIpc2_D_Actl 3;
BA_ "U_P708_MY2023_Rx" SG_ 1007 PersIndexIpc2_D_Actl 1;
BA_ "U_V713N_MY2022_Tx" SG_ 1007 PersIndexIpc2_D_Actl 1;
BA_ "U_P708_MY2023_Tx" SG_ 1007 PersIndexIpc2_D_Actl 1;
BA_ "U_V710_MY2023_Tx" SG_ 1007 PersIndexIpc2_D_Actl 1;
BA_ "GenSigSendType" SG_ 1007 FeatNoIpc2Actl 3;
BA_ "U_P708_MY2023_Rx" SG_ 1007 FeatNoIpc2Actl 1;
BA_ "U_V713N_MY2022_Tx" SG_ 1007 FeatNoIpc2Actl 1;
BA_ "U_P708_MY2023_Tx" SG_ 1007 FeatNoIpc2Actl 1;
BA_ "U_V710_MY2023_Tx" SG_ 1007 FeatNoIpc2Actl 1;
BA_ "GenSigSendType" SG_ 1007 FeatConfigIpc2Actl 3;
BA_ "U_P708_MY2023_Rx" SG_ 1007 FeatConfigIpc2Actl 1;
BA_ "U_V713N_MY2022_Tx" SG_ 1007 FeatConfigIpc2Actl 1;
BA_ "U_P708_MY2023_Tx" SG_ 1007 FeatConfigIpc2Actl 1;
BA_ "U_V710_MY2023_Tx" SG_ 1007 FeatConfigIpc2Actl 1;
BA_ "WakeupSignal" SG_ 1217 DrSwtchExtRr_No_Rq 1;
BA_ "U_P708_MY2023_Rx" SG_ 1217 SldrrStat_B_Actl 1;
BA_ "U_V710_MY2023_Rx" SG_ 1217 SldrrStat_B_Actl 1;
BA_ "WakeupSignal" SG_ 1217 SldrrMsgTxt_D2_Rq 1;
BA_ "U_V713AV_MY2022_Rx" SG_ 1217 SldrrMsgTxt_D2_Rq 1;
BA_ "U_P708_MY2023_Rx" SG_ 1217 SldrrMsgTxt_D2_Rq 1;
BA_ "U_V710_MY2023_Rx" SG_ 1217 SldrrMsgTxt_D2_Rq 1;
BA_ "U_V713N_MY2022_Rx" SG_ 1217 SldrrMsgTxt_D2_Rq 1;
BA_ "WakeupSignal" SG_ 1217 SldrrChime_D_Rq 1;
BA_ "U_V713AV_MY2022_Rx" SG_ 1217 SldrrChime_D_Rq 1;
BA_ "U_P708_MY2023_Rx" SG_ 1217 SldrrChime_D_Rq 1;
BA_ "U_V710_MY2023_Rx" SG_ 1217 SldrrChime_D_Rq 1;
BA_ "U_V713N_MY2022_Rx" SG_ 1217 SldrrChime_D_Rq 1;
BA_ "MetaData" SG_ 1217 SldrrUnlckRollCd_No_Cnt 1;
BA_ "WakeupSignal" SG_ 1217 SldrrUnlck_No_Cnt 1;
BA_ "MetaData" SG_ 1217 SldrrUnlck_No_Cnt 1;
BA_ "WakeupSignal" SG_ 1217 SldrrChildLck_No_Cnt 1;
BA_ "MetaData" SG_ 1217 SldrrChildLck_No_Cnt 1;
BA_ "WakeupSignal" SG_ 1217 Sldrr_D_Stat 1;
BA_ "WakeupSignal" SG_ 1216 DrSwtchExtRl_No_Rq 1;
BA_ "U_P708_MY2023_Rx" SG_ 1216 SldrlStat_B_Actl 1;
BA_ "U_V710_MY2023_Rx" SG_ 1216 SldrlStat_B_Actl 1;
BA_ "WakeupSignal" SG_ 1216 SldrlMsgTxt_D2_Rq 1;
BA_ "U_V713AV_MY2022_Rx" SG_ 1216 SldrlMsgTxt_D2_Rq 1;
BA_ "U_P708_MY2023_Rx" SG_ 1216 SldrlMsgTxt_D2_Rq 1;
BA_ "U_V710_MY2023_Rx" SG_ 1216 SldrlMsgTxt_D2_Rq 1;
BA_ "U_V713N_MY2022_Rx" SG_ 1216 SldrlMsgTxt_D2_Rq 1;
BA_ "WakeupSignal" SG_ 1216 SldrlChime_D_Rq 1;
BA_ "U_V713AV_MY2022_Rx" SG_ 1216 SldrlChime_D_Rq 1;
BA_ "U_P708_MY2023_Rx" SG_ 1216 SldrlChime_D_Rq 1;
BA_ "U_V710_MY2023_Rx" SG_ 1216 SldrlChime_D_Rq 1;
BA_ "U_V713N_MY2022_Rx" SG_ 1216 SldrlChime_D_Rq 1;
BA_ "MetaData" SG_ 1216 SldrlUnlckRollCd_No_Cnt 1;
BA_ "WakeupSignal" SG_ 1216 SldrlUnlck_No_Cnt 1;
BA_ "MetaData" SG_ 1216 SldrlUnlck_No_Cnt 1;
BA_ "WakeupSignal" SG_ 1216 SldrlChildLck_No_Cnt 1;
BA_ "MetaData" SG_ 1216 SldrlChildLck_No_Cnt 1;
BA_ "WakeupSignal" SG_ 1216 Sldrl_D_Stat 1;
BA_ "GenSigStartValue" SG_ 820 TailLghtAnmtn_D_Stat 1;
BA_ "U_V713N_MY2022_Rx" SG_ 820 HeadLghtHiOn_B_StatHcm 1;
BA_ "U_V713AV_MY2022_Rx" SG_ 820 HeadLghtHiOn_B_StatHcm 1;
BA_ "U_P708_MY2023_Rx" SG_ 820 HeadLghtHiOn_B_StatHcm 1;
BA_ "U_V710_MY2023_Rx" SG_ 820 HeadLghtHiOn_B_StatHcm 1;
BA_ "U_P702_MY2024_Rx" SG_ 820 HeadLghtHiOn_B_StatHcm 1;
BA_ "U_V713N_MY2022_Rx" SG_ 820 Adaptive_Hdlmp_Fault 1;
BA_ "U_V713AV_MY2022_Rx" SG_ 820 Adaptive_Hdlmp_Fault 1;
BA_ "U_P708_MY2023_Rx" SG_ 820 Adaptive_Hdlmp_Fault 1;
BA_ "U_V710_MY2023_Rx" SG_ 820 Adaptive_Hdlmp_Fault 1;
BA_ "U_P702_MY2024_Rx" SG_ 820 Adaptive_Hdlmp_Fault 1;
BA_ "U_P702_MY2024_Rx" SG_ 1247 TrlrBrkCtl3_B_Falt 1;
BA_ "MetaData" SG_ 1247 StopLampBRqTrlrAft_No_Cs 1;
BA_ "U_P702_MY2024_Rx" SG_ 1247 StopLampBRqTrlrAft_No_Cs 1;
BA_ "MetaData" SG_ 1247 StopLampBRqTrlrAft_No_Cnt 1;
BA_ "U_P702_MY2024_Rx" SG_ 1247 StopLampBRqTrlrAft_No_Cnt 1;
BA_ "U_P702_MY2024_Rx" SG_ 1247 StopLamp_B_RqTrlrAft 1;
BA_ "GenSigSendType" SG_ 677 SeatFnPsgr_D_Rq3 3;
BA_ "U_CDX74X_MY2024_Tx" SG_ 677 SeatFnPsgr_D_Rq3 1;
BA_ "GenSigSendType" SG_ 677 SeatFnDrv_D_Rq3 3;
BA_ "U_CDX74X_MY2024_Tx" SG_ 677 SeatFnDrv_D_Rq3 1;
BA_ "GenSigSendType" SG_ 677 SeatMasgPsngrRr_D_Rq2 3;
BA_ "U_CDX74X_MY2024_Tx" SG_ 677 SeatMasgPsngrRr_D_Rq2 1;
BA_ "GenSigSendType" SG_ 677 SeatMasgDrvRr_D_Rq2 3;
BA_ "U_CDX74X_MY2024_Tx" SG_ 677 SeatMasgDrvRr_D_Rq2 1;
BA_ "GenSigSendType" SG_ 677 SeatFnChngPsgr2_D_Rq3 3;
BA_ "U_CDX74X_MY2024_Tx" SG_ 677 SeatFnChngPsgr2_D_Rq3 1;
BA_ "GenSigSendType" SG_ 677 SeatFnChngDrv2_D_Rq3 3;
BA_ "U_CDX74X_MY2024_Tx" SG_ 677 SeatFnChngDrv2_D_Rq3 1;
BA_ "U_V713N_MY2022_Rx" SG_ 582 PtLatchActv_B_RqBcm 1;
BA_ "U_P708_MY2023_Rx" SG_ 582 PtLatchActv_B_RqBcm 1;
BA_ "U_V710_MY2023_Rx" SG_ 582 PtLatchActv_B_RqBcm 1;
BA_ "U_V713AV_MY2022_Rx" SG_ 582 PtLatchActv_B_RqBcm 1;
BA_ "U_P702_MY2024_Rx" SG_ 582 PtLatchActv_B_RqBcm 1;
BA_ "U_V713AV_MY2022_Rx" SG_ 582 immoSecureIdleMode 1;
BA_ "U_P708_MY2023_Rx" SG_ 582 immoSecureIdleMode 1;
BA_ "U_V710_MY2023_Rx" SG_ 582 immoSecureIdleMode 1;
BA_ "U_P702_MY2024_Rx" SG_ 582 immoSecureIdleMode 1;
BA_ "WakeupSignal" SG_ 582 ReFuelSwtchStat_D_Actl 1;
BA_ "GenSigStartValue" SG_ 582 BattULo_U_Actl 255;
BA_ "U_V713N_MY2022_Rx" SG_ 582 PrkLckCtl_B_Enbl 1;
BA_ "U_P708_MY2023_Rx" SG_ 582 PrkLckCtl_B_Enbl 1;
BA_ "U_V713AV_MY2022_Rx" SG_ 582 PrkLckCtl_B_Enbl 1;
BA_ "U_V710_MY2023_Rx" SG_ 582 PrkLckCtl_B_Enbl 1;
BA_ "U_P702_MY2024_Rx" SG_ 582 PrkLckCtl_B_Enbl 1;
BA_ "WakeupSignal" SG_ 582 PrkLckCtlMsgTxt_D_Rq 1;
BA_ "U_V713N_MY2022_Rx" SG_ 582 PrkLckCtlMsgTxt_D_Rq 1;
BA_ "U_P708_MY2023_Rx" SG_ 582 PrkLckCtlMsgTxt_D_Rq 1;
BA_ "U_V710_MY2023_Rx" SG_ 582 PrkLckCtlMsgTxt_D_Rq 1;
BA_ "U_V713AV_MY2022_Rx" SG_ 582 PrkLckCtlMsgTxt_D_Rq 1;
BA_ "U_P702_MY2024_Rx" SG_ 582 PrkLckCtlMsgTxt_D_Rq 1;
BA_ "WakeupSignal" SG_ 582 PrkLckCtlAvail_T_Stat 1;
BA_ "U_V713N_MY2022_Rx" SG_ 582 PrkLckCtlAvail_T_Stat 1;
BA_ "U_P708_MY2023_Rx" SG_ 582 PrkLckCtlAvail_T_Stat 1;
BA_ "U_V710_MY2023_Rx" SG_ 582 PrkLckCtlAvail_T_Stat 1;
BA_ "U_V713AV_MY2022_Rx" SG_ 582 PrkLckCtlAvail_T_Stat 1;
BA_ "U_P702_MY2024_Rx" SG_ 582 PrkLckCtlAvail_T_Stat 1;
BA_ "U_V713N_MY2022_Rx" SG_ 582 PrkLckCtlUnlck_D_Stat 1;
BA_ "U_P708_MY2023_Rx" SG_ 582 PrkLckCtlUnlck_D_Stat 1;
BA_ "U_V710_MY2023_Rx" SG_ 582 PrkLckCtlUnlck_D_Stat 1;
BA_ "U_V713AV_MY2022_Rx" SG_ 582 PrkLckCtlUnlck_D_Stat 1;
BA_ "U_P702_MY2024_Rx" SG_ 582 PrkLckCtlUnlck_D_Stat 1;
BA_ "U_V713N_MY2022_Rx" SG_ 582 PrkLckCtlTow_B_Enbl 1;
BA_ "U_P708_MY2023_Rx" SG_ 582 PrkLckCtlTow_B_Enbl 1;
BA_ "U_V713AV_MY2022_Rx" SG_ 582 PrkLckCtlTow_B_Enbl 1;
BA_ "U_V710_MY2023_Rx" SG_ 582 PrkLckCtlTow_B_Enbl 1;
BA_ "U_P702_MY2024_Rx" SG_ 582 PrkLckCtlTow_B_Enbl 1;
BA_ "U_V713N_MY2022_Rx" SG_ 582 EngOff_T_Actl 1;
BA_ "U_P708_MY2023_Rx" SG_ 582 EngOff_T_Actl 1;
BA_ "U_V713AV_MY2022_Rx" SG_ 582 EngOff_T_Actl 1;
BA_ "U_V710_MY2023_Rx" SG_ 582 EngOff_T_Actl 1;
BA_ "U_P702_MY2024_Rx" SG_ 582 EngOff_T_Actl 1;
BA_ "GenSigStartValue" SG_ 582 BattULo_I_Actl 16383;
BA_ "U_V713N_MY2022_Rx" SG_ 1036 PdstrnAlrt_B_Falt 1;
BA_ "U_P708_MY2023_Rx" SG_ 1036 PdstrnAlrt_B_Falt 1;
BA_ "U_V710_MY2023_Rx" SG_ 1036 PdstrnAlrt_B_Falt 1;
BA_ "U_V713AV_MY2022_Rx" SG_ 1036 PdstrnAlrt_B_Falt 1;
BA_ "U_P702_MY2024_Rx" SG_ 1036 PdstrnAlrt_B_Falt 1;
BA_ "U_V713N_MY2022_Rx" SG_ 1047 TrlrAidTrlrId_No_Rq 1;
BA_ "U_V713AV_MY2022_Rx" SG_ 1047 TrlrAidTrlrId_No_Rq 1;
BA_ "U_P708_MY2023_Rx" SG_ 1047 TrlrAidTrlrId_No_Rq 1;
BA_ "U_V710_MY2023_Rx" SG_ 1047 TrlrAidTrlrId_No_Rq 1;
BA_ "U_P702_MY2024_Rx" SG_ 1047 TrlrAidTrlrId_No_Rq 1;
BA_ "U_V713N_MY2022_Rx" SG_ 1047 TrlrAidEnbl_D2_Stat 1;
BA_ "U_V713AV_MY2022_Rx" SG_ 1047 TrlrAidEnbl_D2_Stat 1;
BA_ "U_P708_MY2023_Rx" SG_ 1047 TrlrAidEnbl_D2_Stat 1;
BA_ "U_P702_MY2024_Rx" SG_ 1047 TrlrAidEnbl_D2_Stat 1;
BA_ "U_V710_MY2023_Rx" SG_ 1047 TrlrAidEnbl_D2_Stat 1;
BA_ "U_V713N_MY2022_Rx" SG_ 1047 TrlrAidMsgTxt_D2_Rq 1;
BA_ "U_V713AV_MY2022_Rx" SG_ 1047 TrlrAidMsgTxt_D2_Rq 1;
BA_ "U_P708_MY2023_Rx" SG_ 1047 TrlrAidMsgTxt_D2_Rq 1;
BA_ "U_V710_MY2023_Rx" SG_ 1047 TrlrAidMsgTxt_D2_Rq 1;
BA_ "U_P702_MY2024_Rx" SG_ 1047 TrlrAidMsgTxt_D2_Rq 1;
BA_ "GenSigStartValue" SG_ 1047 EsaOn_B_Stat 1;
BA_ "U_V713N_MY2022_Rx" SG_ 1047 EsaOn_B_Stat 1;
BA_ "U_P708_MY2023_Rx" SG_ 1047 EsaOn_B_Stat 1;
BA_ "U_V713AV_MY2022_Rx" SG_ 1047 EsaOn_B_Stat 1;
BA_ "U_V710_MY2023_Rx" SG_ 1047 EsaOn_B_Stat 1;
BA_ "U_P702_MY2024_Rx" SG_ 1047 EsaOn_B_Stat 1;
BA_ "U_V713AV_MY2022_Rx" SG_ 688 APIM_TCUB_Word_Rx 1;
BA_ "U_P708_MY2023_Rx" SG_ 688 APIM_TCUB_Word_Rx 1;
BA_ "U_V710_MY2023_Rx" SG_ 688 APIM_TCUB_Word_Rx 1;
BA_ "U_V713AV_MY2022_Tx" SG_ 696 APIM_TCUB_Word_Tx 1;
BA_ "U_P708_MY2023_Tx" SG_ 696 APIM_TCUB_Word_Tx 1;
BA_ "U_V710_MY2023_Tx" SG_ 696 APIM_TCUB_Word_Tx 1;
BA_ "U_V713AV_MY2022_Rx" SG_ 1236 ApaSlotRearX_L_Actl 1;
BA_ "U_P708_MY2023_Rx" SG_ 1236 ApaSlotRearX_L_Actl 1;
BA_ "U_V710_MY2023_Rx" SG_ 1236 ApaSlotRearX_L_Actl 1;
BA_ "U_P702_MY2024_Rx" SG_ 1236 ApaSlotRearX_L_Actl 1;
BA_ "U_V713AV_MY2022_Rx" SG_ 1236 ApaSlotRight3X_L_Actl 1;
BA_ "U_P708_MY2023_Rx" SG_ 1236 ApaSlotRight3X_L_Actl 1;
BA_ "U_V710_MY2023_Rx" SG_ 1236 ApaSlotRight3X_L_Actl 1;
BA_ "U_P702_MY2024_Rx" SG_ 1236 ApaSlotRight3X_L_Actl 1;
BA_ "U_V713AV_MY2022_Rx" SG_ 1236 ApaSlotRight3_D_Stat 1;
BA_ "U_P708_MY2023_Rx" SG_ 1236 ApaSlotRight3_D_Stat 1;
BA_ "U_V710_MY2023_Rx" SG_ 1236 ApaSlotRight3_D_Stat 1;
BA_ "U_P702_MY2024_Rx" SG_ 1236 ApaSlotRight3_D_Stat 1;
BA_ "U_V713AV_MY2022_Rx" SG_ 1236 ApaSlotRight3_B_Altr 1;
BA_ "U_P708_MY2023_Rx" SG_ 1236 ApaSlotRight3_B_Altr 1;
BA_ "U_V710_MY2023_Rx" SG_ 1236 ApaSlotRight3_B_Altr 1;
BA_ "U_P702_MY2024_Rx" SG_ 1236 ApaSlotRight3_B_Altr 1;
BA_ "U_V713AV_MY2022_Rx" SG_ 1236 ApaSlotRight2X_L_Actl 1;
BA_ "U_P708_MY2023_Rx" SG_ 1236 ApaSlotRight2X_L_Actl 1;
BA_ "U_V710_MY2023_Rx" SG_ 1236 ApaSlotRight2X_L_Actl 1;
BA_ "U_P702_MY2024_Rx" SG_ 1236 ApaSlotRight2X_L_Actl 1;
BA_ "U_V713AV_MY2022_Rx" SG_ 1236 ApaSlotRight2_D_Stat 1;
BA_ "U_P708_MY2023_Rx" SG_ 1236 ApaSlotRight2_D_Stat 1;
BA_ "U_V710_MY2023_Rx" SG_ 1236 ApaSlotRight2_D_Stat 1;
BA_ "U_P702_MY2024_Rx" SG_ 1236 ApaSlotRight2_D_Stat 1;
BA_ "U_V713AV_MY2022_Rx" SG_ 1236 ApaSlotRight2_B_Altr 1;
BA_ "U_P708_MY2023_Rx" SG_ 1236 ApaSlotRight2_B_Altr 1;
BA_ "U_V710_MY2023_Rx" SG_ 1236 ApaSlotRight2_B_Altr 1;
BA_ "U_P702_MY2024_Rx" SG_ 1236 ApaSlotRight2_B_Altr 1;
BA_ "U_V713AV_MY2022_Rx" SG_ 1236 ApaSlotRight1X_L_Actl 1;
BA_ "U_P708_MY2023_Rx" SG_ 1236 ApaSlotRight1X_L_Actl 1;
BA_ "U_V710_MY2023_Rx" SG_ 1236 ApaSlotRight1X_L_Actl 1;
BA_ "U_P702_MY2024_Rx" SG_ 1236 ApaSlotRight1X_L_Actl 1;
BA_ "U_V713AV_MY2022_Rx" SG_ 1236 ApaSlotRight1_D_Stat 1;
BA_ "U_P708_MY2023_Rx" SG_ 1236 ApaSlotRight1_D_Stat 1;
BA_ "U_V710_MY2023_Rx" SG_ 1236 ApaSlotRight1_D_Stat 1;
BA_ "U_P702_MY2024_Rx" SG_ 1236 ApaSlotRight1_D_Stat 1;
BA_ "U_V713AV_MY2022_Rx" SG_ 1236 ApaSlotRight1_B_Altr 1;
BA_ "U_P708_MY2023_Rx" SG_ 1236 ApaSlotRight1_B_Altr 1;
BA_ "U_V710_MY2023_Rx" SG_ 1236 ApaSlotRight1_B_Altr 1;
BA_ "U_P702_MY2024_Rx" SG_ 1236 ApaSlotRight1_B_Altr 1;
BA_ "GenSigStartValue" SG_ 1236 ApaSlotRearY_L_Actl 32;
BA_ "U_V713AV_MY2022_Rx" SG_ 1236 ApaSlotRearY_L_Actl 1;
BA_ "U_P708_MY2023_Rx" SG_ 1236 ApaSlotRearY_L_Actl 1;
BA_ "U_V710_MY2023_Rx" SG_ 1236 ApaSlotRearY_L_Actl 1;
BA_ "U_P702_MY2024_Rx" SG_ 1236 ApaSlotRearY_L_Actl 1;
BA_ "U_V713AV_MY2022_Rx" SG_ 1236 ApaSlotRear_D_Stat 1;
BA_ "U_P708_MY2023_Rx" SG_ 1236 ApaSlotRear_D_Stat 1;
BA_ "U_V710_MY2023_Rx" SG_ 1236 ApaSlotRear_D_Stat 1;
BA_ "U_P702_MY2024_Rx" SG_ 1236 ApaSlotRear_D_Stat 1;
BA_ "U_V713AV_MY2022_Rx" SG_ 1235 ApaSlotFront_D_Stat 1;
BA_ "U_P708_MY2023_Rx" SG_ 1235 ApaSlotFront_D_Stat 1;
BA_ "U_V710_MY2023_Rx" SG_ 1235 ApaSlotFront_D_Stat 1;
BA_ "U_P702_MY2024_Rx" SG_ 1235 ApaSlotFront_D_Stat 1;
BA_ "U_V713AV_MY2022_Rx" SG_ 1235 ApaSlotLeft3X_L_Actl 1;
BA_ "U_P708_MY2023_Rx" SG_ 1235 ApaSlotLeft3X_L_Actl 1;
BA_ "U_V710_MY2023_Rx" SG_ 1235 ApaSlotLeft3X_L_Actl 1;
BA_ "U_P702_MY2024_Rx" SG_ 1235 ApaSlotLeft3X_L_Actl 1;
BA_ "U_V713AV_MY2022_Rx" SG_ 1235 ApaSlotLeft3_D_Stat 1;
BA_ "U_P708_MY2023_Rx" SG_ 1235 ApaSlotLeft3_D_Stat 1;
BA_ "U_V710_MY2023_Rx" SG_ 1235 ApaSlotLeft3_D_Stat 1;
BA_ "U_P702_MY2024_Rx" SG_ 1235 ApaSlotLeft3_D_Stat 1;
BA_ "U_V713AV_MY2022_Rx" SG_ 1235 ApaSlotLeft3_B_Altr 1;
BA_ "U_P708_MY2023_Rx" SG_ 1235 ApaSlotLeft3_B_Altr 1;
BA_ "U_V710_MY2023_Rx" SG_ 1235 ApaSlotLeft3_B_Altr 1;
BA_ "U_P702_MY2024_Rx" SG_ 1235 ApaSlotLeft3_B_Altr 1;
BA_ "U_V713AV_MY2022_Rx" SG_ 1235 ApaSlotFrontX_L_Actl 1;
BA_ "U_P708_MY2023_Rx" SG_ 1235 ApaSlotFrontX_L_Actl 1;
BA_ "U_V710_MY2023_Rx" SG_ 1235 ApaSlotFrontX_L_Actl 1;
BA_ "U_P702_MY2024_Rx" SG_ 1235 ApaSlotFrontX_L_Actl 1;
BA_ "GenSigStartValue" SG_ 1235 ApaSlotFrontY_L_Actl 32;
BA_ "U_V713AV_MY2022_Rx" SG_ 1235 ApaSlotFrontY_L_Actl 1;
BA_ "U_P708_MY2023_Rx" SG_ 1235 ApaSlotFrontY_L_Actl 1;
BA_ "U_V710_MY2023_Rx" SG_ 1235 ApaSlotFrontY_L_Actl 1;
BA_ "U_P702_MY2024_Rx" SG_ 1235 ApaSlotFrontY_L_Actl 1;
BA_ "U_V713AV_MY2022_Rx" SG_ 1235 ApaSlotLeft2X_L_Actl 1;
BA_ "U_P708_MY2023_Rx" SG_ 1235 ApaSlotLeft2X_L_Actl 1;
BA_ "U_V710_MY2023_Rx" SG_ 1235 ApaSlotLeft2X_L_Actl 1;
BA_ "U_P702_MY2024_Rx" SG_ 1235 ApaSlotLeft2X_L_Actl 1;
BA_ "U_V713AV_MY2022_Rx" SG_ 1235 ApaSlotLeft2_D_Stat 1;
BA_ "U_P708_MY2023_Rx" SG_ 1235 ApaSlotLeft2_D_Stat 1;
BA_ "U_V710_MY2023_Rx" SG_ 1235 ApaSlotLeft2_D_Stat 1;
BA_ "U_P702_MY2024_Rx" SG_ 1235 ApaSlotLeft2_D_Stat 1;
BA_ "U_V713AV_MY2022_Rx" SG_ 1235 ApaSlotLeft2_B_Altr 1;
BA_ "U_P708_MY2023_Rx" SG_ 1235 ApaSlotLeft2_B_Altr 1;
BA_ "U_V710_MY2023_Rx" SG_ 1235 ApaSlotLeft2_B_Altr 1;
BA_ "U_P702_MY2024_Rx" SG_ 1235 ApaSlotLeft2_B_Altr 1;
BA_ "U_V713AV_MY2022_Rx" SG_ 1235 ApaSlotLeft1X_L_Actl 1;
BA_ "U_P708_MY2023_Rx" SG_ 1235 ApaSlotLeft1X_L_Actl 1;
BA_ "U_V710_MY2023_Rx" SG_ 1235 ApaSlotLeft1X_L_Actl 1;
BA_ "U_P702_MY2024_Rx" SG_ 1235 ApaSlotLeft1X_L_Actl 1;
BA_ "U_V713AV_MY2022_Rx" SG_ 1235 ApaSlotLeft1_D_Stat 1;
BA_ "U_P708_MY2023_Rx" SG_ 1235 ApaSlotLeft1_D_Stat 1;
BA_ "U_V710_MY2023_Rx" SG_ 1235 ApaSlotLeft1_D_Stat 1;
BA_ "U_P702_MY2024_Rx" SG_ 1235 ApaSlotLeft1_D_Stat 1;
BA_ "U_V713AV_MY2022_Rx" SG_ 1235 ApaSlotLeft1_B_Altr 1;
BA_ "U_P708_MY2023_Rx" SG_ 1235 ApaSlotLeft1_B_Altr 1;
BA_ "U_V710_MY2023_Rx" SG_ 1235 ApaSlotLeft1_B_Altr 1;
BA_ "U_P702_MY2024_Rx" SG_ 1235 ApaSlotLeft1_B_Altr 1;
BA_ "U_V710_MY2023_Rx" SG_ 841 FohStrtDateDay_No_Stat 1;
BA_ "U_V713AV_MY2022_Rx" SG_ 841 FohStrtDateDay_No_Stat 1;
BA_ "U_P708_MY2023_Rx" SG_ 841 FohStrtDateDay_No_Stat 1;
BA_ "U_P702_MY2024_Rx" SG_ 841 FohStrtDateDay_No_Stat 1;
BA_ "U_V710_MY2023_Rx" SG_ 841 FohStrtDateYr_No_Stat 1;
BA_ "U_V713AV_MY2022_Rx" SG_ 841 FohStrtDateYr_No_Stat 1;
BA_ "U_P708_MY2023_Rx" SG_ 841 FohStrtDateYr_No_Stat 1;
BA_ "U_P702_MY2024_Rx" SG_ 841 FohStrtDateYr_No_Stat 1;
BA_ "U_V713AV_MY2022_Rx" SG_ 841 FohAddHeater_D_Stat 1;
BA_ "U_P708_MY2023_Rx" SG_ 841 FohAddHeater_D_Stat 1;
BA_ "U_V710_MY2023_Rx" SG_ 841 FohAddHeater_D_Stat 1;
BA_ "U_P702_MY2024_Rx" SG_ 841 FohAddHeater_D_Stat 1;
BA_ "U_V713N_MY2022_Rx" SG_ 1189 PwStepMsgTxt_D_Rq 1;
BA_ "U_P708_MY2023_Rx" SG_ 1189 PwStepMsgTxt_D_Rq 1;
BA_ "U_V713AV_MY2022_Rx" SG_ 1189 PwStepMsgTxt_D_Rq 1;
BA_ "U_V710_MY2023_Rx" SG_ 1189 PwStepMsgTxt_D_Rq 1;
BA_ "U_P702_MY2024_Rx" SG_ 1189 PwStepMsgTxt_D_Rq 1;
BA_ "U_V713N_MY2022_Rx" SG_ 1189 Running_Board_Stat 1;
BA_ "U_P708_MY2023_Rx" SG_ 1189 Running_Board_Stat 1;
BA_ "U_V710_MY2023_Rx" SG_ 1189 Running_Board_Stat 1;
BA_ "U_V713AV_MY2022_Rx" SG_ 1189 Running_Board_Stat 1;
BA_ "U_P702_MY2024_Rx" SG_ 1189 Running_Board_Stat 1;
BA_ "U_V710_MY2023_Rx" SG_ 772 SeatRelxPosDact_B_Stat 1;
BA_ "U_P708_MY2023_Rx" SG_ 772 SeatRelxPosDact_B_Stat 1;
BA_ "U_P702_MY2024_Rx" SG_ 772 SeatRelxPosDact_B_Stat 1;
BA_ "U_V710_MY2023_Rx" SG_ 772 SeatRelxPosActv_B_Stat 1;
BA_ "U_P708_MY2023_Rx" SG_ 772 SeatRelxPosActv_B_Stat 1;
BA_ "U_P702_MY2024_Rx" SG_ 772 SeatRelxPosActv_B_Stat 1;
BA_ "U_V710_MY2023_Rx" SG_ 772 SeatRelxPosSet_B_Stat 1;
BA_ "U_P708_MY2023_Rx" SG_ 772 SeatRelxPosSet_B_Stat 1;
BA_ "U_P702_MY2024_Rx" SG_ 772 SeatRelxPosSet_B_Stat 1;
BA_ "WakeupSignal" SG_ 772 SeatScrnDrvOn_B_Rq 1;
BA_ "U_V713AV_MY2022_Rx" SG_ 772 SeatScrnDrvOn_B_Rq 1;
BA_ "U_P708_MY2023_Rx" SG_ 772 SeatScrnDrvOn_B_Rq 1;
BA_ "U_V710_MY2023_Rx" SG_ 772 SeatScrnDrvOn_B_Rq 1;
BA_ "U_P702_MY2024_Rx" SG_ 772 SeatScrnDrvOn_B_Rq 1;
BA_ "U_V713N_MY2022_Rx" SG_ 772 PwRnngBoardT_D_Stat 1;
BA_ "U_P708_MY2023_Rx" SG_ 772 PwRnngBoardT_D_Stat 1;
BA_ "U_V713AV_MY2022_Rx" SG_ 772 PwRnngBoardT_D_Stat 1;
BA_ "U_V710_MY2023_Rx" SG_ 772 PwRnngBoardT_D_Stat 1;
BA_ "U_P702_MY2024_Rx" SG_ 772 PwRnngBoardT_D_Stat 1;
BA_ "U_V713N_MY2022_Rx" SG_ 772 PwRnngBoardSwtch_D_Stat 1;
BA_ "U_P708_MY2023_Rx" SG_ 772 PwRnngBoardSwtch_D_Stat 1;
BA_ "U_V713AV_MY2022_Rx" SG_ 772 PwRnngBoardSwtch_D_Stat 1;
BA_ "U_V710_MY2023_Rx" SG_ 772 PwRnngBoardSwtch_D_Stat 1;
BA_ "U_P702_MY2024_Rx" SG_ 772 PwRnngBoardSwtch_D_Stat 1;
BA_ "U_V713N_MY2022_Rx" SG_ 772 SeatSlprPosMsgTxt_B_Rq 1;
BA_ "U_P708_MY2023_Rx" SG_ 772 SeatSlprPosMsgTxt_B_Rq 1;
BA_ "U_V710_MY2023_Rx" SG_ 772 SeatSlprPosMsgTxt_B_Rq 1;
BA_ "U_P702_MY2024_Rx" SG_ 772 SeatSlprPosMsgTxt_B_Rq 1;
BA_ "U_V713N_MY2022_Rx" SG_ 772 MemDrvDeny_B_Stat 1;
BA_ "U_P708_MY2023_Rx" SG_ 772 MemDrvDeny_B_Stat 1;
BA_ "U_V710_MY2023_Rx" SG_ 772 MemDrvDeny_B_Stat 1;
BA_ "U_V713AV_MY2022_Rx" SG_ 772 MemDrvDeny_B_Stat 1;
BA_ "U_P702_MY2024_Rx" SG_ 772 MemDrvDeny_B_Stat 1;
BA_ "WakeupSignal" SG_ 772 Memory_Feedback_Rqst 1;
BA_ "U_V713N_MY2022_Rx" SG_ 772 Memory_Feedback_Rqst 1;
BA_ "U_P708_MY2023_Rx" SG_ 772 Memory_Feedback_Rqst 1;
BA_ "U_V710_MY2023_Rx" SG_ 772 Memory_Feedback_Rqst 1;
BA_ "U_V713AV_MY2022_Rx" SG_ 772 Memory_Feedback_Rqst 1;
BA_ "U_P702_MY2024_Rx" SG_ 772 Memory_Feedback_Rqst 1;
BA_ "WakeupSignal" SG_ 772 Easy_Entry_Rqst 1;
BA_ "WakeupSignal" SG_ 772 Memory_Cmd 1;
BA_ "U_V713N_MY2022_Rx" SG_ 772 Memory_Cmd 1;
BA_ "U_P708_MY2023_Rx" SG_ 772 Memory_Cmd 1;
BA_ "U_V713AV_MY2022_Rx" SG_ 772 Memory_Cmd 1;
BA_ "U_V710_MY2023_Rx" SG_ 772 Memory_Cmd 1;
BA_ "U_P702_MY2024_Rx" SG_ 772 Memory_Cmd 1;
BA_ "WakeupSignal" SG_ 772 Cancel_Auto_Movement 1;
BA_ "U_V713AV_MY2022_Rx" SG_ 1054 TrailCtl_D_Stat 1;
BA_ "U_P708_MY2023_Rx" SG_ 1054 TrailCtl_D_Stat 1;
BA_ "U_V710_MY2023_Rx" SG_ 1054 TrailCtl_D_Stat 1;
BA_ "U_P702_MY2024_Rx" SG_ 1054 TrailCtl_D_Stat 1;
BA_ "U_V713AV_MY2022_Rx" SG_ 1054 TrailCtlMsgTxt_D_Rq 1;
BA_ "U_P708_MY2023_Rx" SG_ 1054 TrailCtlMsgTxt_D_Rq 1;
BA_ "U_V710_MY2023_Rx" SG_ 1054 TrailCtlMsgTxt_D_Rq 1;
BA_ "U_P702_MY2024_Rx" SG_ 1054 TrailCtlMsgTxt_D_Rq 1;
BA_ "U_V713N_MY2022_Rx" SG_ 1054 BrkPadMsgTxt_D_Rq 1;
BA_ "U_P708_MY2023_Rx" SG_ 1054 BrkPadMsgTxt_D_Rq 1;
BA_ "U_V710_MY2023_Rx" SG_ 1054 BrkPadMsgTxt_D_Rq 1;
BA_ "U_V713AV_MY2022_Rx" SG_ 1054 BrkPadMsgTxt_D_Rq 1;
BA_ "U_P702_MY2024_Rx" SG_ 1054 BrkPadMsgTxt_D_Rq 1;
BA_ "U_V713N_MY2022_Rx" SG_ 1054 DrvSlipCtlOffLamp_D_Rq 1;
BA_ "U_P708_MY2023_Rx" SG_ 1054 DrvSlipCtlOffLamp_D_Rq 1;
BA_ "U_V710_MY2023_Rx" SG_ 1054 DrvSlipCtlOffLamp_D_Rq 1;
BA_ "U_P702_MY2024_Rx" SG_ 1054 DrvSlipCtlOffLamp_D_Rq 1;
BA_ "U_V713N_MY2022_Rx" SG_ 1054 DrvSlipCtlMdeMsg_D_Rq 1;
BA_ "U_P708_MY2023_Rx" SG_ 1054 DrvSlipCtlMdeMsg_D_Rq 1;
BA_ "U_V710_MY2023_Rx" SG_ 1054 DrvSlipCtlMdeMsg_D_Rq 1;
BA_ "U_P702_MY2024_Rx" SG_ 1054 DrvSlipCtlMdeMsg_D_Rq 1;
BA_ "U_V713N_MY2022_Rx" SG_ 1054 HdcOn_B_Ind 1;
BA_ "U_P708_MY2023_Rx" SG_ 1054 HdcOn_B_Ind 1;
BA_ "U_V713AV_MY2022_Rx" SG_ 1054 HdcOn_B_Ind 1;
BA_ "U_V710_MY2023_Rx" SG_ 1054 HdcOn_B_Ind 1;
BA_ "U_P702_MY2024_Rx" SG_ 1054 HdcOn_B_Ind 1;
BA_ "U_V713N_MY2022_Rx" SG_ 1054 AutoHoldMsgTxt_D_Rq 1;
BA_ "U_P708_MY2023_Rx" SG_ 1054 AutoHoldMsgTxt_D_Rq 1;
BA_ "U_V710_MY2023_Rx" SG_ 1054 AutoHoldMsgTxt_D_Rq 1;
BA_ "U_V713AV_MY2022_Rx" SG_ 1054 AutoHoldMsgTxt_D_Rq 1;
BA_ "U_P702_MY2024_Rx" SG_ 1054 AutoHoldMsgTxt_D_Rq 1;
BA_ "GenSigStartValue" SG_ 1054 SelDrvMdeAwd_D_Rq 31;
BA_ "U_P708_MY2023_Rx" SG_ 1054 AutoHoldSwMde_B_Ind 1;
BA_ "U_V710_MY2023_Rx" SG_ 1054 AutoHoldSwMde_B_Ind 1;
BA_ "U_P702_MY2024_Rx" SG_ 1054 AutoHoldSwMde_B_Ind 1;
BA_ "U_V713N_MY2022_Rx" SG_ 1054 AutoHoldMde_D_Ind 1;
BA_ "U_P708_MY2023_Rx" SG_ 1054 AutoHoldMde_D_Ind 1;
BA_ "U_V710_MY2023_Rx" SG_ 1054 AutoHoldMde_D_Ind 1;
BA_ "U_V713AV_MY2022_Rx" SG_ 1054 AutoHoldMde_D_Ind 1;
BA_ "U_P702_MY2024_Rx" SG_ 1054 AutoHoldMde_D_Ind 1;
BA_ "WakeupSignal" SG_ 1054 BrkMdeInhbt_B_RqDsply 1;
BA_ "U_V713N_MY2022_Rx" SG_ 1054 BrkMdeInhbt_B_RqDsply 1;
BA_ "U_P708_MY2023_Rx" SG_ 1054 BrkMdeInhbt_B_RqDsply 1;
BA_ "U_V713AV_MY2022_Rx" SG_ 1054 BrkMdeInhbt_B_RqDsply 1;
BA_ "U_V710_MY2023_Rx" SG_ 1054 BrkMdeInhbt_B_RqDsply 1;
BA_ "U_P702_MY2024_Rx" SG_ 1054 BrkMdeInhbt_B_RqDsply 1;
BA_ "GenSigStartValue" SG_ 1054 BrkLineLck_D_Stat 4;
BA_ "U_V713N_MY2022_Rx" SG_ 1054 BrkLineLck_D_Stat 1;
BA_ "U_V713AV_MY2022_Rx" SG_ 1054 BrkLineLck_D_Stat 1;
BA_ "U_P708_MY2023_Rx" SG_ 1054 BrkLineLck_D_Stat 1;
BA_ "U_V710_MY2023_Rx" SG_ 1054 BrkLineLck_D_Stat 1;
BA_ "U_P702_MY2024_Rx" SG_ 1054 BrkLineLck_D_Stat 1;
BA_ "U_V713N_MY2022_Rx" SG_ 1054 BrkDrvMde_D_Stat 1;
BA_ "U_P708_MY2023_Rx" SG_ 1054 BrkDrvMde_D_Stat 1;
BA_ "U_V713AV_MY2022_Rx" SG_ 1054 BrkDrvMde_D_Stat 1;
BA_ "GenSigStartValue" SG_ 572 BattTracClnt_Te_Actl 254;
BA_ "GenSigStartValue" SG_ 572 BattTracClnt_Te_Rq 190;
BA_ "U_V713N_MY2022_Rx" SG_ 572 BattTracWarnLamp_B_Rq 1;
BA_ "U_P708_MY2023_Rx" SG_ 572 BattTracWarnLamp_B_Rq 1;
BA_ "U_V710_MY2023_Rx" SG_ 572 BattTracWarnLamp_B_Rq 1;
BA_ "U_V713AV_MY2022_Rx" SG_ 572 BattTracWarnLamp_B_Rq 1;
BA_ "U_P702_MY2024_Rx" SG_ 572 BattTracWarnLamp_B_Rq 1;
BA_ "U_V713N_MY2022_Rx" SG_ 572 BattTracSrvcRqd_B_Rq 1;
BA_ "U_P708_MY2023_Rx" SG_ 572 BattTracSrvcRqd_B_Rq 1;
BA_ "U_V710_MY2023_Rx" SG_ 572 BattTracSrvcRqd_B_Rq 1;
BA_ "U_V713AV_MY2022_Rx" SG_ 572 BattTracSrvcRqd_B_Rq 1;
BA_ "U_P702_MY2024_Rx" SG_ 572 BattTracSrvcRqd_B_Rq 1;
BA_ "GenSigStartValue" SG_ 572 BattTracSoc_Pc_MxPrtct 700;
BA_ "U_P702_MY2024_Rx" SG_ 572 BattTracSoc_Pc_MxPrtct 1;
BA_ "GenSigStartValue" SG_ 572 BattTracSoc_Pc_MnPrtct 30;
BA_ "GenSigStartValue" SG_ 572 BattTracSoc_Pc_LimLo 400;
BA_ "GenSigStartValue" SG_ 572 BattTracSoc_Pc_LimHi 600;
BA_ "U_V713N_MY2022_Rx" SG_ 561 TrnMsgTxt2_D_Rq 1;
BA_ "U_V713AV_MY2022_Rx" SG_ 561 TrnMsgTxt2_D_Rq 1;
BA_ "U_P708_MY2023_Rx" SG_ 561 TrnMsgTxt2_D_Rq 1;
BA_ "U_V710_MY2023_Rx" SG_ 561 TrnMsgTxt2_D_Rq 1;
BA_ "U_P702_MY2024_Rx" SG_ 561 TrnMsgTxt2_D_Rq 1;
BA_ "U_V713N_MY2022_Rx" SG_ 561 TrnMsgTxt_D_Rq 1;
BA_ "U_P708_MY2023_Rx" SG_ 561 TrnMsgTxt_D_Rq 1;
BA_ "U_V710_MY2023_Rx" SG_ 561 TrnMsgTxt_D_Rq 1;
BA_ "U_V713AV_MY2022_Rx" SG_ 561 TrnMsgTxt_D_Rq 1;
BA_ "U_P702_MY2024_Rx" SG_ 561 TrnMsgTxt_D_Rq 1;
BA_ "U_V713N_MY2022_Rx" SG_ 602 HtrnWarnLamp_B_Dsply 1;
BA_ "U_V710_MY2023_Rx" SG_ 602 HtrnWarnLamp_B_Dsply 1;
BA_ "U_V713AV_MY2022_Rx" SG_ 602 HtrnWarnLamp_B_Dsply 1;
BA_ "U_P708_MY2023_Rx" SG_ 602 HtrnWarnLamp_B_Dsply 1;
BA_ "U_P702_MY2024_Rx" SG_ 602 HtrnWarnLamp_B_Dsply 1;
BA_ "U_V713N_MY2022_Rx" SG_ 602 PwPckTqRdy_B_Dsply 1;
BA_ "U_V710_MY2023_Rx" SG_ 602 PwPckTqRdy_B_Dsply 1;
BA_ "U_V713AV_MY2022_Rx" SG_ 602 PwPckTqRdy_B_Dsply 1;
BA_ "U_P708_MY2023_Rx" SG_ 602 PwPckTqRdy_B_Dsply 1;
BA_ "U_P702_MY2024_Rx" SG_ 602 PwPckTqRdy_B_Dsply 1;
BA_ "GenSigStartValue" SG_ 602 BattTracRsrvSoc_Pc_Rq 16382;
BA_ "ContentDependant" SG_ 92 TrnGearMsgTxt2_D_Rq 1;
BA_ "U_P708_MY2023_Rx" SG_ 92 TrnGearMsgTxt2_D_Rq 1;
BA_ "U_V710_MY2023_Rx" SG_ 92 TrnGearMsgTxt2_D_Rq 1;
BA_ "U_P702_MY2024_Rx" SG_ 92 TrnGearMsgTxt2_D_Rq 1;
BA_ "GenSigStartValue" SG_ 92 TrnLvrV_D_Rq 1;
BA_ "GenSigStartValue" SG_ 92 TrnSbwSysHlth_D_Actl 1;
BA_ "WakeupSignal" SG_ 92 TrnDtpCmd_D_Actl 1;
BA_ "GenSigStartValue" SG_ 92 TrnDtpCmd_D_Actl 1;
BA_ "U_V713N_MY2022_Rx" SG_ 92 TrnGearNtmAllow_B_Stat 1;
BA_ "U_P708_MY2023_Rx" SG_ 92 TrnGearNtmAllow_B_Stat 1;
BA_ "U_V710_MY2023_Rx" SG_ 92 TrnGearNtmAllow_B_Stat 1;
BA_ "U_V713AV_MY2022_Rx" SG_ 92 TrnGearNtmAllow_B_Stat 1;
BA_ "U_P702_MY2024_Rx" SG_ 92 TrnGearNtmAllow_B_Stat 1;
BA_ "MetaData" SG_ 92 TrnGearCmd_No_Cs 1;
BA_ "GenSigStartValue" SG_ 92 PrkBrkActv_D_RqTrnGear 1;
BA_ "U_V713N_MY2022_Rx" SG_ 92 TrnGearMsgTxt_D_Rq 1;
BA_ "U_P708_MY2023_Rx" SG_ 92 TrnGearMsgTxt_D_Rq 1;
BA_ "U_V710_MY2023_Rx" SG_ 92 TrnGearMsgTxt_D_Rq 1;
BA_ "U_V713AV_MY2022_Rx" SG_ 92 TrnGearMsgTxt_D_Rq 1;
BA_ "U_P702_MY2024_Rx" SG_ 92 TrnGearMsgTxt_D_Rq 1;
BA_ "MetaData" SG_ 92 TrnGearCmd_No_Cnt 1;
BA_ "GenSigStartValue" SG_ 1156 RngPerChrgAvg_L2_Dsply 8190;
BA_ "U_V713AV_MY2022_Rx" SG_ 1156 RngPerChrgAvg_L2_Dsply 1;
BA_ "U_P708_MY2023_Rx" SG_ 1156 RngPerChrgAvg_L2_Dsply 1;
BA_ "U_V710_MY2023_Rx" SG_ 1156 RngPerChrgAvg_L2_Dsply 1;
BA_ "U_P702_MY2024_Rx" SG_ 1156 RngPerChrgAvg_L2_Dsply 1;
BA_ "U_V713AV_MY2022_Rx" SG_ 1156 RngImpctDrv_L_Dsply 1;
BA_ "U_P708_MY2023_Rx" SG_ 1156 RngImpctDrv_L_Dsply 1;
BA_ "U_V710_MY2023_Rx" SG_ 1156 RngImpctDrv_L_Dsply 1;
BA_ "U_V713N_MY2022_Rx" SG_ 1156 RngImpctDrv_L_Dsply 1;
BA_ "U_P702_MY2024_Rx" SG_ 1156 RngImpctDrv_L_Dsply 1;
BA_ "U_V713AV_MY2022_Rx" SG_ 1156 RngImpctClim_L_Dsply 1;
BA_ "U_P708_MY2023_Rx" SG_ 1156 RngImpctClim_L_Dsply 1;
BA_ "U_V710_MY2023_Rx" SG_ 1156 RngImpctClim_L_Dsply 1;
BA_ "U_V713N_MY2022_Rx" SG_ 1156 RngImpctClim_L_Dsply 1;
BA_ "U_P702_MY2024_Rx" SG_ 1156 RngImpctClim_L_Dsply 1;
BA_ "GenSigStartValue" SG_ 1156 VehElEffAvg_No_Dsply 126;
BA_ "U_V713N_MY2022_Rx" SG_ 1156 VehElEffAvg_No_Dsply 1;
BA_ "U_V710_MY2023_Rx" SG_ 1156 VehElEffAvg_No_Dsply 1;
BA_ "U_P708_MY2023_Rx" SG_ 1156 VehElEffAvg_No_Dsply 1;
BA_ "U_P702_MY2024_Rx" SG_ 1156 VehElEffAvg_No_Dsply 1;
BA_ "U_P708_MY2023_Rx" SG_ 1156 PwFlwFuelDrv_D_Dsply 1;
BA_ "U_V710_MY2023_Rx" SG_ 1156 PwFlwFuelDrv_D_Dsply 1;
BA_ "U_P702_MY2024_Rx" SG_ 1156 PwFlwFuelDrv_D_Dsply 1;
BA_ "U_P708_MY2023_Rx" SG_ 1156 PwFlwFuelClimt_B_Dsply 1;
BA_ "U_V710_MY2023_Rx" SG_ 1156 PwFlwFuelClimt_B_Dsply 1;
BA_ "U_P702_MY2024_Rx" SG_ 1156 PwFlwFuelClimt_B_Dsply 1;
BA_ "U_P708_MY2023_Rx" SG_ 1156 PwFlwFuelBatt_B_Dsply 1;
BA_ "U_V710_MY2023_Rx" SG_ 1156 PwFlwFuelBatt_B_Dsply 1;
BA_ "U_P702_MY2024_Rx" SG_ 1156 PwFlwFuelBatt_B_Dsply 1;
BA_ "U_P708_MY2023_Rx" SG_ 1156 PwFlwBattGen_D_Dsply 1;
BA_ "U_V710_MY2023_Rx" SG_ 1156 PwFlwBattGen_D_Dsply 1;
BA_ "U_P702_MY2024_Rx" SG_ 1156 PwFlwBattGen_D_Dsply 1;
BA_ "U_P708_MY2023_Rx" SG_ 1156 PwFlwBattClimt_B_Dsply 1;
BA_ "U_V710_MY2023_Rx" SG_ 1156 PwFlwBattClimt_B_Dsply 1;
BA_ "U_P702_MY2024_Rx" SG_ 1156 PwFlwBattClimt_B_Dsply 1;
BA_ "U_P708_MY2023_Rx" SG_ 1156 PwFlwBatt_D_Dsply 1;
BA_ "U_V710_MY2023_Rx" SG_ 1156 PwFlwBatt_D_Dsply 1;
BA_ "U_P702_MY2024_Rx" SG_ 1156 PwFlwBatt_D_Dsply 1;
BA_ "MetaData" SG_ 357 BPedDrvAppl_D_Qf 1;
BA_ "GenSigStartValue" SG_ 357 BPedDrvAppl_D_Qf 1;
BA_ "MetaData" SG_ 357 BpedDrvAppl_No_Cs 1;
BA_ "MetaData" SG_ 357 BpedDrvAppl_No_Cnt 1;
BA_ "GenSigStartValue" SG_ 357 BpedDrvAppl_D_Actl 1;
BA_ "U_V713N_MY2022_Rx" SG_ 357 BpedDrvAppl_D_Actl 1;
BA_ "U_P708_MY2023_Rx" SG_ 357 BpedDrvAppl_D_Actl 1;
BA_ "U_V713AV_MY2022_Rx" SG_ 357 BpedDrvAppl_D_Actl 1;
BA_ "U_V710_MY2023_Rx" SG_ 357 BpedDrvAppl_D_Actl 1;
BA_ "U_P702_MY2024_Rx" SG_ 357 BpedDrvAppl_D_Actl 1;
BA_ "U_V713N_MY2022_Rx" SG_ 357 Veh_V_DsplyCcSet 1;
BA_ "U_P708_MY2023_Rx" SG_ 357 Veh_V_DsplyCcSet 1;
BA_ "U_V710_MY2023_Rx" SG_ 357 Veh_V_DsplyCcSet 1;
BA_ "U_P702_MY2024_Rx" SG_ 357 Veh_V_DsplyCcSet 1;
BA_ "U_V713AV_MY2022_Rx" SG_ 357 Veh_V_DsplyCcSet 1;
BA_ "U_V713N_MY2022_Rx" SG_ 357 CcStat_D_Actl 1;
BA_ "U_P708_MY2023_Rx" SG_ 357 CcStat_D_Actl 1;
BA_ "U_P702_MY2024_Rx" SG_ 357 CcStat_D_Actl 1;
BA_ "U_V713AV_MY2022_Rx" SG_ 357 CcStat_D_Actl 1;
BA_ "U_V710_MY2023_Rx" SG_ 357 CcStat_D_Actl 1;
BA_ "U_V713N_MY2022_Rx" SG_ 357 CcOvrrdActv_B_Actl 1;
BA_ "U_P708_MY2023_Rx" SG_ 357 CcOvrrdActv_B_Actl 1;
BA_ "U_P702_MY2024_Rx" SG_ 357 CcOvrrdActv_B_Actl 1;
BA_ "U_V713AV_MY2022_Rx" SG_ 357 CcOvrrdActv_B_Actl 1;
BA_ "U_V710_MY2023_Rx" SG_ 357 CcOvrrdActv_B_Actl 1;
BA_ "U_V713N_MY2022_Rx" SG_ 1100 RearDiffLckLamp_D_Rq2 1;
BA_ "U_P708_MY2023_Rx" SG_ 1100 RearDiffLckLamp_D_Rq2 1;
BA_ "U_V713AV_MY2022_Rx" SG_ 1100 RearDiffLckLamp_D_Rq2 1;
BA_ "U_V710_MY2023_Rx" SG_ 1100 RearDiffLckLamp_D_Rq2 1;
BA_ "U_P702_MY2024_Rx" SG_ 1100 RearDiffLckLamp_D_Rq2 1;
BA_ "U_V713AV_MY2022_Rx" SG_ 1100 RvltnMatchAllw_D_Stat 1;
BA_ "U_P708_MY2023_Rx" SG_ 1100 RvltnMatchAllw_D_Stat 1;
BA_ "U_V710_MY2023_Rx" SG_ 1100 RvltnMatchAllw_D_Stat 1;
BA_ "U_V713N_MY2022_Rx" SG_ 1100 RvltnMatchAllw_D_Stat 1;
BA_ "U_P702_MY2024_Rx" SG_ 1100 RvltnMatchAllw_D_Stat 1;
BA_ "GenSigStartValue" SG_ 1100 WakeAlarm1_T_Rq 32767;
BA_ "WakeupSignal" SG_ 1100 WakeAlarm1_B_Typ 1;
BA_ "U_V713AV_MY2022_Rx" SG_ 1100 Veh_V_DsplyTrailCtlSet 1;
BA_ "U_P708_MY2023_Rx" SG_ 1100 Veh_V_DsplyTrailCtlSet 1;
BA_ "U_V710_MY2023_Rx" SG_ 1100 Veh_V_DsplyTrailCtlSet 1;
BA_ "U_P702_MY2024_Rx" SG_ 1100 Veh_V_DsplyTrailCtlSet 1;
BA_ "U_V713N_MY2022_Rx" SG_ 1100 AutoTowAllw_D_StatMnu 1;
BA_ "U_P708_MY2023_Rx" SG_ 1100 AutoTowAllw_D_StatMnu 1;
BA_ "U_V713AV_MY2022_Rx" SG_ 1100 AutoTowAllw_D_StatMnu 1;
BA_ "U_V710_MY2023_Rx" SG_ 1100 AutoTowAllw_D_StatMnu 1;
BA_ "U_P702_MY2024_Rx" SG_ 1100 AutoTowAllw_D_StatMnu 1;
BA_ "U_V713N_MY2022_Rx" SG_ 1100 AutoTowActv_B_Stat 1;
BA_ "U_P708_MY2023_Rx" SG_ 1100 AutoTowActv_B_Stat 1;
BA_ "U_V710_MY2023_Rx" SG_ 1100 AutoTowActv_B_Stat 1;
BA_ "U_P702_MY2024_Rx" SG_ 1100 AutoTowActv_B_Stat 1;
BA_ "GenSigStartValue" SG_ 1100 RearDiffSumpOil_Te_Est 254;
BA_ "GenSigStartValue" SG_ 1100 GrossTrainWeight_M_Est 254;
BA_ "U_V713N_MY2022_Rx" SG_ 1100 SuspVlimMsgTxt_B_Rq 1;
BA_ "U_P708_MY2023_Rx" SG_ 1100 SuspVlimMsgTxt_B_Rq 1;
BA_ "U_V713AV_MY2022_Rx" SG_ 1100 SuspVlimMsgTxt_B_Rq 1;
BA_ "U_V710_MY2023_Rx" SG_ 1100 SuspVlimMsgTxt_B_Rq 1;
BA_ "U_P702_MY2024_Rx" SG_ 1100 SuspVlimMsgTxt_B_Rq 1;
BA_ "U_V713N_MY2022_Rx" SG_ 1100 RearDiffLckMsg2_D_Rq 1;
BA_ "U_P708_MY2023_Rx" SG_ 1100 RearDiffLckMsg2_D_Rq 1;
BA_ "U_V713AV_MY2022_Rx" SG_ 1100 RearDiffLckMsg2_D_Rq 1;
BA_ "U_V710_MY2023_Rx" SG_ 1100 RearDiffLckMsg2_D_Rq 1;
BA_ "U_P702_MY2024_Rx" SG_ 1100 RearDiffLckMsg2_D_Rq 1;
BA_ "U_V713N_MY2022_Rx" SG_ 1100 EngExhMdeQuiet_D2_Stat 1;
BA_ "U_P708_MY2023_Rx" SG_ 1100 EngExhMdeQuiet_D2_Stat 1;
BA_ "U_V713AV_MY2022_Rx" SG_ 1100 EngExhMdeQuiet_D2_Stat 1;
BA_ "U_V710_MY2023_Rx" SG_ 1100 EngExhMdeQuiet_D2_Stat 1;
BA_ "U_P702_MY2024_Rx" SG_ 1100 EngExhMdeQuiet_D2_Stat 1;
BA_ "GenSigStartValue" SG_ 1152 StopStrtVThres_D_Stat 1;
BA_ "U_V713N_MY2022_Rx" SG_ 1152 StopStrtVThres_D_Stat 1;
BA_ "U_V710_MY2023_Rx" SG_ 1152 StopStrtVThres_D_Stat 1;
BA_ "U_V713AV_MY2022_Rx" SG_ 1152 StopStrtVThres_D_Stat 1;
BA_ "U_P708_MY2023_Rx" SG_ 1152 StopStrtVThres_D_Stat 1;
BA_ "U_P702_MY2024_Rx" SG_ 1152 StopStrtVThres_D_Stat 1;
BA_ "U_V713AV_MY2022_Rx" SG_ 1152 GrdAsstActv_B_Stat 1;
BA_ "U_P708_MY2023_Rx" SG_ 1152 GrdAsstActv_B_Stat 1;
BA_ "U_V710_MY2023_Rx" SG_ 1152 GrdAsstActv_B_Stat 1;
BA_ "U_V713N_MY2022_Rx" SG_ 1152 GrdAsstActv_B_Stat 1;
BA_ "U_P702_MY2024_Rx" SG_ 1152 GrdAsstActv_B_Stat 1;
BA_ "U_V713AV_MY2022_Rx" SG_ 1152 OnePdlDrv_D_Dsply 1;
BA_ "U_P708_MY2023_Rx" SG_ 1152 OnePdlDrv_D_Dsply 1;
BA_ "U_V710_MY2023_Rx" SG_ 1152 OnePdlDrv_D_Dsply 1;
BA_ "U_V713N_MY2022_Rx" SG_ 1152 OnePdlDrv_D_Dsply 1;
BA_ "U_P702_MY2024_Rx" SG_ 1152 OnePdlDrv_D_Dsply 1;
BA_ "U_V713AV_MY2022_Rx" SG_ 1152 OnePdlDrvLamp_B_Rq 1;
BA_ "U_P708_MY2023_Rx" SG_ 1152 OnePdlDrvLamp_B_Rq 1;
BA_ "U_V710_MY2023_Rx" SG_ 1152 OnePdlDrvLamp_B_Rq 1;
BA_ "U_V713N_MY2022_Rx" SG_ 1152 OnePdlDrvLamp_B_Rq 1;
BA_ "U_P702_MY2024_Rx" SG_ 1152 OnePdlDrvLamp_B_Rq 1;
BA_ "GenSigStartValue" SG_ 1152 VehElEff_No_Avg 126;
BA_ "WakeupSignal" SG_ 839 FohStop_B_Stat 1;
BA_ "GenSigStartValue" SG_ 839 FohStop_B_Stat 3;
BA_ "U_V713AV_MY2022_Rx" SG_ 839 FohStop_B_Stat 1;
BA_ "U_P708_MY2023_Rx" SG_ 839 FohStop_B_Stat 1;
BA_ "U_V710_MY2023_Rx" SG_ 839 FohStop_B_Stat 1;
BA_ "U_P702_MY2024_Rx" SG_ 839 FohStop_B_Stat 1;
BA_ "U_V713AV_MY2022_Rx" SG_ 839 FohMsgTxt_D_Rq 1;
BA_ "U_P708_MY2023_Rx" SG_ 839 FohMsgTxt_D_Rq 1;
BA_ "U_V710_MY2023_Rx" SG_ 839 FohMsgTxt_D_Rq 1;
BA_ "U_P702_MY2024_Rx" SG_ 839 FohMsgTxt_D_Rq 1;
BA_ "WakeupSignal" SG_ 839 FohKeyOff_B_Rq 1;
BA_ "U_V713AV_MY2022_Rx" SG_ 839 FohKeyOff_B_Rq 1;
BA_ "U_P708_MY2023_Rx" SG_ 839 FohKeyOff_B_Rq 1;
BA_ "U_V710_MY2023_Rx" SG_ 839 FohKeyOff_B_Rq 1;
BA_ "U_P702_MY2024_Rx" SG_ 839 FohKeyOff_B_Rq 1;
BA_ "WakeupSignal" SG_ 839 FohEnbl_B_Rq 1;
BA_ "U_V713AV_MY2022_Rx" SG_ 839 FohEnbl_B_Rq 1;
BA_ "U_P708_MY2023_Rx" SG_ 839 FohEnbl_B_Rq 1;
BA_ "U_V710_MY2023_Rx" SG_ 839 FohEnbl_B_Rq 1;
BA_ "U_P702_MY2024_Rx" SG_ 839 FohEnbl_B_Rq 1;
BA_ "GenSigStartValue" SG_ 839 FohTAllEnable_B_Stat 3;
BA_ "U_V713AV_MY2022_Rx" SG_ 839 FohTAllEnable_B_Stat 1;
BA_ "U_P708_MY2023_Rx" SG_ 839 FohTAllEnable_B_Stat 1;
BA_ "U_V710_MY2023_Rx" SG_ 839 FohTAllEnable_B_Stat 1;
BA_ "U_P702_MY2024_Rx" SG_ 839 FohTAllEnable_B_Stat 1;
BA_ "U_V713AV_MY2022_Rx" SG_ 839 FohT2Mnte_T_Stat 1;
BA_ "U_P708_MY2023_Rx" SG_ 839 FohT2Mnte_T_Stat 1;
BA_ "U_V710_MY2023_Rx" SG_ 839 FohT2Mnte_T_Stat 1;
BA_ "U_P702_MY2024_Rx" SG_ 839 FohT2Mnte_T_Stat 1;
BA_ "U_V713AV_MY2022_Rx" SG_ 839 FohT2Hr_T_Stat 1;
BA_ "U_P708_MY2023_Rx" SG_ 839 FohT2Hr_T_Stat 1;
BA_ "U_V710_MY2023_Rx" SG_ 839 FohT2Hr_T_Stat 1;
BA_ "U_P702_MY2024_Rx" SG_ 839 FohT2Hr_T_Stat 1;
BA_ "U_V713AV_MY2022_Rx" SG_ 839 FohT2Enable_B_Stat 1;
BA_ "U_P708_MY2023_Rx" SG_ 839 FohT2Enable_B_Stat 1;
BA_ "U_V710_MY2023_Rx" SG_ 839 FohT2Enable_B_Stat 1;
BA_ "U_P702_MY2024_Rx" SG_ 839 FohT2Enable_B_Stat 1;
BA_ "U_V713AV_MY2022_Rx" SG_ 839 FohT1Mnte_T_Stat 1;
BA_ "U_P708_MY2023_Rx" SG_ 839 FohT1Mnte_T_Stat 1;
BA_ "U_V710_MY2023_Rx" SG_ 839 FohT1Mnte_T_Stat 1;
BA_ "U_P702_MY2024_Rx" SG_ 839 FohT1Mnte_T_Stat 1;
BA_ "U_V713AV_MY2022_Rx" SG_ 839 FohT1Hr_T_Stat 1;
BA_ "U_P708_MY2023_Rx" SG_ 839 FohT1Hr_T_Stat 1;
BA_ "U_V710_MY2023_Rx" SG_ 839 FohT1Hr_T_Stat 1;
BA_ "U_P702_MY2024_Rx" SG_ 839 FohT1Hr_T_Stat 1;
BA_ "U_V713AV_MY2022_Rx" SG_ 839 FohT1Enable_B_Stat 1;
BA_ "U_P708_MY2023_Rx" SG_ 839 FohT1Enable_B_Stat 1;
BA_ "U_V710_MY2023_Rx" SG_ 839 FohT1Enable_B_Stat 1;
BA_ "U_P702_MY2024_Rx" SG_ 839 FohT1Enable_B_Stat 1;
BA_ "U_V713AV_MY2022_Rx" SG_ 839 FohStrtMnte_T_Stat 1;
BA_ "U_P708_MY2023_Rx" SG_ 839 FohStrtMnte_T_Stat 1;
BA_ "U_V710_MY2023_Rx" SG_ 839 FohStrtMnte_T_Stat 1;
BA_ "U_P702_MY2024_Rx" SG_ 839 FohStrtMnte_T_Stat 1;
BA_ "U_V713AV_MY2022_Rx" SG_ 839 FohStrtHr_T_Stat 1;
BA_ "U_P708_MY2023_Rx" SG_ 839 FohStrtHr_T_Stat 1;
BA_ "U_V710_MY2023_Rx" SG_ 839 FohStrtHr_T_Stat 1;
BA_ "U_P702_MY2024_Rx" SG_ 839 FohStrtHr_T_Stat 1;
BA_ "U_V713AV_MY2022_Rx" SG_ 839 FohStrtEnable_B_Stat 1;
BA_ "U_P708_MY2023_Rx" SG_ 839 FohStrtEnable_B_Stat 1;
BA_ "U_V710_MY2023_Rx" SG_ 839 FohStrtEnable_B_Stat 1;
BA_ "U_P702_MY2024_Rx" SG_ 839 FohStrtEnable_B_Stat 1;
BA_ "GenSigStartValue" SG_ 839 FohContOn_B_Stat 3;
BA_ "U_V713AV_MY2022_Rx" SG_ 839 FohContOn_B_Stat 1;
BA_ "U_P708_MY2023_Rx" SG_ 839 FohContOn_B_Stat 1;
BA_ "U_V710_MY2023_Rx" SG_ 839 FohContOn_B_Stat 1;
BA_ "U_P702_MY2024_Rx" SG_ 839 FohContOn_B_Stat 1;
BA_ "U_V713AV_MY2022_Rx" SG_ 839 FohStrtDay_T_Stat 1;
BA_ "U_P708_MY2023_Rx" SG_ 839 FohStrtDay_T_Stat 1;
BA_ "U_V710_MY2023_Rx" SG_ 839 FohStrtDay_T_Stat 1;
BA_ "U_P702_MY2024_Rx" SG_ 839 FohStrtDay_T_Stat 1;
BA_ "U_V713AV_MY2022_Rx" SG_ 839 FohT2Wednesday_T_Stat 1;
BA_ "U_P708_MY2023_Rx" SG_ 839 FohT2Wednesday_T_Stat 1;
BA_ "U_V710_MY2023_Rx" SG_ 839 FohT2Wednesday_T_Stat 1;
BA_ "U_P702_MY2024_Rx" SG_ 839 FohT2Wednesday_T_Stat 1;
BA_ "U_V713AV_MY2022_Rx" SG_ 839 FohT2Tuesday_T_Stat 1;
BA_ "U_P708_MY2023_Rx" SG_ 839 FohT2Tuesday_T_Stat 1;
BA_ "U_V710_MY2023_Rx" SG_ 839 FohT2Tuesday_T_Stat 1;
BA_ "U_P702_MY2024_Rx" SG_ 839 FohT2Tuesday_T_Stat 1;
BA_ "U_V713AV_MY2022_Rx" SG_ 839 FohT2Thursday_T_Stat 1;
BA_ "U_P708_MY2023_Rx" SG_ 839 FohT2Thursday_T_Stat 1;
BA_ "U_V710_MY2023_Rx" SG_ 839 FohT2Thursday_T_Stat 1;
BA_ "U_P702_MY2024_Rx" SG_ 839 FohT2Thursday_T_Stat 1;
BA_ "U_V713AV_MY2022_Rx" SG_ 839 FohT2Sunday_T_Stat 1;
BA_ "U_P708_MY2023_Rx" SG_ 839 FohT2Sunday_T_Stat 1;
BA_ "U_V710_MY2023_Rx" SG_ 839 FohT2Sunday_T_Stat 1;
BA_ "U_P702_MY2024_Rx" SG_ 839 FohT2Sunday_T_Stat 1;
BA_ "U_V713AV_MY2022_Rx" SG_ 839 FohT2Saturday_T_Stat 1;
BA_ "U_P708_MY2023_Rx" SG_ 839 FohT2Saturday_T_Stat 1;
BA_ "U_V710_MY2023_Rx" SG_ 839 FohT2Saturday_T_Stat 1;
BA_ "U_P702_MY2024_Rx" SG_ 839 FohT2Saturday_T_Stat 1;
BA_ "U_V713AV_MY2022_Rx" SG_ 839 FohT2Monday_T_Stat 1;
BA_ "U_P708_MY2023_Rx" SG_ 839 FohT2Monday_T_Stat 1;
BA_ "U_V710_MY2023_Rx" SG_ 839 FohT2Monday_T_Stat 1;
BA_ "U_P702_MY2024_Rx" SG_ 839 FohT2Monday_T_Stat 1;
BA_ "U_V713AV_MY2022_Rx" SG_ 839 FohT2Friday_T_Stat 1;
BA_ "U_P708_MY2023_Rx" SG_ 839 FohT2Friday_T_Stat 1;
BA_ "U_V710_MY2023_Rx" SG_ 839 FohT2Friday_T_Stat 1;
BA_ "U_P702_MY2024_Rx" SG_ 839 FohT2Friday_T_Stat 1;
BA_ "U_V713AV_MY2022_Rx" SG_ 839 FohT1Wednesday_T_Stat 1;
BA_ "U_P708_MY2023_Rx" SG_ 839 FohT1Wednesday_T_Stat 1;
BA_ "U_V710_MY2023_Rx" SG_ 839 FohT1Wednesday_T_Stat 1;
BA_ "U_P702_MY2024_Rx" SG_ 839 FohT1Wednesday_T_Stat 1;
BA_ "U_V713AV_MY2022_Rx" SG_ 839 FohT1Tuesday_T_Stat 1;
BA_ "U_P708_MY2023_Rx" SG_ 839 FohT1Tuesday_T_Stat 1;
BA_ "U_V710_MY2023_Rx" SG_ 839 FohT1Tuesday_T_Stat 1;
BA_ "U_P702_MY2024_Rx" SG_ 839 FohT1Tuesday_T_Stat 1;
BA_ "U_V713AV_MY2022_Rx" SG_ 839 FohT1Thursday_T_Stat 1;
BA_ "U_P708_MY2023_Rx" SG_ 839 FohT1Thursday_T_Stat 1;
BA_ "U_V710_MY2023_Rx" SG_ 839 FohT1Thursday_T_Stat 1;
BA_ "U_P702_MY2024_Rx" SG_ 839 FohT1Thursday_T_Stat 1;
BA_ "U_V713AV_MY2022_Rx" SG_ 839 FohT1Sunday_T_Stat 1;
BA_ "U_P708_MY2023_Rx" SG_ 839 FohT1Sunday_T_Stat 1;
BA_ "U_V710_MY2023_Rx" SG_ 839 FohT1Sunday_T_Stat 1;
BA_ "U_P702_MY2024_Rx" SG_ 839 FohT1Sunday_T_Stat 1;
BA_ "U_V713AV_MY2022_Rx" SG_ 839 FohT1Saturday_T_Stat 1;
BA_ "U_P708_MY2023_Rx" SG_ 839 FohT1Saturday_T_Stat 1;
BA_ "U_V710_MY2023_Rx" SG_ 839 FohT1Saturday_T_Stat 1;
BA_ "U_P702_MY2024_Rx" SG_ 839 FohT1Saturday_T_Stat 1;
BA_ "U_V713AV_MY2022_Rx" SG_ 839 FohT1Monday_T_Stat 1;
BA_ "U_P708_MY2023_Rx" SG_ 839 FohT1Monday_T_Stat 1;
BA_ "U_V710_MY2023_Rx" SG_ 839 FohT1Monday_T_Stat 1;
BA_ "U_P702_MY2024_Rx" SG_ 839 FohT1Monday_T_Stat 1;
BA_ "U_V713AV_MY2022_Rx" SG_ 839 FohT1Friday_T_Stat 1;
BA_ "U_P708_MY2023_Rx" SG_ 839 FohT1Friday_T_Stat 1;
BA_ "U_V710_MY2023_Rx" SG_ 839 FohT1Friday_T_Stat 1;
BA_ "U_P702_MY2024_Rx" SG_ 839 FohT1Friday_T_Stat 1;
BA_ "GenSigSendType" SG_ 2612224064 PARSEDPushWCMtoGWM_ECG 3;
BA_ "ECGUsedRxSignal" SG_ 2612224064 PARSEDPushWCMtoGWM_ECG 1;
BA_ "U_V713N_MY2022_Rx" SG_ 2612224064 PARSEDPushWCMtoGWM_ECG 1;
BA_ "U_V713AV_MY2022_Rx" SG_ 2612224064 PARSEDPushWCMtoGWM_ECG 1;
BA_ "U_P708_MY2023_Rx" SG_ 2612224064 PARSEDPushWCMtoGWM_ECG 1;
BA_ "U_CDX74X_MY2024_Rx" SG_ 2612224064 PARSEDPushWCMtoGWM_ECG 1;
BA_ "U_V710_MY2023_Rx" SG_ 2612224064 PARSEDPushWCMtoGWM_ECG 1;
BA_ "U_V713N_MY2022_Tx" SG_ 2612224064 PARSEDPushWCMtoGWM_ECG 1;
BA_ "U_P708_MY2023_Tx" SG_ 2612224064 PARSEDPushWCMtoGWM_ECG 1;
BA_ "U_CDX74X_MY2024_Tx" SG_ 2612224064 PARSEDPushWCMtoGWM_ECG 1;
BA_ "U_V710_MY2023_Tx" SG_ 2612224064 PARSEDPushWCMtoGWM_ECG 1;
BA_ "U_P702_MY2024_Tx" SG_ 2612224064 PARSEDPushWCMtoGWM_ECG 1;
BA_ "GenSigSendType" SG_ 2612068568 PARSEDPushFcGWM_ECGtoWCM 3;
BA_ "U_P708_MY2023_Rx" SG_ 2612068568 PARSEDPushFcGWM_ECGtoWCM 1;
BA_ "U_CDX74X_MY2024_Rx" SG_ 2612068568 PARSEDPushFcGWM_ECGtoWCM 1;
BA_ "U_V710_MY2023_Rx" SG_ 2612068568 PARSEDPushFcGWM_ECGtoWCM 1;
BA_ "U_P702_MY2024_Rx" SG_ 2612068568 PARSEDPushFcGWM_ECGtoWCM 1;
BA_ "ECGUsedTxSignal" SG_ 2612068568 PARSEDPushFcGWM_ECGtoWCM 1;
BA_ "U_V713N_MY2022_Tx" SG_ 2612068568 PARSEDPushFcGWM_ECGtoWCM 1;
BA_ "U_V713AV_MY2022_Tx" SG_ 2612068568 PARSEDPushFcGWM_ECGtoWCM 1;
BA_ "U_P708_MY2023_Tx" SG_ 2612068568 PARSEDPushFcGWM_ECGtoWCM 1;
BA_ "U_CDX74X_MY2024_Tx" SG_ 2612068568 PARSEDPushFcGWM_ECGtoWCM 1;
BA_ "U_V710_MY2023_Tx" SG_ 2612068568 PARSEDPushFcGWM_ECGtoWCM 1;
BA_ "GenSigSendType" SG_ 2611175488 PARSEDPhysWCMtoGWM_ECG 3;
BA_ "ECGUsedRxSignal" SG_ 2611175488 PARSEDPhysWCMtoGWM_ECG 1;
BA_ "U_V713N_MY2022_Rx" SG_ 2611175488 PARSEDPhysWCMtoGWM_ECG 1;
BA_ "U_V713AV_MY2022_Rx" SG_ 2611175488 PARSEDPhysWCMtoGWM_ECG 1;
BA_ "U_P708_MY2023_Rx" SG_ 2611175488 PARSEDPhysWCMtoGWM_ECG 1;
BA_ "U_CDX74X_MY2024_Rx" SG_ 2611175488 PARSEDPhysWCMtoGWM_ECG 1;
BA_ "U_V710_MY2023_Rx" SG_ 2611175488 PARSEDPhysWCMtoGWM_ECG 1;
BA_ "U_V713N_MY2022_Tx" SG_ 2611175488 PARSEDPhysWCMtoGWM_ECG 1;
BA_ "U_P708_MY2023_Tx" SG_ 2611175488 PARSEDPhysWCMtoGWM_ECG 1;
BA_ "U_CDX74X_MY2024_Tx" SG_ 2611175488 PARSEDPhysWCMtoGWM_ECG 1;
BA_ "U_V710_MY2023_Tx" SG_ 2611175488 PARSEDPhysWCMtoGWM_ECG 1;
BA_ "U_P702_MY2024_Tx" SG_ 2611175488 PARSEDPhysWCMtoGWM_ECG 1;
BA_ "GenSigSendType" SG_ 2611019992 PARSEDPhysGWM_ECGtoWCM 3;
BA_ "U_P708_MY2023_Rx" SG_ 2611019992 PARSEDPhysGWM_ECGtoWCM 1;
BA_ "U_CDX74X_MY2024_Rx" SG_ 2611019992 PARSEDPhysGWM_ECGtoWCM 1;
BA_ "U_V710_MY2023_Rx" SG_ 2611019992 PARSEDPhysGWM_ECGtoWCM 1;
BA_ "U_P702_MY2024_Rx" SG_ 2611019992 PARSEDPhysGWM_ECGtoWCM 1;
BA_ "ECGUsedTxSignal" SG_ 2611019992 PARSEDPhysGWM_ECGtoWCM 1;
BA_ "U_V713N_MY2022_Tx" SG_ 2611019992 PARSEDPhysGWM_ECGtoWCM 1;
BA_ "U_V713AV_MY2022_Tx" SG_ 2611019992 PARSEDPhysGWM_ECGtoWCM 1;
BA_ "U_P708_MY2023_Tx" SG_ 2611019992 PARSEDPhysGWM_ECGtoWCM 1;
BA_ "U_CDX74X_MY2024_Tx" SG_ 2611019992 PARSEDPhysGWM_ECGtoWCM 1;
BA_ "U_V710_MY2023_Tx" SG_ 2611019992 PARSEDPhysGWM_ECGtoWCM 1;
BA_ "GenSigSendType" SG_ 2610126912 OTAPhysWCMtoGWM_ECG 3;
BA_ "ECGUsedRxSignal" SG_ 2610126912 OTAPhysWCMtoGWM_ECG 1;
BA_ "U_V713N_MY2022_Rx" SG_ 2610126912 OTAPhysWCMtoGWM_ECG 1;
BA_ "U_V713AV_MY2022_Rx" SG_ 2610126912 OTAPhysWCMtoGWM_ECG 1;
BA_ "U_P708_MY2023_Rx" SG_ 2610126912 OTAPhysWCMtoGWM_ECG 1;
BA_ "U_CDX74X_MY2024_Rx" SG_ 2610126912 OTAPhysWCMtoGWM_ECG 1;
BA_ "U_V710_MY2023_Rx" SG_ 2610126912 OTAPhysWCMtoGWM_ECG 1;
BA_ "U_V713N_MY2022_Tx" SG_ 2610126912 OTAPhysWCMtoGWM_ECG 1;
BA_ "U_P708_MY2023_Tx" SG_ 2610126912 OTAPhysWCMtoGWM_ECG 1;
BA_ "U_CDX74X_MY2024_Tx" SG_ 2610126912 OTAPhysWCMtoGWM_ECG 1;
BA_ "U_V710_MY2023_Tx" SG_ 2610126912 OTAPhysWCMtoGWM_ECG 1;
BA_ "U_P702_MY2024_Tx" SG_ 2610126912 OTAPhysWCMtoGWM_ECG 1;
BA_ "GenSigSendType" SG_ 2609971416 OTAPhysGWM_ECGtoWCM 3;
BA_ "U_P708_MY2023_Rx" SG_ 2609971416 OTAPhysGWM_ECGtoWCM 1;
BA_ "U_CDX74X_MY2024_Rx" SG_ 2609971416 OTAPhysGWM_ECGtoWCM 1;
BA_ "U_V710_MY2023_Rx" SG_ 2609971416 OTAPhysGWM_ECGtoWCM 1;
BA_ "U_P702_MY2024_Rx" SG_ 2609971416 OTAPhysGWM_ECGtoWCM 1;
BA_ "ECGUsedTxSignal" SG_ 2609971416 OTAPhysGWM_ECGtoWCM 1;
BA_ "U_V713N_MY2022_Tx" SG_ 2609971416 OTAPhysGWM_ECGtoWCM 1;
BA_ "U_V713AV_MY2022_Tx" SG_ 2609971416 OTAPhysGWM_ECGtoWCM 1;
BA_ "U_P708_MY2023_Tx" SG_ 2609971416 OTAPhysGWM_ECGtoWCM 1;
BA_ "U_CDX74X_MY2024_Tx" SG_ 2609971416 OTAPhysGWM_ECGtoWCM 1;
BA_ "U_V710_MY2023_Tx" SG_ 2609971416 OTAPhysGWM_ECGtoWCM 1;
BA_ "U_V713AV_MY2022_Rx" SG_ 652 TelematicsSrvc_D_St2 1;
BA_ "U_P708_MY2023_Rx" SG_ 652 TelematicsSrvc_D_St2 1;
BA_ "U_V710_MY2023_Rx" SG_ 652 TelematicsSrvc_D_St2 1;
BA_ "MetaData" SG_ 560 GearLvrPosActl_No_Cs 1;
BA_ "U_P708_MY2023_Rx" SG_ 560 GearLvrPosActl_No_Cs 1;
BA_ "U_CDX74X_MY2024_Rx" SG_ 560 GearLvrPosActl_No_Cs 1;
BA_ "U_V710_MY2023_Rx" SG_ 560 GearLvrPosActl_No_Cs 1;
BA_ "MetaData" SG_ 560 GearLvrPosActl_No_Cnt 1;
BA_ "U_P708_MY2023_Rx" SG_ 560 GearLvrPosActl_No_Cnt 1;
BA_ "U_CDX74X_MY2024_Rx" SG_ 560 GearLvrPosActl_No_Cnt 1;
BA_ "U_V710_MY2023_Rx" SG_ 560 GearLvrPosActl_No_Cnt 1;
BA_ "U_P708_MY2023_Rx" SG_ 560 TrnSrvcRqd_B_Rq 1;
BA_ "U_V710_MY2023_Rx" SG_ 560 TrnSrvcRqd_B_Rq 1;
BA_ "U_V713AV_MY2022_Rx" SG_ 560 TrnSrvcRqd_B_Rq 1;
BA_ "U_P702_MY2024_Rx" SG_ 560 TrnSrvcRqd_B_Rq 1;
BA_ "GenSigStartValue" SG_ 560 GearLvrPos_D_Actl 14;
BA_ "U_P708_MY2023_Rx" SG_ 560 GearLvrPos_D_Actl 1;
BA_ "U_V710_MY2023_Rx" SG_ 560 GearLvrPos_D_Actl 1;
BA_ "U_V713N_MY2022_Rx" SG_ 560 GearLvrPos_D_Actl 1;
BA_ "U_V713AV_MY2022_Rx" SG_ 560 GearLvrPos_D_Actl 1;
BA_ "U_CDX707_MY2023_Rx" SG_ 560 GearLvrPos_D_Actl 1;
BA_ "U_CDX74X_MY2024_Rx" SG_ 560 GearLvrPos_D_Actl 1;
BA_ "U_P702_MY2024_Rx" SG_ 560 GearLvrPos_D_Actl 1;
BA_ "GenSigStartValue" SG_ 560 GboxOil_Te_Actl 254;
BA_ "U_P708_MY2023_Rx" SG_ 560 GboxOil_Te_Actl 1;
BA_ "U_V710_MY2023_Rx" SG_ 560 GboxOil_Te_Actl 1;
BA_ "U_P702_MY2024_Rx" SG_ 560 GboxOil_Te_Actl 1;
BA_ "U_P708_MY2023_Rx" SG_ 930 BalrWndwRight_B_Stat 1;
BA_ "U_V713AV_MY2022_Rx" SG_ 930 BalrWndwRight_B_Stat 1;
BA_ "U_V710_MY2023_Rx" SG_ 930 BalrWndwRight_B_Stat 1;
BA_ "U_P702_MY2024_Rx" SG_ 930 BalrWndwRight_B_Stat 1;
BA_ "U_P708_MY2023_Rx" SG_ 930 BalrSnsRight_D_Falt 1;
BA_ "U_V713AV_MY2022_Rx" SG_ 930 BalrSnsRight_D_Falt 1;
BA_ "U_V710_MY2023_Rx" SG_ 930 BalrSnsRight_D_Falt 1;
BA_ "U_P702_MY2024_Rx" SG_ 930 BalrSnsRight_D_Falt 1;
BA_ "GenSigStartValue" SG_ 930 BalrRight_D_Stat 2;
BA_ "U_P708_MY2023_Rx" SG_ 930 BalrRight_D_Stat 1;
BA_ "U_V713AV_MY2022_Rx" SG_ 930 BalrRight_D_Stat 1;
BA_ "U_V710_MY2023_Rx" SG_ 930 BalrRight_D_Stat 1;
BA_ "U_P702_MY2024_Rx" SG_ 930 BalrRight_D_Stat 1;
BA_ "U_P708_MY2023_Rx" SG_ 930 BalrMdeSelRight_B_Stat 1;
BA_ "U_V713AV_MY2022_Rx" SG_ 930 BalrMdeSelRight_B_Stat 1;
BA_ "U_V710_MY2023_Rx" SG_ 930 BalrMdeSelRight_B_Stat 1;
BA_ "U_P702_MY2024_Rx" SG_ 930 BalrMdeSelRight_B_Stat 1;
BA_ "GenSigStartValue" SG_ 930 BalrMdeRight_D_Stat 1;
BA_ "U_P708_MY2023_Rx" SG_ 930 BalrMdeRight_D_Stat 1;
BA_ "U_V713AV_MY2022_Rx" SG_ 930 BalrMdeRight_D_Stat 1;
BA_ "U_V710_MY2023_Rx" SG_ 930 BalrMdeRight_D_Stat 1;
BA_ "U_P702_MY2024_Rx" SG_ 930 BalrMdeRight_D_Stat 1;
BA_ "U_P708_MY2023_Rx" SG_ 930 BalrLckRight_B_Stat 1;
BA_ "U_V713AV_MY2022_Rx" SG_ 930 BalrLckRight_B_Stat 1;
BA_ "U_V710_MY2023_Rx" SG_ 930 BalrLckRight_B_Stat 1;
BA_ "U_P702_MY2024_Rx" SG_ 930 BalrLckRight_B_Stat 1;
BA_ "U_P708_MY2023_Rx" SG_ 930 BalrChimeRight_D_Rq 1;
BA_ "U_V713AV_MY2022_Rx" SG_ 930 BalrChimeRight_D_Rq 1;
BA_ "U_V710_MY2023_Rx" SG_ 930 BalrChimeRight_D_Rq 1;
BA_ "U_P702_MY2024_Rx" SG_ 930 BalrChimeRight_D_Rq 1;
BA_ "U_V713N_MY2022_Rx" SG_ 930 CamraRearOn_B_RqBalrr 1;
BA_ "U_V713AV_MY2022_Rx" SG_ 930 CamraRearOn_B_RqBalrr 1;
BA_ "U_V710_MY2023_Rx" SG_ 930 CamraRearOn_B_RqBalrr 1;
BA_ "U_P708_MY2023_Rx" SG_ 930 CamraRearOn_B_RqBalrr 1;
BA_ "U_P702_MY2024_Rx" SG_ 930 CamraRearOn_B_RqBalrr 1;
BA_ "U_P708_MY2023_Rx" SG_ 929 BalrChimeLeft_D_Rq 1;
BA_ "U_V713AV_MY2022_Rx" SG_ 929 BalrChimeLeft_D_Rq 1;
BA_ "U_V710_MY2023_Rx" SG_ 929 BalrChimeLeft_D_Rq 1;
BA_ "U_P702_MY2024_Rx" SG_ 929 BalrChimeLeft_D_Rq 1;
BA_ "GenSigStartValue" SG_ 929 BalrLeft_D_Stat 2;
BA_ "U_P708_MY2023_Rx" SG_ 929 BalrLeft_D_Stat 1;
BA_ "U_V713AV_MY2022_Rx" SG_ 929 BalrLeft_D_Stat 1;
BA_ "U_V710_MY2023_Rx" SG_ 929 BalrLeft_D_Stat 1;
BA_ "U_P702_MY2024_Rx" SG_ 929 BalrLeft_D_Stat 1;
BA_ "U_P708_MY2023_Rx" SG_ 929 BalrSnsLeft_D_Falt 1;
BA_ "U_V713AV_MY2022_Rx" SG_ 929 BalrSnsLeft_D_Falt 1;
BA_ "U_V710_MY2023_Rx" SG_ 929 BalrSnsLeft_D_Falt 1;
BA_ "U_P702_MY2024_Rx" SG_ 929 BalrSnsLeft_D_Falt 1;
BA_ "U_P708_MY2023_Rx" SG_ 929 BalrMdeSelLeft_B_Stat 1;
BA_ "U_V713AV_MY2022_Rx" SG_ 929 BalrMdeSelLeft_B_Stat 1;
BA_ "U_V710_MY2023_Rx" SG_ 929 BalrMdeSelLeft_B_Stat 1;
BA_ "U_P702_MY2024_Rx" SG_ 929 BalrMdeSelLeft_B_Stat 1;
BA_ "GenSigStartValue" SG_ 929 BalrMdeLeft_D_Stat 1;
BA_ "U_P708_MY2023_Rx" SG_ 929 BalrMdeLeft_D_Stat 1;
BA_ "U_V713AV_MY2022_Rx" SG_ 929 BalrMdeLeft_D_Stat 1;
BA_ "U_V710_MY2023_Rx" SG_ 929 BalrMdeLeft_D_Stat 1;
BA_ "U_P702_MY2024_Rx" SG_ 929 BalrMdeLeft_D_Stat 1;
BA_ "U_P708_MY2023_Rx" SG_ 929 BalrLckLeft_B_Stat 1;
BA_ "U_V713AV_MY2022_Rx" SG_ 929 BalrLckLeft_B_Stat 1;
BA_ "U_V710_MY2023_Rx" SG_ 929 BalrLckLeft_B_Stat 1;
BA_ "U_P702_MY2024_Rx" SG_ 929 BalrLckLeft_B_Stat 1;
BA_ "U_V713N_MY2022_Rx" SG_ 929 CamraRearOn_B_RqBalrl 1;
BA_ "U_V710_MY2023_Rx" SG_ 929 CamraRearOn_B_RqBalrl 1;
BA_ "U_P708_MY2023_Rx" SG_ 929 CamraRearOn_B_RqBalrl 1;
BA_ "U_P702_MY2024_Rx" SG_ 929 CamraRearOn_B_RqBalrl 1;
BA_ "U_P708_MY2023_Rx" SG_ 929 BalrWndwLeft_B_Stat 1;
BA_ "U_V713AV_MY2022_Rx" SG_ 929 BalrWndwLeft_B_Stat 1;
BA_ "U_V710_MY2023_Rx" SG_ 929 BalrWndwLeft_B_Stat 1;
BA_ "U_P702_MY2024_Rx" SG_ 929 BalrWndwLeft_B_Stat 1;
BA_ "GenSigStartValue" SG_ 788 EcoCochDecel2_Pc_Dsply 255;
BA_ "U_V710_MY2023_Rx" SG_ 788 EcoCochDecel2_Pc_Dsply 1;
BA_ "U_P708_MY2023_Rx" SG_ 788 EcoCochDecel2_Pc_Dsply 1;
BA_ "U_P702_MY2024_Rx" SG_ 788 EcoCochDecel2_Pc_Dsply 1;
BA_ "GenSigStartValue" SG_ 788 EcoCochDecel1_Pc_Dsply 255;
BA_ "U_V710_MY2023_Rx" SG_ 788 EcoCochDecel1_Pc_Dsply 1;
BA_ "U_P708_MY2023_Rx" SG_ 788 EcoCochDecel1_Pc_Dsply 1;
BA_ "U_P702_MY2024_Rx" SG_ 788 EcoCochDecel1_Pc_Dsply 1;
BA_ "GenSigStartValue" SG_ 788 EcoCochCrus2_Pc_Dsply 255;
BA_ "U_V710_MY2023_Rx" SG_ 788 EcoCochCrus2_Pc_Dsply 1;
BA_ "U_P708_MY2023_Rx" SG_ 788 EcoCochCrus2_Pc_Dsply 1;
BA_ "U_P702_MY2024_Rx" SG_ 788 EcoCochCrus2_Pc_Dsply 1;
BA_ "GenSigStartValue" SG_ 788 EcoCochCrus1_Pc_Dsply 255;
BA_ "U_V710_MY2023_Rx" SG_ 788 EcoCochCrus1_Pc_Dsply 1;
BA_ "U_P708_MY2023_Rx" SG_ 788 EcoCochCrus1_Pc_Dsply 1;
BA_ "U_P702_MY2024_Rx" SG_ 788 EcoCochCrus1_Pc_Dsply 1;
BA_ "GenSigStartValue" SG_ 788 EcoCochATrip2_Pc_Dsply 255;
BA_ "U_V710_MY2023_Rx" SG_ 788 EcoCochATrip2_Pc_Dsply 1;
BA_ "U_P708_MY2023_Rx" SG_ 788 EcoCochATrip2_Pc_Dsply 1;
BA_ "U_P702_MY2024_Rx" SG_ 788 EcoCochATrip2_Pc_Dsply 1;
BA_ "GenSigStartValue" SG_ 788 EcoCochATrip1_Pc_Dsply 255;
BA_ "U_V710_MY2023_Rx" SG_ 788 EcoCochATrip1_Pc_Dsply 1;
BA_ "U_P708_MY2023_Rx" SG_ 788 EcoCochATrip1_Pc_Dsply 1;
BA_ "U_P702_MY2024_Rx" SG_ 788 EcoCochATrip1_Pc_Dsply 1;
BA_ "GenSigSendType" SG_ 391 ACU_CtrlChimeChan_Rq 3;
BA_ "U_V713N_MY2022_Tx" SG_ 391 ACU_CtrlChimeChan_Rq 1;
BA_ "U_V713AV_MY2022_Tx" SG_ 391 ACU_CtrlChimeChan_Rq 1;
BA_ "U_P708_MY2023_Tx" SG_ 391 ACU_CtrlChimeChan_Rq 1;
BA_ "U_P708_MY2023_Rx" SG_ 670 DrHandleOuterRl_D_Stat 1;
BA_ "U_P702_MY2024_Rx" SG_ 670 DrHandleOuterRl_D_Stat 1;
BA_ "U_P708_MY2023_Rx" SG_ 670 DrHandleOuterFl_D_Stat 1;
BA_ "U_P702_MY2024_Rx" SG_ 670 DrHandleOuterFl_D_Stat 1;
BA_ "WakeupSignal" SG_ 672 SetVolume 1;
BA_ "GenSigStartValue" SG_ 672 SetVolume 30;
BA_ "GenSigSendType" SG_ 672 SetVolume 3;
BA_ "U_V713N_MY2022_Rx" SG_ 672 SetVolume 1;
BA_ "U_V713AV_MY2022_Rx" SG_ 672 SetVolume 1;
BA_ "U_P708_MY2023_Rx" SG_ 672 SetVolume 1;
BA_ "U_V710_MY2023_Rx" SG_ 672 SetVolume 1;
BA_ "ECGUsedRxSignal" SG_ 672 SetVolume 1;
BA_ "WakeupSignal" SG_ 672 SetPointVolume 1;
BA_ "GenSigSendType" SG_ 672 SetPointVolume 3;
BA_ "U_V713N_MY2022_Rx" SG_ 672 SetPointVolume 1;
BA_ "U_V713AV_MY2022_Rx" SG_ 672 SetPointVolume 1;
BA_ "U_P708_MY2023_Rx" SG_ 672 SetPointVolume 1;
BA_ "U_V710_MY2023_Rx" SG_ 672 SetPointVolume 1;
BA_ "ECGUsedRxSignal" SG_ 672 SetPointVolume 1;
BA_ "WakeupSignal" SG_ 672 Coding_BtnID_D 1;
BA_ "GenSigSendType" SG_ 672 Coding_BtnID_D 3;
BA_ "U_V713N_MY2022_Rx" SG_ 672 Coding_BtnID_D 1;
BA_ "U_V713AV_MY2022_Rx" SG_ 672 Coding_BtnID_D 1;
BA_ "U_P708_MY2023_Rx" SG_ 672 Coding_BtnID_D 1;
BA_ "U_V710_MY2023_Rx" SG_ 672 Coding_BtnID_D 1;
BA_ "WakeupSignal" SG_ 672 Coding_BtnID_C 1;
BA_ "GenSigSendType" SG_ 672 Coding_BtnID_C 3;
BA_ "U_V713N_MY2022_Rx" SG_ 672 Coding_BtnID_C 1;
BA_ "U_V713AV_MY2022_Rx" SG_ 672 Coding_BtnID_C 1;
BA_ "U_P708_MY2023_Rx" SG_ 672 Coding_BtnID_C 1;
BA_ "U_V710_MY2023_Rx" SG_ 672 Coding_BtnID_C 1;
BA_ "WakeupSignal" SG_ 672 Coding_BtnID_B 1;
BA_ "GenSigSendType" SG_ 672 Coding_BtnID_B 3;
BA_ "U_V713N_MY2022_Rx" SG_ 672 Coding_BtnID_B 1;
BA_ "U_V713AV_MY2022_Rx" SG_ 672 Coding_BtnID_B 1;
BA_ "U_P708_MY2023_Rx" SG_ 672 Coding_BtnID_B 1;
BA_ "U_V710_MY2023_Rx" SG_ 672 Coding_BtnID_B 1;
BA_ "WakeupSignal" SG_ 672 Coding_BtnID_A 1;
BA_ "GenSigSendType" SG_ 672 Coding_BtnID_A 3;
BA_ "U_V713N_MY2022_Rx" SG_ 672 Coding_BtnID_A 1;
BA_ "U_V713AV_MY2022_Rx" SG_ 672 Coding_BtnID_A 1;
BA_ "U_P708_MY2023_Rx" SG_ 672 Coding_BtnID_A 1;
BA_ "U_V710_MY2023_Rx" SG_ 672 Coding_BtnID_A 1;
BA_ "WakeupSignal" SG_ 672 BtnID_D 1;
BA_ "GenSigStartValue" SG_ 672 BtnID_D 255;
BA_ "U_V713N_MY2022_Rx" SG_ 672 BtnID_D 1;
BA_ "U_V713AV_MY2022_Rx" SG_ 672 BtnID_D 1;
BA_ "U_P708_MY2023_Rx" SG_ 672 BtnID_D 1;
BA_ "U_V710_MY2023_Rx" SG_ 672 BtnID_D 1;
BA_ "WakeupSignal" SG_ 672 BtnID_C 1;
BA_ "GenSigStartValue" SG_ 672 BtnID_C 255;
BA_ "U_V713N_MY2022_Rx" SG_ 672 BtnID_C 1;
BA_ "U_V713AV_MY2022_Rx" SG_ 672 BtnID_C 1;
BA_ "U_P708_MY2023_Rx" SG_ 672 BtnID_C 1;
BA_ "U_V710_MY2023_Rx" SG_ 672 BtnID_C 1;
BA_ "WakeupSignal" SG_ 672 BtnID_B 1;
BA_ "GenSigStartValue" SG_ 672 BtnID_B 255;
BA_ "U_V713N_MY2022_Rx" SG_ 672 BtnID_B 1;
BA_ "U_V713AV_MY2022_Rx" SG_ 672 BtnID_B 1;
BA_ "U_P708_MY2023_Rx" SG_ 672 BtnID_B 1;
BA_ "U_V710_MY2023_Rx" SG_ 672 BtnID_B 1;
BA_ "WakeupSignal" SG_ 672 BtnID_A 1;
BA_ "GenSigStartValue" SG_ 672 BtnID_A 255;
BA_ "U_V713N_MY2022_Rx" SG_ 672 BtnID_A 1;
BA_ "U_V713AV_MY2022_Rx" SG_ 672 BtnID_A 1;
BA_ "U_P708_MY2023_Rx" SG_ 672 BtnID_A 1;
BA_ "U_V710_MY2023_Rx" SG_ 672 BtnID_A 1;
BA_ "U_P708_MY2023_Rx" SG_ 672 BCP_Audible_Beep_Rq 1;
BA_ "U_V710_MY2023_Rx" SG_ 672 BCP_Audible_Beep_Rq 1;
BA_ "U_V713AV_MY2022_Rx" SG_ 1205 CstmDrvMdeCfg2_B_Avail 1;
BA_ "U_P708_MY2023_Rx" SG_ 1205 CstmDrvMdeCfg2_B_Avail 1;
BA_ "U_V710_MY2023_Rx" SG_ 1205 CstmDrvMdeCfg2_B_Avail 1;
BA_ "U_P702_MY2024_Rx" SG_ 1205 CstmDrvMdeCfg2_B_Avail 1;
BA_ "U_V713AV_MY2022_Rx" SG_ 1205 CstmDrvMdeCfg1_B_Avail 1;
BA_ "U_P708_MY2023_Rx" SG_ 1205 CstmDrvMdeCfg1_B_Avail 1;
BA_ "U_V710_MY2023_Rx" SG_ 1205 CstmDrvMdeCfg1_B_Avail 1;
BA_ "U_P702_MY2024_Rx" SG_ 1205 CstmDrvMdeCfg1_B_Avail 1;
BA_ "GenSigStartValue" SG_ 1205 CstmDrvMde_No_Confg2 63;
BA_ "U_V713AV_MY2022_Rx" SG_ 1205 CstmDrvMde_No_Confg2 1;
BA_ "U_P708_MY2023_Rx" SG_ 1205 CstmDrvMde_No_Confg2 1;
BA_ "U_V710_MY2023_Rx" SG_ 1205 CstmDrvMde_No_Confg2 1;
BA_ "U_P702_MY2024_Rx" SG_ 1205 CstmDrvMde_No_Confg2 1;
BA_ "GenSigStartValue" SG_ 1205 CstmDrvMde_No_Confg1 63;
BA_ "U_V713AV_MY2022_Rx" SG_ 1205 CstmDrvMde_No_Confg1 1;
BA_ "U_P708_MY2023_Rx" SG_ 1205 CstmDrvMde_No_Confg1 1;
BA_ "U_V710_MY2023_Rx" SG_ 1205 CstmDrvMde_No_Confg1 1;
BA_ "U_P702_MY2024_Rx" SG_ 1205 CstmDrvMde_No_Confg1 1;
BA_ "U_V713AV_MY2022_Rx" SG_ 1205 CstmDrvMde_No_Confg 1;
BA_ "U_P708_MY2023_Rx" SG_ 1205 CstmDrvMde_No_Confg 1;
BA_ "U_V710_MY2023_Rx" SG_ 1205 CstmDrvMde_No_Confg 1;
BA_ "U_P702_MY2024_Rx" SG_ 1205 CstmDrvMde_No_Confg 1;
BA_ "GenSigStartValue" SG_ 1205 CstmDrvMde5_No_Confg2 15;
BA_ "U_V713AV_MY2022_Rx" SG_ 1205 CstmDrvMde5_No_Confg2 1;
BA_ "U_P708_MY2023_Rx" SG_ 1205 CstmDrvMde5_No_Confg2 1;
BA_ "U_V710_MY2023_Rx" SG_ 1205 CstmDrvMde5_No_Confg2 1;
BA_ "U_P702_MY2024_Rx" SG_ 1205 CstmDrvMde5_No_Confg2 1;
BA_ "GenSigStartValue" SG_ 1205 CstmDrvMde5_No_Confg1 15;
BA_ "U_V713AV_MY2022_Rx" SG_ 1205 CstmDrvMde5_No_Confg1 1;
BA_ "U_P708_MY2023_Rx" SG_ 1205 CstmDrvMde5_No_Confg1 1;
BA_ "U_V710_MY2023_Rx" SG_ 1205 CstmDrvMde5_No_Confg1 1;
BA_ "U_P702_MY2024_Rx" SG_ 1205 CstmDrvMde5_No_Confg1 1;
BA_ "GenSigStartValue" SG_ 1205 CstmDrvMde4_No_Confg2 15;
BA_ "U_V713AV_MY2022_Rx" SG_ 1205 CstmDrvMde4_No_Confg2 1;
BA_ "U_P708_MY2023_Rx" SG_ 1205 CstmDrvMde4_No_Confg2 1;
BA_ "U_V710_MY2023_Rx" SG_ 1205 CstmDrvMde4_No_Confg2 1;
BA_ "U_P702_MY2024_Rx" SG_ 1205 CstmDrvMde4_No_Confg2 1;
BA_ "GenSigStartValue" SG_ 1205 CstmDrvMde4_No_Confg1 15;
BA_ "U_V713AV_MY2022_Rx" SG_ 1205 CstmDrvMde4_No_Confg1 1;
BA_ "U_P708_MY2023_Rx" SG_ 1205 CstmDrvMde4_No_Confg1 1;
BA_ "U_V710_MY2023_Rx" SG_ 1205 CstmDrvMde4_No_Confg1 1;
BA_ "U_P702_MY2024_Rx" SG_ 1205 CstmDrvMde4_No_Confg1 1;
BA_ "GenSigStartValue" SG_ 1205 CstmDrvMde3_No_Confg2 15;
BA_ "U_V713AV_MY2022_Rx" SG_ 1205 CstmDrvMde3_No_Confg2 1;
BA_ "U_P708_MY2023_Rx" SG_ 1205 CstmDrvMde3_No_Confg2 1;
BA_ "U_V710_MY2023_Rx" SG_ 1205 CstmDrvMde3_No_Confg2 1;
BA_ "U_P702_MY2024_Rx" SG_ 1205 CstmDrvMde3_No_Confg2 1;
BA_ "GenSigStartValue" SG_ 1205 CstmDrvMde3_No_Confg1 15;
BA_ "U_V713AV_MY2022_Rx" SG_ 1205 CstmDrvMde3_No_Confg1 1;
BA_ "U_P708_MY2023_Rx" SG_ 1205 CstmDrvMde3_No_Confg1 1;
BA_ "U_V710_MY2023_Rx" SG_ 1205 CstmDrvMde3_No_Confg1 1;
BA_ "U_P702_MY2024_Rx" SG_ 1205 CstmDrvMde3_No_Confg1 1;
BA_ "GenSigStartValue" SG_ 1205 CstmDrvMde2_No_Confg2 15;
BA_ "U_V713AV_MY2022_Rx" SG_ 1205 CstmDrvMde2_No_Confg2 1;
BA_ "U_P708_MY2023_Rx" SG_ 1205 CstmDrvMde2_No_Confg2 1;
BA_ "U_V710_MY2023_Rx" SG_ 1205 CstmDrvMde2_No_Confg2 1;
BA_ "U_P702_MY2024_Rx" SG_ 1205 CstmDrvMde2_No_Confg2 1;
BA_ "GenSigStartValue" SG_ 1205 CstmDrvMde2_No_Confg1 15;
BA_ "U_V713AV_MY2022_Rx" SG_ 1205 CstmDrvMde2_No_Confg1 1;
BA_ "U_P708_MY2023_Rx" SG_ 1205 CstmDrvMde2_No_Confg1 1;
BA_ "U_V710_MY2023_Rx" SG_ 1205 CstmDrvMde2_No_Confg1 1;
BA_ "U_P702_MY2024_Rx" SG_ 1205 CstmDrvMde2_No_Confg1 1;
BA_ "GenSigStartValue" SG_ 1205 CstmDrvMde1_No_Confg2 15;
BA_ "U_V713AV_MY2022_Rx" SG_ 1205 CstmDrvMde1_No_Confg2 1;
BA_ "U_P708_MY2023_Rx" SG_ 1205 CstmDrvMde1_No_Confg2 1;
BA_ "U_V710_MY2023_Rx" SG_ 1205 CstmDrvMde1_No_Confg2 1;
BA_ "U_P702_MY2024_Rx" SG_ 1205 CstmDrvMde1_No_Confg2 1;
BA_ "GenSigStartValue" SG_ 1205 CstmDrvMde1_No_Confg1 15;
BA_ "U_V713AV_MY2022_Rx" SG_ 1205 CstmDrvMde1_No_Confg1 1;
BA_ "U_P708_MY2023_Rx" SG_ 1205 CstmDrvMde1_No_Confg1 1;
BA_ "U_V710_MY2023_Rx" SG_ 1205 CstmDrvMde1_No_Confg1 1;
BA_ "U_P702_MY2024_Rx" SG_ 1205 CstmDrvMde1_No_Confg1 1;
BA_ "GenSigStartValue" SG_ 1200 BrkBstrVac_P_Actl 127;
BA_ "U_P708_MY2023_Rx" SG_ 1200 BrkTot_Tq_RqDrv 1;
BA_ "MetaData" SG_ 1200 BrkTotTqRqDrv_No_Cnt 1;
BA_ "MetaData" SG_ 1200 BrkTotTqRqDrv_No_Cs 1;
BA_ "U_V713N_MY2022_Rx" SG_ 593 ECG_MC_WORD_Tx 1;
BA_ "U_V713AV_MY2022_Rx" SG_ 593 ECG_MC_WORD_Tx 1;
BA_ "U_P708_MY2023_Rx" SG_ 593 ECG_MC_WORD_Tx 1;
BA_ "U_P702_MY2024_Rx" SG_ 593 ECG_MC_WORD_Tx 1;
BA_ "ECGUsedTxSignal" SG_ 593 ECG_MC_WORD_Tx 1;
BA_ "U_V713AV_MY2022_Tx" SG_ 593 ECG_MC_WORD_Tx 1;
BA_ "U_CDX74X_MY2024_Tx" SG_ 593 ECG_MC_WORD_Tx 1;
BA_ "U_V710_MY2023_Tx" SG_ 593 ECG_MC_WORD_Tx 1;
BA_ "ECGUsedRxSignal" SG_ 601 ECG_MC_WORD_Rx 1;
BA_ "U_V713N_MY2022_Rx" SG_ 601 ECG_MC_WORD_Rx 1;
BA_ "U_V713AV_MY2022_Rx" SG_ 601 ECG_MC_WORD_Rx 1;
BA_ "U_P708_MY2023_Rx" SG_ 601 ECG_MC_WORD_Rx 1;
BA_ "U_CDX74X_MY2024_Rx" SG_ 601 ECG_MC_WORD_Rx 1;
BA_ "U_V710_MY2023_Rx" SG_ 601 ECG_MC_WORD_Rx 1;
BA_ "U_P708_MY2023_Tx" SG_ 601 ECG_MC_WORD_Rx 1;
BA_ "U_P702_MY2024_Tx" SG_ 601 ECG_MC_WORD_Rx 1;
BA_ "U_P708_MY2023_Rx" SG_ 1018 TrlrTireSensILM_D_Stat 1;
BA_ "U_V710_MY2023_Rx" SG_ 1018 TrlrTireSensILM_D_Stat 1;
BA_ "U_P702_MY2024_Rx" SG_ 1018 TrlrTireSensILM_D_Stat 1;
BA_ "U_P708_MY2023_Rx" SG_ 1018 TrlrTireSensILF_D_Stat 1;
BA_ "U_V710_MY2023_Rx" SG_ 1018 TrlrTireSensILF_D_Stat 1;
BA_ "U_P702_MY2024_Rx" SG_ 1018 TrlrTireSensILF_D_Stat 1;
BA_ "GenSigStartValue" SG_ 1018 TrlrTireILR_P_Actl 65533;
BA_ "U_P708_MY2023_Rx" SG_ 1018 TrlrTireILR_P_Actl 1;
BA_ "U_V710_MY2023_Rx" SG_ 1018 TrlrTireILR_P_Actl 1;
BA_ "U_P702_MY2024_Rx" SG_ 1018 TrlrTireILR_P_Actl 1;
BA_ "GenSigStartValue" SG_ 1018 TrlrTireILM_P_Actl 65533;
BA_ "U_P708_MY2023_Rx" SG_ 1018 TrlrTireILM_P_Actl 1;
BA_ "U_V710_MY2023_Rx" SG_ 1018 TrlrTireILM_P_Actl 1;
BA_ "U_P702_MY2024_Rx" SG_ 1018 TrlrTireILM_P_Actl 1;
BA_ "GenSigStartValue" SG_ 1018 TrlrTireILF_P_Actl 65533;
BA_ "U_P708_MY2023_Rx" SG_ 1018 TrlrTireILF_P_Actl 1;
BA_ "U_V710_MY2023_Rx" SG_ 1018 TrlrTireILF_P_Actl 1;
BA_ "U_P702_MY2024_Rx" SG_ 1018 TrlrTireILF_P_Actl 1;
BA_ "U_P708_MY2023_Rx" SG_ 1018 TrlrTireSensILR_D_Stat 1;
BA_ "U_V710_MY2023_Rx" SG_ 1018 TrlrTireSensILR_D_Stat 1;
BA_ "U_P702_MY2024_Rx" SG_ 1018 TrlrTireSensILR_D_Stat 1;
BA_ "GenSigStartValue" SG_ 1238 Fba_D_Stat 1;
BA_ "U_P702_MY2024_Rx" SG_ 1238 TjaLcEnbl_D_Stat 1;
BA_ "U_P708_MY2023_Rx" SG_ 1238 GfhbMnu_D_Rq 1;
BA_ "U_V710_MY2023_Rx" SG_ 1238 GfhbMnu_D_Rq 1;
BA_ "U_P702_MY2024_Rx" SG_ 1238 GfhbMnu_D_Rq 1;
BA_ "U_P708_MY2023_Rx" SG_ 1238 AhbcMnu_D_Rq 1;
BA_ "U_V710_MY2023_Rx" SG_ 1238 AhbcMnu_D_Rq 1;
BA_ "U_P702_MY2024_Rx" SG_ 1238 AhbcMnu_D_Rq 1;
BA_ "U_V710_MY2023_Rx" SG_ 1238 TjaLaneBias_D_Stat 1;
BA_ "U_P702_MY2024_Rx" SG_ 1238 TjaLaneBias_D_Stat 1;
BA_ "U_V710_MY2023_Rx" SG_ 1238 TjaLaneBiasEnbl_D_Stat 1;
BA_ "U_P708_MY2023_Rx" SG_ 1238 TjaLaneBiasEnbl_D_Stat 1;
BA_ "U_P702_MY2024_Rx" SG_ 1238 TjaLaneBiasEnbl_D_Stat 1;
BA_ "U_V713N_MY2022_Rx" SG_ 1238 IaccVAdjReas_D_Dsply 1;
BA_ "U_P708_MY2023_Rx" SG_ 1238 IaccVAdjReas_D_Dsply 1;
BA_ "U_V710_MY2023_Rx" SG_ 1238 IaccVAdjReas_D_Dsply 1;
BA_ "U_V713AV_MY2022_Rx" SG_ 1238 IaccVAdjReas_D_Dsply 1;
BA_ "U_P702_MY2024_Rx" SG_ 1238 IaccVAdjReas_D_Dsply 1;
BA_ "U_V713N_MY2022_Rx" SG_ 1238 IaccVAdjLim_No_Actl 1;
BA_ "U_P708_MY2023_Rx" SG_ 1238 IaccVAdjLim_No_Actl 1;
BA_ "U_V710_MY2023_Rx" SG_ 1238 IaccVAdjLim_No_Actl 1;
BA_ "U_V713AV_MY2022_Rx" SG_ 1238 IaccVAdjLim_No_Actl 1;
BA_ "U_P702_MY2024_Rx" SG_ 1238 IaccVAdjLim_No_Actl 1;
BA_ "GenSigSendType" SG_ 766 McCntrStckNotfn_B_Stat 3;
BA_ "U_P708_MY2023_Rx" SG_ 766 McCntrStckNotfn_B_Stat 1;
BA_ "U_P708_MY2023_Tx" SG_ 766 McCntrStckNotfn_B_Stat 1;
BA_ "U_P708_MY2023_Rx" SG_ 766 McSelMsgId_No_Actl 1;
BA_ "U_P708_MY2023_Tx" SG_ 766 McSelMsgId_No_Actl 1;
BA_ "GenSigSendType" SG_ 766 McSelMsgId_B_Stat 3;
BA_ "U_P708_MY2023_Rx" SG_ 766 McSelMsgId_B_Stat 1;
BA_ "U_P708_MY2023_Tx" SG_ 766 McSelMsgId_B_Stat 1;
BA_ "U_P708_MY2023_Rx" SG_ 766 McSelChoice_D_Stat 1;
BA_ "U_P708_MY2023_Tx" SG_ 766 McSelChoice_D_Stat 1;
BA_ "GenSigSendType" SG_ 766 McPrsntMsgId_No_Actl 3;
BA_ "U_P708_MY2023_Rx" SG_ 766 McPrsntMsgId_No_Actl 1;
BA_ "U_P708_MY2023_Tx" SG_ 766 McPrsntMsgId_No_Actl 1;
BA_ "GenSigSendType" SG_ 766 McPrsntMsgId_B_Stat 3;
BA_ "U_P708_MY2023_Rx" SG_ 766 McPrsntMsgId_B_Stat 1;
BA_ "U_P708_MY2023_Tx" SG_ 766 McPrsntMsgId_B_Stat 1;
BA_ "GenSigSendType" SG_ 766 McPrsntActv_D_Stat 3;
BA_ "U_P708_MY2023_Rx" SG_ 766 McPrsntActv_D_Stat 1;
BA_ "U_P708_MY2023_Tx" SG_ 766 McPrsntActv_D_Stat 1;
BA_ "GenSigSendType" SG_ 840 FohAddHeater_D_Rq 3;
BA_ "U_V710_MY2023_Tx" SG_ 840 FohAddHeater_D_Rq 1;
BA_ "U_V713AV_MY2022_Tx" SG_ 840 FohAddHeater_D_Rq 1;
BA_ "U_P708_MY2023_Tx" SG_ 840 FohAddHeater_D_Rq 1;
BA_ "U_P702_MY2024_Tx" SG_ 840 FohAddHeater_D_Rq 1;
BA_ "U_V710_MY2023_Tx" SG_ 840 FohStrtDateYr_No_Rq 1;
BA_ "U_V713AV_MY2022_Tx" SG_ 840 FohStrtDateYr_No_Rq 1;
BA_ "U_P708_MY2023_Tx" SG_ 840 FohStrtDateYr_No_Rq 1;
BA_ "U_P702_MY2024_Tx" SG_ 840 FohStrtDateYr_No_Rq 1;
BA_ "U_V710_MY2023_Tx" SG_ 840 FohStrtDateDay_No_Rq 1;
BA_ "U_V713AV_MY2022_Tx" SG_ 840 FohStrtDateDay_No_Rq 1;
BA_ "U_P708_MY2023_Tx" SG_ 840 FohStrtDateDay_No_Rq 1;
BA_ "U_P702_MY2024_Tx" SG_ 840 FohStrtDateDay_No_Rq 1;
BA_ "GenSigSendType" SG_ 840 FohT2Friday_T_Rq 3;
BA_ "U_V710_MY2023_Tx" SG_ 840 FohT2Friday_T_Rq 1;
BA_ "U_V713AV_MY2022_Tx" SG_ 840 FohT2Friday_T_Rq 1;
BA_ "U_P708_MY2023_Tx" SG_ 840 FohT2Friday_T_Rq 1;
BA_ "U_P702_MY2024_Tx" SG_ 840 FohT2Friday_T_Rq 1;
BA_ "GenSigSendType" SG_ 840 FohT1Friday_T_Rq 3;
BA_ "U_V710_MY2023_Tx" SG_ 840 FohT1Friday_T_Rq 1;
BA_ "U_V713AV_MY2022_Tx" SG_ 840 FohT1Friday_T_Rq 1;
BA_ "U_P708_MY2023_Tx" SG_ 840 FohT1Friday_T_Rq 1;
BA_ "U_P702_MY2024_Tx" SG_ 840 FohT1Friday_T_Rq 1;
BA_ "GenSigSendType" SG_ 840 FohT2Wednesday_T_Rq 3;
BA_ "U_V710_MY2023_Tx" SG_ 840 FohT2Wednesday_T_Rq 1;
BA_ "U_V713AV_MY2022_Tx" SG_ 840 FohT2Wednesday_T_Rq 1;
BA_ "U_P708_MY2023_Tx" SG_ 840 FohT2Wednesday_T_Rq 1;
BA_ "U_P702_MY2024_Tx" SG_ 840 FohT2Wednesday_T_Rq 1;
BA_ "GenSigSendType" SG_ 840 FohT2Tuesday_T_Rq 3;
BA_ "U_V710_MY2023_Tx" SG_ 840 FohT2Tuesday_T_Rq 1;
BA_ "U_V713AV_MY2022_Tx" SG_ 840 FohT2Tuesday_T_Rq 1;
BA_ "U_P708_MY2023_Tx" SG_ 840 FohT2Tuesday_T_Rq 1;
BA_ "U_P702_MY2024_Tx" SG_ 840 FohT2Tuesday_T_Rq 1;
BA_ "GenSigSendType" SG_ 840 FohT2Thursday_T_Rq 3;
BA_ "U_V710_MY2023_Tx" SG_ 840 FohT2Thursday_T_Rq 1;
BA_ "U_V713AV_MY2022_Tx" SG_ 840 FohT2Thursday_T_Rq 1;
BA_ "U_P708_MY2023_Tx" SG_ 840 FohT2Thursday_T_Rq 1;
BA_ "U_P702_MY2024_Tx" SG_ 840 FohT2Thursday_T_Rq 1;
BA_ "GenSigSendType" SG_ 840 FohT2Sunday_T_Rq 3;
BA_ "U_V710_MY2023_Tx" SG_ 840 FohT2Sunday_T_Rq 1;
BA_ "U_V713AV_MY2022_Tx" SG_ 840 FohT2Sunday_T_Rq 1;
BA_ "U_P708_MY2023_Tx" SG_ 840 FohT2Sunday_T_Rq 1;
BA_ "U_P702_MY2024_Tx" SG_ 840 FohT2Sunday_T_Rq 1;
BA_ "GenSigSendType" SG_ 840 FohT2Saturday_T_Rq 3;
BA_ "U_V710_MY2023_Tx" SG_ 840 FohT2Saturday_T_Rq 1;
BA_ "U_V713AV_MY2022_Tx" SG_ 840 FohT2Saturday_T_Rq 1;
BA_ "U_P708_MY2023_Tx" SG_ 840 FohT2Saturday_T_Rq 1;
BA_ "U_P702_MY2024_Tx" SG_ 840 FohT2Saturday_T_Rq 1;
BA_ "GenSigSendType" SG_ 840 FohT2Monday_T_Rq 3;
BA_ "U_V710_MY2023_Tx" SG_ 840 FohT2Monday_T_Rq 1;
BA_ "U_V713AV_MY2022_Tx" SG_ 840 FohT2Monday_T_Rq 1;
BA_ "U_P708_MY2023_Tx" SG_ 840 FohT2Monday_T_Rq 1;
BA_ "U_P702_MY2024_Tx" SG_ 840 FohT2Monday_T_Rq 1;
BA_ "GenSigSendType" SG_ 840 FohT1Wednesday_T_Rq 3;
BA_ "U_V710_MY2023_Tx" SG_ 840 FohT1Wednesday_T_Rq 1;
BA_ "U_V713AV_MY2022_Tx" SG_ 840 FohT1Wednesday_T_Rq 1;
BA_ "U_P708_MY2023_Tx" SG_ 840 FohT1Wednesday_T_Rq 1;
BA_ "U_P702_MY2024_Tx" SG_ 840 FohT1Wednesday_T_Rq 1;
BA_ "GenSigSendType" SG_ 840 FohT1Tuesday_T_Rq 3;
BA_ "U_V710_MY2023_Tx" SG_ 840 FohT1Tuesday_T_Rq 1;
BA_ "U_V713AV_MY2022_Tx" SG_ 840 FohT1Tuesday_T_Rq 1;
BA_ "U_P708_MY2023_Tx" SG_ 840 FohT1Tuesday_T_Rq 1;
BA_ "U_P702_MY2024_Tx" SG_ 840 FohT1Tuesday_T_Rq 1;
BA_ "GenSigSendType" SG_ 840 FohT1Thursday_T_Rq 3;
BA_ "U_V710_MY2023_Tx" SG_ 840 FohT1Thursday_T_Rq 1;
BA_ "U_V713AV_MY2022_Tx" SG_ 840 FohT1Thursday_T_Rq 1;
BA_ "U_P708_MY2023_Tx" SG_ 840 FohT1Thursday_T_Rq 1;
BA_ "U_P702_MY2024_Tx" SG_ 840 FohT1Thursday_T_Rq 1;
BA_ "GenSigSendType" SG_ 840 FohT1Sunday_T_Rq 3;
BA_ "U_V710_MY2023_Tx" SG_ 840 FohT1Sunday_T_Rq 1;
BA_ "U_V713AV_MY2022_Tx" SG_ 840 FohT1Sunday_T_Rq 1;
BA_ "U_P708_MY2023_Tx" SG_ 840 FohT1Sunday_T_Rq 1;
BA_ "U_P702_MY2024_Tx" SG_ 840 FohT1Sunday_T_Rq 1;
BA_ "GenSigSendType" SG_ 840 FohT1Saturday_T_Rq 3;
BA_ "U_V710_MY2023_Tx" SG_ 840 FohT1Saturday_T_Rq 1;
BA_ "U_V713AV_MY2022_Tx" SG_ 840 FohT1Saturday_T_Rq 1;
BA_ "U_P708_MY2023_Tx" SG_ 840 FohT1Saturday_T_Rq 1;
BA_ "U_P702_MY2024_Tx" SG_ 840 FohT1Saturday_T_Rq 1;
BA_ "GenSigSendType" SG_ 840 FohT1Monday_T_Rq 3;
BA_ "U_V710_MY2023_Tx" SG_ 840 FohT1Monday_T_Rq 1;
BA_ "U_V713AV_MY2022_Tx" SG_ 840 FohT1Monday_T_Rq 1;
BA_ "U_P708_MY2023_Tx" SG_ 840 FohT1Monday_T_Rq 1;
BA_ "U_P702_MY2024_Tx" SG_ 840 FohT1Monday_T_Rq 1;
BA_ "GenSigSendType" SG_ 494 HEC_TUPresetArea_Rq 3;
BA_ "U_V713N_MY2022_Rx" SG_ 494 HEC_TUPresetArea_Rq 1;
BA_ "U_V713AV_MY2022_Rx" SG_ 494 HEC_TUPresetArea_Rq 1;
BA_ "U_P708_MY2023_Rx" SG_ 494 HEC_TUPresetArea_Rq 1;
BA_ "U_V710_MY2023_Rx" SG_ 494 HEC_TUPresetArea_Rq 1;
BA_ "U_V713N_MY2022_Tx" SG_ 494 HEC_TUPresetArea_Rq 1;
BA_ "U_V713AV_MY2022_Tx" SG_ 494 HEC_TUPresetArea_Rq 1;
BA_ "U_P702_MY2024_Tx" SG_ 494 HEC_TUPresetArea_Rq 1;
BA_ "GenSigSendType" SG_ 494 Mc_SetCurrPreset2_Rq 3;
BA_ "U_V713N_MY2022_Rx" SG_ 494 Mc_SetCurrPreset2_Rq 1;
BA_ "U_V713AV_MY2022_Rx" SG_ 494 Mc_SetCurrPreset2_Rq 1;
BA_ "U_P708_MY2023_Rx" SG_ 494 Mc_SetCurrPreset2_Rq 1;
BA_ "U_V710_MY2023_Rx" SG_ 494 Mc_SetCurrPreset2_Rq 1;
BA_ "U_V713N_MY2022_Tx" SG_ 494 Mc_SetCurrPreset2_Rq 1;
BA_ "U_V713AV_MY2022_Tx" SG_ 494 Mc_SetCurrPreset2_Rq 1;
BA_ "U_V710_MY2023_Tx" SG_ 494 Mc_SetCurrPreset2_Rq 1;
BA_ "U_P702_MY2024_Tx" SG_ 494 Mc_SetCurrPreset2_Rq 1;
BA_ "U_V713N_MY2022_Rx" SG_ 494 HEC_TUNbrOfPresets_Rq 1;
BA_ "U_V713AV_MY2022_Rx" SG_ 494 HEC_TUNbrOfPresets_Rq 1;
BA_ "U_P708_MY2023_Rx" SG_ 494 HEC_TUNbrOfPresets_Rq 1;
BA_ "U_V710_MY2023_Rx" SG_ 494 HEC_TUNbrOfPresets_Rq 1;
BA_ "U_V713N_MY2022_Tx" SG_ 494 HEC_TUNbrOfPresets_Rq 1;
BA_ "U_V713AV_MY2022_Tx" SG_ 494 HEC_TUNbrOfPresets_Rq 1;
BA_ "U_P702_MY2024_Tx" SG_ 494 HEC_TUNbrOfPresets_Rq 1;
BA_ "GenSigSendType" SG_ 494 HEC_SetCurrTUBand_Rq 3;
BA_ "U_V713N_MY2022_Rx" SG_ 494 HEC_SetCurrTUBand_Rq 1;
BA_ "U_V713AV_MY2022_Rx" SG_ 494 HEC_SetCurrTUBand_Rq 1;
BA_ "U_P708_MY2023_Rx" SG_ 494 HEC_SetCurrTUBand_Rq 1;
BA_ "U_V710_MY2023_Rx" SG_ 494 HEC_SetCurrTUBand_Rq 1;
BA_ "U_V713N_MY2022_Tx" SG_ 494 HEC_SetCurrTUBand_Rq 1;
BA_ "U_V713AV_MY2022_Tx" SG_ 494 HEC_SetCurrTUBand_Rq 1;
BA_ "U_P702_MY2024_Tx" SG_ 494 HEC_SetCurrTUBand_Rq 1;
BA_ "U_V713N_MY2022_Rx" SG_ 494 HEC_TUStartIndex2_Rq 1;
BA_ "U_V713AV_MY2022_Rx" SG_ 494 HEC_TUStartIndex2_Rq 1;
BA_ "U_P708_MY2023_Rx" SG_ 494 HEC_TUStartIndex2_Rq 1;
BA_ "U_V710_MY2023_Rx" SG_ 494 HEC_TUStartIndex2_Rq 1;
BA_ "U_V713N_MY2022_Tx" SG_ 494 HEC_TUStartIndex2_Rq 1;
BA_ "U_V713AV_MY2022_Tx" SG_ 494 HEC_TUStartIndex2_Rq 1;
BA_ "U_P702_MY2024_Tx" SG_ 494 HEC_TUStartIndex2_Rq 1;
BA_ "U_V713N_MY2022_Rx" SG_ 714 SDARS_MC_WORD_Rx 1;
BA_ "U_V713AV_MY2022_Rx" SG_ 714 SDARS_MC_WORD_Rx 1;
BA_ "U_P708_MY2023_Rx" SG_ 714 SDARS_MC_WORD_Rx 1;
BA_ "U_V710_MY2023_Rx" SG_ 714 SDARS_MC_WORD_Rx 1;
BA_ "U_V713N_MY2022_Tx" SG_ 714 SDARS_MC_WORD_Rx 1;
BA_ "U_V713AV_MY2022_Tx" SG_ 714 SDARS_MC_WORD_Rx 1;
BA_ "U_P708_MY2023_Tx" SG_ 714 SDARS_MC_WORD_Rx 1;
BA_ "U_P702_MY2024_Tx" SG_ 714 SDARS_MC_WORD_Rx 1;
VAL_ 803 DistTripUnit_D_Stat 3 "NotUsed" 2 "Miles" 1 "Kilometers" 0 "Inactive" ;
VAL_ 802 AvgFeTripUnit_D_Stat 15 "NotUsed_12" 14 "NotUsed_11" 13 "NotUsed_10" 12 "NotUsed_9" 11 "NotUsed_8" 10 "NotUsed_7" 9 "NotUsed_6" 8 "NotUsed_5" 7 "NotUsed_4" 6 "NotUsed_3" 5 "NotUsed_2" 4 "NotUsed_1" 3 "LiterPer100kilometer" 2 "KilometerPerLiter" 1 "MilePerGallon" 0 "Inactive" ;
VAL_ 802 AvgFeTrip2Actv_B_Dsply 1 "Active" 0 "Inactive" ;
VAL_ 802 AvgFeTrip1Actv_B_Dsply 1 "Active" 0 "Inactive" ;
VAL_ 802 AvgFeActv_B_Dsply 1 "Active" 0 "Inactive" ;
VAL_ 812 TimerTrip2_T_Dsply 0 "0 second" ;
VAL_ 812 TimerTrip1_T_Dsply 0 "0 second" ;
VAL_ 885 VehStrtInhbt_D_Dsply 15 "NotUsed_12" 14 "NotUsed_11" 13 "NotUsed_10" 12 "NotUsed_9" 11 "NotUsed_8" 10 "NotUsed_7" 9 "NotUsed_6" 8 "NotUsed_5" 7 "NotUsed_4" 6 "FleetPhoneNumber" 5 "FleetGeneral" 4 "OtaSuccess" 3 "PostOtaActivatePermFail" 2 "PostOtaActivateWarning" 1 "DuringOtaActivate" 0 "NoMessage" ;
VAL_ 885 OtaActv_D_Stat 15 "NotUsed_10" 14 "NotUsed_9" 13 "NotUsed_8" 12 "NotUsed_7" 11 "NotUsed_6" 10 "NotUsed_5" 9 "NotUsed_4" 8 "NotUsed_3" 7 "NotUsed_2" 6 "NotUsed_1" 5 "NonInterruptible_Pending" 4 "NonInterruptible_Config" 3 "NonInterruptible_ER" 2 "NonInterruptible_AB" 1 "Interruptible_AB" 0 "NoInVehicleOta" ;
VAL_ 784 TrlrTireTSensRr_D_Stat 3 "Faulty" 2 "HighTempWarning" 1 "Normal" 0 "NotAvailable" ;
VAL_ 784 TrlrTireTSensRm_D_Stat 3 "Faulty" 2 "HighTempWarning" 1 "Normal" 0 "NotAvailable" ;
VAL_ 784 TrlrTireTSensRf_D_Stat 3 "Faulty" 2 "HighTempWarning" 1 "Normal" 0 "NotAvailable" ;
VAL_ 784 TrlrTireTSensLr_D_Stat 3 "Faulty" 2 "HighTempWarning" 1 "Normal" 0 "NotAvailable" ;
VAL_ 784 TrlrTireTSensLm_D_Stat 3 "Faulty" 2 "HighTempWarning" 1 "Normal" 0 "NotAvailable" ;
VAL_ 784 TrlrTireTSensLf_D_Stat 3 "Faulty" 2 "HighTempWarning" 1 "Normal" 0 "NotAvailable" ;
VAL_ 784 TrlrTireTempSys_D_Stat 3 "Faulty" 2 "HighTempWarning" 1 "Normal" 0 "NotSupported" ;
VAL_ 784 TrlrTireRr_T_Actl 255 "NotSupported" 254 "Invalid" ;
VAL_ 784 TrlrTireRm_T_Actl 255 "NotSupported" 254 "Invalid" ;
VAL_ 784 TrlrTireRf_T_Actl 255 "NotSupported" 254 "Invalid" ;
VAL_ 784 TrlrTireLr_T_Actl 255 "NotSupported" 254 "Invalid" ;
VAL_ 784 TrlrTireLm_T_Actl 255 "NotSupported" 254 "Invalid" ;
VAL_ 784 TrlrTireLf_T_Actl 255 "NotSupported" 254 "Invalid" ;
VAL_ 290 WifiHtsptFqBand_D_Rq 3 "NotUsed_1" 2 "Band_2" 1 "Band_1" 0 "Null" ;
VAL_ 290 WifiHtsptTrial_D_RqDrv 3 "NotUsed_1" 2 "StopReminders" 1 "RemindMeLater" 0 "Null" ;
VAL_ 290 WifiHtsptEnbl_D_Rq 3 "Not used" 2 "On" 1 "Off" 0 "Null" ;
VAL_ 290 WifiRemoveDevc_D_Rq 3 "NotUsed_1" 2 "FromBlockedList" 1 "FromConnectedList" 0 "Null" ;
VAL_ 290 WifiHtsptVisbl_D_Rq 3 "Not used" 2 "On" 1 "Off" 0 "Null" ;
VAL_ 290 WifiHtsptMacAddr_B_Rq 1 "Request" 0 "No request" ;
VAL_ 290 WifiDevcList_D_Rq 3 "NoEntry" 2 "BlockedList" 1 "ConnectedList" 0 "Null" ;
VAL_ 290 WifiDataUsage_D_Rq 3 "RetriveDataFromBackend" 2 "RefreshData" 1 "CurrentData" 0 "Null" ;
VAL_ 290 WifiCarrierInfo_B_Rq 1 "Request" 0 "No  request" ;
VAL_ 290 WifiHtsptScrty_D_Rq 3 "NotUsed_1" 2 "Wapi" 1 "Wpa2_Wpa" 0 "Null" ;
VAL_ 554 SeatOccRearMsgTxt_B_Rq 1 "Active" 0 "Null" ;
VAL_ 554 Frt_Btn_Status_1st_2 63 "NotUsed_5" 62 "NotUsed_4" 61 "NotUsed_3" 60 "NotUsed_2" 59 "NotUsed_1" 58 "AUTO_Dec_Pressed" 57 "AUTO_Inc_Pressed" 56 "AUTO_Hi_Pressed" 55 "AUTO_Med_Pressed" 54 "AUTO_Lo_Pressed" 53 "RHS_Cld_Seat3_Pressed" 52 "RHS_Cld_Seat2_Pressed" 51 "RHS_Cld_Seat1_Pressed" 50 "LHS_Cld_Seat3_Pressed" 49 "LHS_Cld_Seat2_Pressed" 48 "LHS_Cld_Seat1_Pressed" 47 "RHS_Auto_Seat_Pressed" 46 "RHS_Htd_Seat3_Pressed" 45 "RHS_Htd_Seat2_Pressed" 44 "RHS_Htd_Seat1_Pressed" 43 "RHS_Seat_Off_Pressed" 42 "LHS_Auto_Seat_Pressed" 41 "LHS_Htd_Seat3_Pressed" 40 "LHS_Htd_Seat2_Pressed" 39 "LHS_Htd_Seat1_Pressed" 38 "LHS_Seat_Off_Pressed" 37 "DrvrFcsdMde_Pressed" 36 "MdeMnu_Pressed" 35 "AAR_Pressed" 34 "Heat_Pressed" 33 "RearMnu_Pressed" 32 "FrontMnu_Pressed" 31 "Defrost_Pressed" 30 "Htd_Strg_Whl_Pressed" 29 "RHS_Cld_Seat_Pressed" 28 "LHS_Cld_Seat_Pressed" 27 "RHS_Htd_Seat_Pressed" 26 "LHS_Htd_Seat_Pressed" 25 "Max_Defrost_Pressed" 24 "My_Temp_Pressed" 23 "Front_Defrost_Pressed" 22 "Rear_Defrost_Pressed" 21 "Pnl_Flr_Ws_Pressed" 20 "Pnl_Ws_Pressed" 19 "Windscreen_Pressed" 18 "Htd_Frt_Wsh_Pressed" 17 "Auto_Recirc_Pressed" 16 "Outside_Pressed" 15 "Recirc_Pressed" 14 "Max_AC_Pressed" 13 "AUTO_Pressed" 12 "Blwr_Dec_Pressed" 11 "Blwr_Inc_Pressed" 10 "RHS_Temp_Dec_Pressed" 9 "RHS_Temp_Inc_Pressed" 8 "LHS_Temp_Dec_Pressed" 7 "LHS_Temp_Inc_Pressed" 6 "Dual_Pressed" 5 "AC_Pressed" 4 "Floor_Ws_Pressed" 3 "Floor_Pressed" 2 "Panel_Floor_Pressed" 1 "Panel_Pressed" 0 "None_Pressed" ;
VAL_ 554 Drv_Set_Tmp2 31 "HI" 30 "29_5" 29 "29_0" 28 "28_5" 27 "28_0" 26 "27_5" 25 "27_0" 24 "26_5" 23 "26_0" 22 "25_5" 21 "25_0" 20 "24_5" 19 "24_0" 18 "23_5" 17 "23_0" 16 "22_5" 15 "22_0" 14 "21_5" 13 "21_0" 12 "20_5" 11 "20_0" 10 "19_5" 9 "19_0" 8 "18_5" 7 "18_0" 6 "17_5" 5 "17_0" 4 "16_5" 3 "16_0" 2 "15_5" 1 "LO" 0 "No_Request" ;
VAL_ 554 DrvHazrdModel_D_St 15 "NotUsed_13" 14 "NotUsed_12" 13 "NotUsed_11" 12 "NotUsed_10" 11 "NotUsed_9" 10 "NotUsed_8" 9 "NotUsed_7" 8 "NotUsed_6" 7 "NotUsed_5" 6 "NotUsed_4" 5 "NotUsed_3" 4 "NotUsed_2" 3 "NotUsed_1" 2 "TpegTec" 1 "DenmEm" 0 "None" ;
VAL_ 554 DrvHazrd_D_St 7 "NotUsed_1" 6 "Suspended" 5 "Available" 4 "NoService" 3 "NoSession" 2 "bAllowOff" 1 "bSAllowOff" 0 "NoStatus" ;
VAL_ 554 PtWakeupActv1_B_Rq 1 "Wake_up_Powertrain_via_HW" 0 "Don_t_Wake_Up_Powertrain" ;
VAL_ 419 MK_SpeedValue_Rq 31 "mph90" 30 "mph85" 29 "mph80" 28 "mph75" 27 "mph70" 26 "mph65" 25 "mph60" 24 "mph55" 23 "mph50" 22 "mph45" 21 "mph40" 20 "Kmh165" 19 "Kmh160" 18 "Kmh155" 17 "Kmh150" 16 "Kmh145" 15 "Kmh140" 14 "Kmh135" 13 "Kmh130" 12 "Kmh125" 11 "Kmh120" 10 "Kmh115" 9 "Kmh110" 8 "Kmh105" 7 "Kmh100" 6 "kmh95" 5 "kmh90" 4 "kmh85" 3 "kmh80" 2 "kmh75" 1 "kmh70" 0 "Off" ;
VAL_ 419 MK_SpeedSetting_Rq 15 "Reserved_last" 3 "Reserved" 2 "SpeedMinder" 1 "SpeedLimit" 0 "Inactive" ;
VAL_ 419 MK_ResetAllUserKeys_Rq 1 "ResetAllKeys" 0 "Inactive" ;
VAL_ 419 MK_MyKeySystemInfo_Rq 1 "GetData" 0 "Inactive" ;
VAL_ 419 MK_ESCRestrictConf_Rq 2 "On" 1 "Off" 0 "Inactive" ;
VAL_ 419 MK_ECalRestrictConf_Rq 2 "On" 1 "Off" 0 "Inactive" ;
VAL_ 419 MK_DNDRestrictConf_Rq 2 "On" 1 "Off" 0 "Inactive" ;
VAL_ 419 MK_CreateMyKey_Rq 1 "Create" 0 "Inactive" ;
VAL_ 419 MK_AudioLimitConfig_Rq 2 "On" 1 "Off" 0 "Inactive" ;
VAL_ 419 MK_ACSRestrictConf_Rq 2 "On" 1 "Off" 0 "Inactive" ;
VAL_ 413 LBS1_ListStatus 0 "Inactive" 1 "Valid" 2 "Updating" 3 "Reserved" ;
VAL_ 898 VedsPrmDirOfF_An_Ltchd 255 "Faulty" 254 "Not Supported" 0 "No Event" ;
VAL_ 898 VedsRoll_An_Ltchd 8191 "Faulty" 8190 "Not Supported" 0 "No Event" ;
VAL_ 898 SecondRowBcklPsngrMid 3 "Unknown" 2 "Unbelted" 1 "Belted" 0 "Faulty" ;
VAL_ 898 SecondRowBuckleDrvMid 3 "Unknown" 2 "Unbelted" 1 "Belted" 0 "Faulty" ;
VAL_ 898 FourthRowBucklePsngr 3 "Unknown" 2 "Unbelted" 1 "Belted" 0 "Faulty" ;
VAL_ 898 FourthRowBuckleMid 3 "Unknown" 2 "Unbelted" 1 "Belted" 0 "Faulty" ;
VAL_ 898 FourthRowBuckleDriver 3 "Unknown" 2 "Unbelted" 1 "Belted" 0 "Faulty" ;
VAL_ 898 Row3PsngrPrsnc_D_Actl 3 "Unknown" 2 "Empty" 1 "Occupied" 0 "Fault" ;
VAL_ 898 Row3MidPrsnc_D_Actl 3 "Unknown" 2 "Empty" 1 "Occupied" 0 "Fault" ;
VAL_ 898 Row3DrvPrsnc_D_Actl 3 "Unknown" 2 "Empty" 1 "Occupied" 0 "Fault" ;
VAL_ 898 Row2PsngrPrsnc_D_Actl 3 "Unknown" 2 "Empty" 1 "Occupied" 0 "Fault" ;
VAL_ 898 Row2MidPrsnc_D_Actl 3 "Unknown" 2 "Empty" 1 "Occupied" 0 "Fault" ;
VAL_ 898 Row2DrvPrsnc_D_Actl 3 "Unknown" 2 "Empty" 1 "Occupied" 0 "Fault" ;
VAL_ 1020 CtrStkPersIndex2_D_Actl 7 "Unused_3" 6 "Unused_2" 5 "Unused_1" 4 "Vehicle" 3 "PERS_4" 2 "PERS_3" 1 "PERS_2" 0 "PERS_1" ;
VAL_ 1020 CtrStkDsplyOp2_D_Rq 7 "Unused_2" 6 "Unused_1" 5 "Copy" 4 "Restore" 3 "Upload" 2 "Set" 1 "Query" 0 "Null" ;
VAL_ 1007 PersIndexIpc2_D_Actl 7 "Unused_3" 6 "Unused_2" 5 "Unused_1" 4 "Vehicle" 3 "PERS_4" 2 "PERS_3" 1 "PERS_2" 0 "PERS_1" ;
VAL_ 1217 UnlckSrcRr_D_Stat 3 "InnerHandle" 2 "RearInteriorSwitch" 1 "IpSwitch" 0 "Null" ;
VAL_ 1217 SldrrStat_B_Actl 1 "Ajar" 0 "Closed" ;
VAL_ 1217 SldrrMsgTxt_D2_Rq 7 "NotUsed_3" 6 "NotUsed_2" 5 "NotUsed_1" 4 "SlidingDrCalibNeeded2" 3 "SlidingDrOpenCltchReleased" 2 "SlidingDrCalibNeeded" 1 "SlidingDrClutchReleased" 0 "Null" ;
VAL_ 1217 SldrrChime_D_Rq 7 "NotUsed3" 6 "NotUsed2" 5 "NotUsed1" 4 "Warning" 3 "WarningRepeated" 2 "Programming" 1 "Operation" 0 "Off" ;
VAL_ 1217 PwStepRight_D_Rq 1 "Deploy" 0 "Null" 3 "NotUsed" 2 "Stow" ;
VAL_ 1217 SldrrUnlckSwtch_D_Stat 3 "InnerHandle" 2 "RearInteriorSwitch" 1 "IpSwitch" 0 "Null" ;
VAL_ 1217 Sldrr_D_Stat 3 "NotCalibrated" 2 "Closing" 1 "Opening" 0 "NotMoving" ;
VAL_ 1216 UnlckSrcRl_D_Stat 3 "InnerHandle" 2 "RearInteriorSwitch" 1 "IpSwitch" 0 "Null" ;
VAL_ 1216 SldrlStat_B_Actl 1 "Ajar" 0 "Closed" ;
VAL_ 1216 SldrlMsgTxt_D2_Rq 7 "NotUsed_3" 6 "NotUsed_2" 5 "NotUsed_1" 4 "SlidingDrCalibNeeded2" 3 "SlidingDrOpenCltchReleased" 2 "SlidingDrCalibNeeded" 1 "SlidingDrClutchReleased" 0 "Null" ;
VAL_ 1216 SldrlChime_D_Rq 7 "NotUsed3" 6 "NotUsed2" 5 "NotUsed1" 4 "Warning" 3 "WarningRepeated" 2 "Programming" 1 "Operation" 0 "Off" ;
VAL_ 1216 PwStepLeft_D_Rq 1 "Deploy" 0 "Null" 3 "NotUsed" 2 "Stow" ;
VAL_ 1216 SldrlUnlckSwtch_D_Stat 3 "InnerHandle" 2 "RearInteriorSwitch" 1 "IpSwitch" 0 "Null" ;
VAL_ 1216 Sldrl_D_Stat 3 "NotCalibrated" 2 "Closing" 1 "Opening" 0 "NotMoving" ;
VAL_ 820 TailLghtAnmtn_D_Stat 15 "Faulty" 14 "NotUsed_8" 13 "NotUsed_7" 12 "NotUsed_6" 11 "NotUsed_5" 10 "NotUsed_4" 9 "NotUsed_3" 8 "NotUsed_2" 7 "NotUsed_1" 6 "Type6" 5 "Type5" 4 "Type4" 3 "Type3" 2 "Type2" 1 "Type1" 0 "Null" ;
VAL_ 820 AhbStatGfhbFdbk_D_Actl 3 "GfhbHighBeamFullyOn" 2 "GfhbHighBeamPartlyOn" 1 "GfhbHighBeamOff" 0 "GfhbUnavailable" ;
VAL_ 820 TurnLampFrOut_B_Stat 1 "Out" 0 "Null" ;
VAL_ 820 TurnLampFlOut_B_Stat 1 "Out" 0 "Null" ;
VAL_ 820 HeadLghtDrvSide_B_Stat 1 "Left_Hand_Traffic" 0 "Right_Hand_Traffic" ;
VAL_ 820 HeadLghtHiOn_B_StatHcm 1 "On" 0 "Off" ;
VAL_ 820 Adaptive_Hdlmp_Fault 1 "Yes" 0 "No" ;
VAL_ 1247 TrlrBrkCtl3_B_Falt 1 "True" 0 "False" ;
VAL_ 1247 StopLamp_B_RqTrlrAft 1 "True" 0 "False" ;
VAL_ 677 SeatFnPsgr_D_Rq3 7 "CushionMassage" 6 "LumbarMassage" 5 "UpperBolster" 4 "LowerBolster" 3 "UpperLumbar" 2 "MiddleLumbar" 1 "LowerLumbar" 0 "Null" ;
VAL_ 677 SeatFnDrv_D_Rq3 7 "CushionMassage" 6 "LumbarMassage" 5 "UpperBolster" 4 "LowerBolster" 3 "UpperLumbar" 2 "MiddleLumbar" 1 "LowerLumbar" 0 "Null" ;
VAL_ 677 SeatMasgPsngrRr_D_Rq2 15 "NotUsed_10" 14 "NotUsed_9" 13 "NotUsed_8" 12 "NotUsed_7" 11 "NotUsed_6" 10 "Pattern10" 9 "Pattern9" 8 "Pattern8" 7 "Pattern7" 6 "Pattern6" 5 "Pattern5" 4 "Pattern4" 3 "Pattern3" 2 "Pattern2" 1 "Pattern1" 0 "Null" ;
VAL_ 677 SeatMasgDrvRr_D_Rq2 15 "NotUsed_10" 14 "NotUsed_9" 13 "NotUsed_8" 12 "NotUsed_7" 11 "NotUsed_6" 10 "Pattern10" 9 "Pattern9" 8 "Pattern8" 7 "Pattern7" 6 "Pattern6" 5 "Pattern5" 4 "Pattern4" 3 "Pattern3" 2 "Pattern2" 1 "Pattern1" 0 "Null" ;
VAL_ 677 SeatFnChngPsgr2_D_Rq3 15 "Faulty" 14 "NotUsed9" 13 "NotUsed8" 12 "NotUsed7" 11 "NotUsed6" 10 "High_2" 9 "Med_2" 8 "Low_2" 7 "Off_2" 6 "High" 5 "Low" 4 "Off" 3 "Decrease" 2 "Increase" 1 "NotUsed1" 0 "Inactive" ;
VAL_ 677 SeatFnChngDrv2_D_Rq3 15 "Faulty" 14 "NotUsed9" 13 "NotUsed8" 12 "NotUsed7" 11 "NotUsed6" 10 "High_2" 9 "Med_2" 8 "Low_2" 7 "Off_2" 6 "High" 5 "Low" 4 "Off" 3 "Decrease" 2 "Increase" 1 "NotUsed1" 0 "Inactive" ;
VAL_ 582 PtLatchActv_B_RqBcm 1 "On" 0 "Off" ;
VAL_ 582 immoSecureIdleMode 3 "NotUsed2" 2 "NotUsed1" 1 "Active" 0 "Inactive" ;
VAL_ 582 ReFuelSwtchStat_D_Actl 3 "NotUsed2" 2 "NotUsed1" 1 "On" 0 "Off" ;
VAL_ 582 FuelPumpPwr_D_Stat 7 "NotUsed3" 6 "NotUsed2" 5 "NotUsed1" 4 "Power_Off_Default" 3 "Power_Off_Command" 2 "Power_Off_Service" 1 "Power_Off_Impact" 0 "Power_On" ;
VAL_ 582 BattULo_U_Actl 255 "Fault" ;
VAL_ 582 PrkLckCtl_B_Enbl 1 "Enable" 0 "Disable" ;
VAL_ 582 PrkLckCtlMsgTxt_D_Rq 3 "BTSI_DI_3" 2 "BTSI_DI_2" 1 "BTSI_DI_1" 0 "Null_BTSI_DI" ;
VAL_ 582 BrkTrnShifLck_B_Stat 1 "Shift" 0 "NoShift" ;
VAL_ 582 PrkLckCtlUnlck_D_Stat 3 "Trans_And_Steer_Unlckd" 2 "Steering_Unlckd" 1 "Transmission_Unlckd" 0 "Null" ;
VAL_ 582 PrkLckCtlTow_B_Enbl 1 "Enable" 0 "Disable" ;
VAL_ 582 DriverCrankingReq 1 "Crank_Request" 0 "No_Crank_Request" ;
VAL_ 582 EngOff_T_Actl 65535 "Invalid" ;
VAL_ 582 DcacElPw_D_Rq 3 "NotUsed" 2 "AC_HighPower_Requested" 1 "AC_LowPower_Requested" 0 "AC_Power_NotRequested" ;
VAL_ 582 BattULo_I_Actl 16383 "Fault" ;
VAL_ 1036 PdstrnAlrt_B_Falt 1 "Yes" 0 "No" ;
VAL_ 1047 TrlrAidSetup_D2_Stat 7 "NotUsed_2" 6 "NotUsed_1" 5 "SetupAcquisitionSuccess" 4 "TbaTadMonitor" 3 "SetupStartAcquisition" 2 "SetupPrepForAcquisition" 1 "TbaActive" 0 "Null" ;
VAL_ 1047 TrlrAidEnbl_D2_Stat 7 "NotUsed_1" 6 "TbaActiveExpertActive" 5 "TbaActiveExpertAvail" 4 "TbaOffTrgActive" 3 "TbaOffTrgSetup" 2 "TbaSetup" 1 "TbaActive" 0 "Inactive" ;
VAL_ 1047 TrlrAidMsgTxt_D2_Rq 63 "Message63" 62 "Message62" 61 "Message61" 60 "Message60" 55 "Message55" 50 "Message50" 45 "Message45" 40 "Message40" 35 "Message35" 31 "Message31" 30 "Message30" 29 "Message29" 28 "Message28" 27 "Message27" 26 "Message26" 25 "Message25" 24 "Message24" 23 "Message23" 22 "Message22" 21 "Message21" 20 "Message20" 19 "Message19" 18 "Message18" 17 "Message17" 16 "Message16" 15 "Message15" 14 "Message14" 13 "Message13" 12 "Message12" 11 "Message11" 10 "Message10" 9 "Message9" 8 "Message8" 7 "Message7" 6 "Message6" 5 "Message5" 4 "Message4" 3 "Message3" 2 "Message2" 1 "Message1" 0 "NoMessage" ;
VAL_ 1047 EsaOn_B_Stat 1 "On" 0 "Off" ;
VAL_ 1047 SelDrvMdeSte_D_Stat 0 "NotAvailable" 1 "Available" 2 "TemporarilyNotAvailable" 3 "Faulty" ;
VAL_ 1236 ApaSlotRight3_D_Stat 7 "NotUsed_3" 6 "NotUsed_2" 5 "NotUsed_1" 4 "IPeReady" 3 "IPeFound" 2 "IPaReady" 1 "IPaFound" 0 "None" ;
VAL_ 1236 ApaSlotRight3_B_Altr 1 "Available" 0 "NotAvailable" ;
VAL_ 1236 ApaSlotRight2_D_Stat 7 "NotUsed_3" 6 "NotUsed_2" 5 "NotUsed_1" 4 "IPeReady" 3 "IPeFound" 2 "IPaReady" 1 "IPaFound" 0 "None" ;
VAL_ 1236 ApaSlotRight2_B_Altr 1 "Available" 0 "NotAvailable" ;
VAL_ 1236 ApaSlotRight1_D_Stat 7 "NotUsed_3" 6 "NotUsed_2" 5 "NotUsed_1" 4 "IPeReady" 3 "IPeFound" 2 "IPaReady" 1 "IPaFound" 0 "None" ;
VAL_ 1236 ApaSlotRight1_B_Altr 1 "Available" 0 "NotAvailable" ;
VAL_ 1236 ApaSlotRear_D_Stat 1 "True" 0 "False" ;
VAL_ 1235 ApaSlotFront_D_Stat 1 "True" 0 "False" ;
VAL_ 1235 ApaSlotLeft3_D_Stat 7 "NotUsed_3" 6 "NotUsed_2" 5 "NotUsed_1" 4 "IPeReady" 3 "IPeFound" 2 "IPaReady" 1 "IPaFound" 0 "None" ;
VAL_ 1235 ApaSlotLeft3_B_Altr 1 "Available" 0 "NotAvailable" ;
VAL_ 1235 ApaSlotLeft2_D_Stat 7 "NotUsed_3" 6 "NotUsed_2" 5 "NotUsed_1" 4 "IPeReady" 3 "IPeFound" 2 "IPaReady" 1 "IPaFound" 0 "None" ;
VAL_ 1235 ApaSlotLeft2_B_Altr 1 "Unavailable" 0 "Available" ;
VAL_ 1235 ApaSlotLeft1_D_Stat 7 "NotUsed_3" 6 "NotUsed_2" 5 "NotUsed_1" 4 "IPeReady" 3 "IPeFound" 2 "IPaReady" 1 "IPaFound" 0 "None" ;
VAL_ 1235 ApaSlotLeft1_B_Altr 1 "Unavailable" 0 "Available" ;
VAL_ 841 FohAddHeater_D_Stat 3 "NotUsed" 2 "On" 1 "Off" 0 "NoModeSelected" ;
VAL_ 1189 SeatDfaltPosFront_B_Stat 1 "Yes" 0 "No" ;
VAL_ 1189 PwStepMsgTxt_D_Rq 1 "DriveInhibited" 0 "NoMessage" 3 "NotUsed" 2 "Malfunction" ;
VAL_ 1189 Running_Board_Stat 3 "Unused" 2 "Manually_Deployed" 1 "All_Enabled" 0 "All_Disabled" ;
VAL_ 1189 PwStep_D_Stat 3 "PositionNotKnown" 2 "StepsNotStowed" 1 "StepsStowed" 0 "Off" ;
VAL_ 772 SeatRelxPosDact_B_Stat 1 "Success" 0 "Fail" ;
VAL_ 772 SeatRelxPosActv_B_Stat 1 "Success" 0 "Fail" ;
VAL_ 772 SeatRelxPosSet_B_Stat 1 "Success" 0 "Fail" ;
VAL_ 772 SeatScrnDrvOn_B_Rq 1 "On" 0 "Off" ;
VAL_ 772 PwRnngBoardT_D_Stat 3 "NotUsed" 2 "Timer2" 1 "Timer1" 0 "Inactive" ;
VAL_ 772 PwRnngBoardSwtch_D_Stat 3 "NotUsed" 2 "DeployUnlocked" 1 "AlwaysActive" 0 "Inactive" ;
VAL_ 772 SeatSlprPosPsngr_D_Stat 3 "Faulty" 2 "Sleeper" 1 "Upright" 0 "Null" ;
VAL_ 772 SeatSlprPosMsgTxt_B_Rq 1 "On" 0 "Off" ;
VAL_ 772 SeatPos_D_Stat 7 "NotUsed3" 6 "NotUsed2" 5 "Error" 4 "Drive" 3 "Moving" 2 "Pending" 1 "EasyEntry" 0 "Null" ;
VAL_ 772 MemDrvDeny_B_Stat 1 "Yes" 0 "No" ;
VAL_ 772 Memory_Feedback_Rqst 1 "Yes" 0 "No" ;
VAL_ 772 Easy_Entry_Rqst 2 "Easy_Entry" 1 "Drive" 0 "Null" ;
VAL_ 772 Memory_Cmd 7 "Recall_3" 4 "Store_4" 3 "Store_3" 6 "Recall_2" 5 "Recall_1" 2 "Store_2" 1 "Store_1" 0 "Null" 8 "Recall_4" ;
VAL_ 772 Cancel_Auto_Movement 1 "Cancel" 0 "Null" ;
VAL_ 1054 SelDrvMdeChassis3_D_Rq 31 "Faulty" 30 "NotUsed17" 29 "NotUsed16" 28 "NotUsed15" 27 "NotUsed14" 26 "NotUsed13" 25 "NotUsed12" 24 "NotUsed11" 23 "NotUsed10" 22 "NotUsed9" 21 "NotUsed8" 20 "NotUsed7" 19 "NotUsed6" 18 "NotUsed5" 17 "NotUsed4" 16 "OnePedalDrive" 15 "DragMode" 14 "RoughRoadMode" 13 "TrackMode" 12 "HighSpeedDesertMode" 11 "TowHaulMode" 10 "RockCrawlMode" 9 "SandMode" 8 "MudAndRutsMode" 7 "LowMuMode" 6 "ComfortAdaptiveMode" 5 "ComfortMode" 4 "SportAdaptiveMode" 3 "SportMode" 2 "EconomyMode" 1 "NormalAdaptiveMode" 0 "NormalMode" ;
VAL_ 1054 RbaBrk_D_Stat 3 "Denied" 2 "Active" 1 "Open" 0 "Closed" ;
VAL_ 1054 SelDrvMdeChassis2_D_Rq 31 "Faulty" 30 "NotUsed17" 29 "NotUsed16" 28 "NotUsed15" 27 "NotUsed14" 26 "NotUsed13" 25 "NotUsed12" 24 "NotUsed11" 23 "NotUsed10" 22 "NotUsed9" 21 "NotUsed8" 20 "NotUsed7" 19 "NotUsed6" 18 "NotUsed5" 17 "NotUsed4" 16 "OnePedalDrive" 15 "DragMode" 14 "RoughRoadMode" 13 "TrackMode" 12 "HighSpeedDesertMode" 11 "TowHaulMode" 10 "RockCrawlMode" 9 "SandMode" 8 "MudAndRutsMode" 7 "LowMuMode" 6 "ComfortAdaptiveMode" 5 "ComfortMode" 4 "SportAdaptiveMode" 3 "SportMode" 2 "EconomyMode" 1 "NormalAdaptiveMode" 0 "NormalMode" ;
VAL_ 1054 BrkBstrLoLampOn_B_Rq 1 "On" 0 "Off" ;
VAL_ 1054 TrailCtl_D_Stat 7 "Faulty" 6 "DescentOnly" 5 "EnabledDeny" 4 "StandbyOverThreshold" 3 "StandbyOverride" 2 "Active" 1 "EnabledDescent" 0 "Off" ;
VAL_ 1054 TrailCtlMsgTxt_D_Rq 15 "Message15" 14 "Message14" 13 "Message13" 12 "Message12" 11 "Message11" 10 "Message10" 9 "Message9" 8 "Message8" 7 "Message7" 6 "Message6" 5 "Message5" 4 "Message4" 3 "Message3" 2 "Message2" 1 "Message1" 0 "NoMessage" ;
VAL_ 1054 BrkPadMsgTxt_D_Rq 3 "Faulty" 2 "PadsOk" 1 "ReplacePads" 0 "Null" ;
VAL_ 1054 BrkBstrVac_D_Stat 3 "NotUsed" 2 "BoosterVacEstimator" 1 "BoosterVacSensor" 0 "NoBoosterVacuumMonitor" ;
VAL_ 1054 DrvSlipCtlOffLamp_D_Rq 3 "Fast_Flash" 2 "Slow_Flash" 1 "On" 0 "Off" ;
VAL_ 1054 DrvSlipCtlMdeMsg_D_Rq 31 "Message31" 30 "Message30" 29 "Message29" 28 "Message28" 27 "Message27" 26 "Message26" 25 "Message25" 24 "Message24" 23 "Message23" 22 "Message22" 21 "Message21" 20 "Message20" 19 "Message19" 18 "Message18" 17 "Message17" 16 "Message16" 15 "Message15" 14 "Message14" 13 "Message13" 12 "Message12" 11 "Message11" 10 "Message10" 9 "Message9" 8 "Message8" 7 "Message7" 6 "Message6" 5 "Message5" 4 "Message4" 3 "Message3" 2 "Message2" 1 "Message1" 0 "NoMessage" ;
VAL_ 1054 HdcOn_B_Ind 1 "On" 0 "Off" ;
VAL_ 1054 AutoHoldMsgTxt_D_Rq 15 "Message15" 14 "Message14" 13 "Message13" 12 "Message12" 11 "Message11" 10 "Message10" 9 "Message9" 8 "Message8" 7 "Message7" 6 "Message6" 5 "Message5" 4 "Message4" 3 "Message3" 2 "Message2" 1 "Message1" 0 "NoMessage" ;
VAL_ 1054 CtaBrk_D_Stat 3 "Denied" 2 "Active" 1 "Open" 0 "Closed" ;
VAL_ 1054 SelDrvMdeAwd_D_Rq 31 "Faulty" 30 "NotUsed_17" 29 "NotUsed_16" 28 "NotUsed_15" 27 "NotUsed_14" 26 "NotUsed_13" 25 "NotUsed_12" 24 "NotUsed_11" 23 "NotUsed_10" 22 "NotUsed_9" 21 "NotUsed_8" 20 "CustomMode" 19 "OnePedalDrive" 18 "DragMode" 17 "EvLaterChargeMode" 16 "EvNowMode" 15 "TrackMode" 14 "RoughRoadMode" 13 "NotAvailable" 12 "HighSpeedDesertMode_Baja" 11 "SportAdaptiveMode" 10 "RockCrawlMode" 9 "MudRutsMode" 8 "SandMode" 7 "EconomyMode" 6 "GrassGravelSnow" 5 "TowHaulMode" 4 "SportMode" 3 "Normal_4L" 2 "Normal_4A" 1 "Normal_2H" 0 "NormalMode" ;
VAL_ 1054 AutoHoldSwMde_B_Ind 1 "On" 0 "Off" ;
VAL_ 1054 AutoHoldMde_D_Ind 3 "Indication_3" 2 "Indication_2" 1 "Indication_1" 0 "Off" ;
VAL_ 1054 BrkMdeInhbt_B_RqDsply 1 "Yes" 0 "No" ;
VAL_ 1054 BrkLineLck_D_Stat 7 "NotUsed_3" 6 "NotUsed_2" 5 "NotUsed_1" 4 "NotAvailable" 3 "Off" 2 "Engaged" 1 "Initiated" 0 "Available" ;
VAL_ 1054 SelDrvMdeChassis_D_Rq 31 "Faulty" 30 "NotUsed17" 29 "NotUsed16" 28 "NotUsed15" 27 "NotUsed14" 26 "NotUsed13" 25 "NotUsed12" 24 "NotUsed11" 23 "NotUsed10" 22 "NotUsed9" 21 "NotUsed8" 20 "NotUsed7" 19 "NotUsed6" 18 "NotUsed5" 17 "NotUsed4" 16 "OnePedalDrive" 15 "DragMode" 14 "RoughRoadMode" 13 "TrackMode" 12 "HighSpeedDesertMode" 11 "TowHaulMode" 10 "RockCrawlMode" 9 "SandMode" 8 "MudAndRutsMode" 7 "LowMuMode" 6 "ComfortAdaptiveMode" 5 "ComfortMode" 4 "SportAdaptiveMode" 3 "SportMode" 2 "EconomyMode" 1 "NormalAdaptiveMode" 0 "NormalMode" ;
VAL_ 1054 ApaBrk_D_Stat 3 "Denied" 2 "Active" 1 "Open" 0 "Closed" ;
VAL_ 1054 FrontDiffElckrOpen_B_Rq 1 "Yes" 0 "No" ;
VAL_ 1054 OnePdlDrvDeny_B_Stat 1 "Yes" 0 "No" ;
VAL_ 1054 BrkDrvMde_D_Stat 7 "Faulty" 6 "RockCrawl" 5 "Baja" 4 "DragOrMudAndSand" 3 "Track" 2 "Snow_Wet" 1 "Sport" 0 "Normal" ;
VAL_ 1054 TrailOnePdlTqLm_B_Actl 1 "Yes" 0 "No" ;
VAL_ 572 BattTracClnt_Te_Actl 255 "Faulty" 254 "NoDataExists" ;
VAL_ 572 PwSrcULoMde_D_Actl 3 "BuckSpecial" 2 "ReverseBoost" 1 "ForwardBuck" 0 "Standby" ;
VAL_ 572 BattTracWarnLamp_B_Rq 1 "On" 0 "Off" ;
VAL_ 572 BattTracSrvcRqd_B_Rq 1 "On" 0 "Off" ;
VAL_ 561 TrnMsgTxt2_D_Rq 7 "NotUsed3" 6 "NotUsed2" 5 "NotUsed1" 4 "TransTooHot_LoudChime" 3 "PressBrake_LoudChime" 2 "PressBrake_SoftChime" 1 "PressBrake_NoChime" 0 "NoText_NoChime" ;
VAL_ 561 TrnMsgTxt_D_Rq 15 "Message_15" 14 "Message_14" 13 "Message_13" 12 "Message_12" 11 "Message_11" 10 "Message_10" 9 "Message_9" 8 "Message_8" 7 "Message_7" 6 "Message_6" 5 "Message_5" 4 "Message_4" 3 "Message_3" 2 "Message_2" 1 "Message_1" 0 "NoMessage" ;
VAL_ 602 HtrnWarnLamp_B_Dsply 1 "On" 0 "Off" ;
VAL_ 602 HybPwLimOn_B_Stat 1 "Yes" 0 "No" ;
VAL_ 602 PwSrcULoMde_D_Rq 3 "BuckSpecial" 2 "ReverseBoost" 1 "ForwardBuck" 0 "Standby" ;
VAL_ 602 PtcHtrRun_B_Rq 1 "On" 0 "Off" ;
VAL_ 602 PwPckTqRdy_B_Dsply 1 "On" 0 "Off" ;
VAL_ 602 ObdEngStdy_B_Stat 1 "Yes" 0 "No" ;
VAL_ 602 EngStrtSrvc_B_Allw 1 "Yes" 0 "No" ;
VAL_ 602 BattTracRsrvSoc_Pc_Rq 16383 "Faulty" 16382 "NoDataExists" ;
VAL_ 92 TrnGearMsgTxt2_D_Rq 31 "Message31" 30 "Message30" 29 "Message29" 28 "Message28" 27 "Message27" 26 "Message26" 25 "Message25" 24 "Message24" 23 "Message23" 22 "Message22" 21 "Message21" 20 "Message20" 19 "Message19" 18 "Message18" 17 "Message17" 16 "Message16" 15 "Message15" 14 "Message14" 13 "Message13" 12 "Message12" 11 "Message11" 10 "Message10" 9 "Message9" 8 "Message8" 7 "Message7" 6 "Message6" 5 "Message5" 4 "Message4" 3 "Message3" 2 "Message2" 1 "Message1" 0 "NoMessage" ;
VAL_ 92 RaceTrakMde_D_Stat 3 "NotUsed" 2 "Available" 1 "NotAvailable" 0 "Null" ;
VAL_ 92 TrnLvrV_D_Rq 3 "Full_Speed" 2 "Aggressive" 1 "Normal" 0 "Quiet" ;
VAL_ 92 TrnSbwSysHlth_D_Actl 3 "OK" 2 "Degraded" 1 "No_Data_Exists" 0 "Faulty" ;
VAL_ 92 TrnDtpCmd_D_Actl 7 "NotUsed4" 6 "NotUsed3" 5 "NotUsed2" 4 "Relatch" 3 "Deploy" 2 "Self_Test" 1 "No_Command" 0 "NotUsed1" ;
VAL_ 92 TrnGearNtmAllow_B_Stat 1 "Yes" 0 "No" ;
VAL_ 92 GearSelLck_D_Rq 3 "PreventionBlocker" 2 "Unlock" 1 "Lock" 0 "Null" ;
VAL_ 92 TrnValidGear_D_Cnfm 3 "Accept" 2 "Reject" 1 "Internal_Request" 0 "No_Command" ;
VAL_ 92 TrnNtrlTowCmd_D_Actl 3 "NotUsed" 2 "Neutral_Tow_Entry" 1 "Car_Wash_Mode" 0 "Normal_Mode" ;
VAL_ 92 TrnGearCmd_Pc_ActlPt 1023 "Fault" ;
VAL_ 92 TrnGear_D_RqPt 7 "Fault" 6 "NotUsed" 5 "Manual" 4 "Drive" 3 "Neutral" 2 "Reverse" 1 "Park" 0 "No_Gear" ;
VAL_ 92 TrnCmdState_B_Actl 1 "Yes" 0 "No" ;
VAL_ 92 PrkBrkActv_D_RqTrnGear 3 "NotUsed2" 2 "RequestParkBrakeEngage" 1 "NoRequest" 0 "NotUsed1" ;
VAL_ 92 TrnGearMsgTxt_D_Rq 15 "Message_15" 14 "Message_14" 13 "Message_13" 12 "Message_12" 11 "Message_11" 10 "Message_10" 9 "Message_9" 8 "Message_8" 7 "Message_7" 6 "Message_6" 5 "Message_5" 4 "Message_4" 3 "Message_3" 2 "Message_2" 1 "Message_1" 0 "NoMessage" ;
VAL_ 1156 RngPerChrgAvg_L2_Dsply 8191 "Faulty" 8190 "NoDataExists" ;
VAL_ 1156 VehElEffAvg_No_Dsply 127 "Faulty" 126 "NoDataExists" ;
VAL_ 1156 PwFlwFuelDrv_D_Dsply 7 "NotUsed_4" 6 "NotUsed_3" 5 "NotUsed_2" 4 "NotUsed_1" 3 "FlwFromFuelToAllWhls" 2 "FlwFromFuelToFrontWhls" 1 "FlwFromFuelToRearWhls" 0 "NoFlow" ;
VAL_ 1156 PwFlwFuelClimt_B_Dsply 1 "On" 0 "Off" ;
VAL_ 1156 PwFlwFuelBatt_B_Dsply 1 "On" 0 "Off" ;
VAL_ 1156 PwFlwBattGen_D_Dsply 1 "On" 0 "Off" ;
VAL_ 1156 PwFlwBattClimt_B_Dsply 1 "On" 0 "Off" ;
VAL_ 1156 PwFlwBatt_D_Dsply 15 "NotUsed_8" 14 "NotUsed_7" 13 "NotUsed_6" 12 "NotUsed_5" 11 "NotUsed_4" 10 "NotUsed_3" 9 "NotUsed_2" 8 "NotUsed_1" 7 "FlwFromWallToBatt" 6 "FlwFromAllWhlsToBatt" 5 "FlwFromBattToAllWhls" 4 "FlwFromFrontWhlsToBatt" 3 "FlwFromBattToFrontWhls" 2 "FlwFromRearWhlsToBatt" 1 "FlwFromBattToRearWhls" 0 "NoFlow" ;
VAL_ 357 BPedDrvAppl_D_Qf 3 "OK" 2 "Not_Within_Specifications" 1 "No_Data_Exists" 0 "Faulty" ;
VAL_ 357 CmbbDeny_B_ActlPrpl 1 "Yes" 0 "No" ;
VAL_ 357 PrplTqMnSat_B_Actl 1 "Yes" 0 "No" ;
VAL_ 357 VehStrtStop_D_Rq 3 "NotUsed" 2 "Vehicle_Start_Request" 1 "Vehicle_Stop_Request" 0 "NoRequest" ;
VAL_ 357 BpedDrvAppl_D_Actl 3 "_Not_Allowed" 2 "Driver_Braking" 1 "Driver_Not_Braking" 0 "Not_Allowed" ;
VAL_ 357 CmbbEngTqMn_B_Actl 1 "Yes" 0 "No" ;
VAL_ 357 Veh_V_DsplyCcSet 255 "Fault" 254 "Unknown" ;
VAL_ 357 AccEngStat_D_Actl 7 "Undefined_2" 6 "Undefined_1" 5 "ACCSoonCancel_due_Low_Spd" 4 "Shift_Down_Recommendation" 3 "Shift_Up_Recommendation" 2 "ACCNotAllowedToBeActivated" 1 "ACCStandby_due_Auto_Cancel" 0 "Normal_Operation" ;
VAL_ 357 CcMde_D_Actl 7 "TapDownWaiting" 6 "TapUpWaiting" 5 "Resuming_Low" 4 "Resuming_High" 3 "Decelerating" 2 "Accelerating" 1 "Keeping_Speed" 0 "Not_Active" ;
VAL_ 357 CcStat_D_Actl 7 "Undefined_2" 6 "Undefined_1" 5 "Active" 4 "Active_Que_Assist" 3 "Standby" 2 "Standby_Denied" 1 "Denied" 0 "Off" ;
VAL_ 357 CcOvrrdActv_B_Actl 1 "Cruise_Overridden" 0 "Cruise_Req_Not_Overridden" ;
VAL_ 357 AccStopMde_D_Rq 3 "Stop_Mode_Active" 2 "EPBApplyOrBrakeReleaseWarn" 1 "Limit_Rolling_Speed" 0 "Stop_Mode_Not_Active" ;
VAL_ 1100 RearDiffLckLamp_D_Rq2 3 "Triggered" 2 "Flash" 1 "On" 0 "Off" ;
VAL_ 1100 RvltnMatchAllw_D_Stat 3 "RevolutionMatchDisabled" 2 "RevolutionMatchEnabled" 1 "ChangeWithDriveMode" 0 "NoSelection" ;
VAL_ 1100 WakeAlarm1_B_Typ 1 "CanAndEcuDriveCircuit" 0 "CanOnly" ;
VAL_ 1100 TrnNtrlIdlExit_B_Rq 1 "Active" 0 "Inactive" ;
VAL_ 1100 Veh_V_DsplyTrailCtlSet 63 "Faulty" ;
VAL_ 1100 TrailCtlPt_B_Falt 1 "Fault" 0 "NoFault" ;
VAL_ 1100 TrnNtrlIdlInhbt_B_Rq 1 "Inhibit" 0 "NoInhibit" ;
VAL_ 1100 AutoTowAllw_D_StatMnu 3 "TowHaulCommandedOn" 2 "AutoTowHaulEnabled" 1 "AutoTowHaulDisabled" 0 "NoSelection" ;
VAL_ 1100 AutoTowActv_B_Stat 1 "Yes" 0 "No" ;
VAL_ 1100 SpareTireDetct_B_Stat 1 "True" 0 "False" ;
VAL_ 1100 RearDiffSumpOil_Te_Est 255 "Faulty" 254 "NoDataExists" ;
VAL_ 1100 RearDiffMtrRun_B_Stat 1 "Allowed" 0 "NotAllowed" ;
VAL_ 1100 EngTrlrCnnct_D_Stat 3 "NotUsed_1" 2 "UnverifiedTrailer" 1 "HeavyTrailer" 0 "NoTrailer" ;
VAL_ 1100 GrossTrainWeight_M_Est 255 "Faulty" 254 "NoDataExists" ;
VAL_ 1100 SuspVlimMsgTxt_B_Rq 1 "Yes" 0 "No" ;
VAL_ 1100 RearDiffLckMsg2_D_Rq 15 "NotUsed_3" 14 "NotUsed_2" 13 "NotUsed_1" 12 "ElsdReduced" 11 "LockingFeatureNotAvailable" 10 "EsldOff" 9 "ElsdRestored" 8 "ElsdOverheated" 7 "Locker_Disabled" 6 "Locker_Enabled" 5 "LockerSpeed5" 4 "LockerSpeed4" 3 "LockerSpeed3" 2 "LockerSpeed2" 1 "LockerSpeed1" 0 "NormalNoMessage " ;
VAL_ 1100 EngExhMdeQuiet_D2_Stat 7 "Faulty" 6 "NotUsed_2" 5 "NotUsed_1" 4 "Track" 3 "Sport" 2 "Normal" 1 "Stealth" 0 "Null" ;
VAL_ 1100 HvacCmprLim_D_Stat 7 "NotUsed_2" 6 "NotUsed_1" 5 "CompressorHeadPressure" 4 "AvailableTorque" 3 "PedalPosition" 2 "RPM" 1 "ECT" 0 "NoLimit" ;
VAL_ 1152 PwCabinEnblScnd_B_Rq 1 "Enable" 0 "Disable" ;
VAL_ 1152 PwCabinEnbl_B_Rq 1 "Enable" 0 "Disable" ;
VAL_ 1152 PwTrnkFrntEnblScnd_B_Rq 1 "Enable" 0 "Disable" ;
VAL_ 1152 PwTrnkFrntEnbl_B_Rq 1 "Enable" 0 "Disable" ;
VAL_ 1152 PwOutlet8EnblScnd_B_Rq 1 "Enable" 0 "Disable" ;
VAL_ 1152 PwOutlet8Enbl_B_Rq 1 "Enable" 0 "Disable" ;
VAL_ 1152 PwOutlet7EnblScnd_B_Rq 1 "Enable" 0 "Disable" ;
VAL_ 1152 PwOutlet7Enbl_B_Rq 1 "Enable" 0 "Disable" ;
VAL_ 1152 PwOutlet6EnblScnd_B_Rq 1 "Enable" 0 "Disable" ;
VAL_ 1152 PwOutlet6Enbl_B_Rq 1 "Enable" 0 "Disable" ;
VAL_ 1152 HybPwULoLamp_B_Rq 1 "On" 0 "Off" ;
VAL_ 1152 StopStrtVThres_D_Stat 3 "High" 2 "Medium" 1 "Low" 0 "NoSelection" ;
VAL_ 1152 GrdAsstActv_B_Stat 1 "On" 0 "Off" ;
VAL_ 1152 EngTeHi_B_Actl 1 "EngineTempHigh" 0 "Normal" ;
VAL_ 1152 DcdcOn_B_Rq 1 "On" 0 "Off" ;
VAL_ 1152 ULoBattSpprtSustn_B_Rq 1 "Active" 0 "Inactive" ;
VAL_ 1152 OnePdlDrv_D_Dsply 3 "Faulty" 2 "Suspended" 1 "On" 0 "Off" ;
VAL_ 1152 OnePdlDrvLamp_B_Rq 1 "On" 0 "Off" ;
VAL_ 1152 BattTracDiagClr_B_Stat 1 "On" 0 "Off" ;
VAL_ 1152 VehElEff_No_Avg 127 "Faulty" 126 "NoDataExists" ;
VAL_ 839 FohStop_B_Stat 3 "Unknown" 2 "NotUsed" 1 "Enable" 0 "Disable" ;
VAL_ 839 FohMsgTxt_D_Rq 4 "BatteryNotFullyCharged" 3 "Exceed7DaysFromLastEngRun" 2 "AmbientTemperatureTooHigh" 1 "LowFuel" 0 "NoMessage" ;
VAL_ 839 FohKeyOff_B_Rq 1 "Enable" 0 "Disable" ;
VAL_ 839 FohEnbl_B_Rq 1 "Enable" 0 "Disable" ;
VAL_ 839 FohTAllEnable_B_Stat 3 "Unknown" 2 "NotUsed" 1 "Enable" 0 "Disable" ;
VAL_ 839 FohT2Enable_B_Stat 1 "Enable" 0 "Disable" ;
VAL_ 839 FohT1Enable_B_Stat 1 "Enable" 0 "Disable" ;
VAL_ 839 FohStrtEnable_B_Stat 1 "Enable" 0 "Disable" ;
VAL_ 839 FohContOn_B_Stat 3 "Unknown" 2 "NotUsed" 1 "Enable" 0 "Disable" ;
VAL_ 839 FohStrtDay_T_Stat 7 "Sunday" 6 "Saturday" 5 "Friday" 4 "Thursday" 3 "Wednesday" 2 "Tuesday" 1 "Monday" 0 "NotUsed" ;
VAL_ 839 FohT2Wednesday_T_Stat 1 "Enable" 0 "Disable" ;
VAL_ 839 FohT2Tuesday_T_Stat 1 "Enable" 0 "Disable" ;
VAL_ 839 FohT2Thursday_T_Stat 1 "Enable" 0 "Disable" ;
VAL_ 839 FohT2Sunday_T_Stat 1 "Enable" 0 "Disable" ;
VAL_ 839 FohT2Saturday_T_Stat 1 "Enable" 0 "Disable" ;
VAL_ 839 FohT2Monday_T_Stat 1 "Enable" 0 "Disable" ;
VAL_ 839 FohT2Friday_T_Stat 1 "Enable" 0 "Disable" ;
VAL_ 839 FohT1Wednesday_T_Stat 1 "Enable" 0 "Disable" ;
VAL_ 839 FohT1Tuesday_T_Stat 1 "Enable" 0 "Disable" ;
VAL_ 839 FohT1Thursday_T_Stat 1 "Enable" 0 "Disable" ;
VAL_ 839 FohT1Sunday_T_Stat 1 "Enable" 0 "Disable" ;
VAL_ 839 FohT1Saturday_T_Stat 1 "Enable" 0 "Disable" ;
VAL_ 839 FohT1Monday_T_Stat 1 "Enable" 0 "Disable" ;
VAL_ 839 FohT1Friday_T_Stat 1 "Enable" 0 "Disable" ;
VAL_ 652 TelematicsSrvc_D_St2 7 "NotUsed_1" 6 "NotifyNotActivatedYet" 5 "NotActivatedYet" 4 "NotifyExpired" 3 "Expired" 2 "ExpiringSoon" 1 "Active" 0 "Null" ;
VAL_ 560 BtsiShifInhbt_B_RqTrn 1 "Yes" 0 "No" ;
VAL_ 560 SelDrvMdeSwtch_D_Stat3 3 "Faulty" 2 "SwitchState2" 1 "SwitchState1" 0 "NotPressed" ;
VAL_ 560 TrnGbox_Rt_Actl 65535 "Fault" 65534 "Unknown" ;
VAL_ 560 TrnSrvcRqd_B_Rq 1 "On" 0 "Off" ;
VAL_ 560 TrnCnvtClu_D_Actl 3 "Transition_or_Micro_Slip" 2 "Lock_Up_Fixed" 1 "Lock_Up_Slip" 0 "No_Lock_Up" ;
VAL_ 560 TrnShifActv_B_Actl 1 "Active" 0 "Inactive" ;
VAL_ 560 RtmTerrMdeChng_D_Rdy 7 "Fault" 6 "Undefined_2" 5 "Undefined_1" 4 "ModeUnavailDrInputRqd" 3 "SpOpModes_NotSupported" 2 "ModeUnavailDynamicCond" 1 "Module_In_Initialization" 0 "Mode_Change_Available" ;
VAL_ 560 RtmTerrMde_D_Actl 7 "Fail_Safe_Default" 6 "Dynamic_Mode" 5 "Rock_Crawl_Mode" 4 "Mud_Ruts_Mode" 3 "Sand_Mode" 2 "Undefined" 1 "Low_Mu_Mode" 0 "Special_Operating_Mode_Off" ;
VAL_ 560 GearLvrPos_D_Actl 15 "Fault" 14 "Unknown_Position" 13 "Undefined_Treat_as__Fault" 12 "Undefined_Treat_as_Fault" 11 "sixth" 10 "fifth" 9 "fourth" 8 "third" 7 "second" 6 "first" 5 "Low" 4 "Sport_DriveSport" 3 "Drive" 2 "Neutral" 1 "Reverse" 0 "Park" ;
VAL_ 560 GboxOil_Te_Actl 255 "Faulty" 254 "NoDataExists" ;
VAL_ 1153 TerrStat_D_RqDsply 15 "Reserved4" 14 "Reserved3" 13 "Reserved2" 12 "Crawl_Mode_4LOW_Reqd" 11 "Economy_Mode_Select" 10 "ModeChangeNotAvailable" 9 "Terrain_Sys_Not_Avail" 8 "Terrain_System_Fault" 7 "Mode_Change_InProgress" 6 "Dynamics_Mode_Select" 5 "Rock_Crawl_Mode_Select" 4 "Sand_Mode_Select" 3 "Mud_Ruts_Mode_Select" 2 "Low_Mu_Mode_Select" 1 "Special_Modes_Off" 0 "No_Message" ;
VAL_ 1153 TerrMde_D_RqDrv 7 "Fail_Safe_Default" 6 "Dynamic_Mode" 5 "Rock_Crawl_Mode" 4 "Mud_Ruts_Mode" 3 "Sand_Mode" 2 "Undefined" 1 "Low_Mu_Mode" 0 "Special_Operating_Mode_Off" ;
VAL_ 930 BalrWndwRight_B_Stat 1 "Enable" 0 "Disable" ;
VAL_ 930 BalrSnsRight_D_Falt 3 "Invalid" 2 "SystemFailure" 1 "Blocked" 0 "Clear" ;
VAL_ 930 WndwPsngrRear_D_RqBalrr 3 "NotUsed" 2 "Stop" 1 "AutoUp" 0 "NoRequest" ;
VAL_ 930 WndwPsngr_D_RqBalrr 3 "NotUsed" 2 "Stop" 1 "AutoUp" 0 "NoRequest" ;
VAL_ 930 WndwDrvRear_D_RqBalrr 3 "NotUsed" 2 "Stop" 1 "AutoUp" 0 "NoRequest" ;
VAL_ 930 WndwDrv_D_RqBalrr 3 "NotUsed" 2 "Stop" 1 "AutoUp" 0 "NoRequest" ;
VAL_ 930 BalrRight_D_Stat 3 "Inhibited" 2 "Disabled" 1 "On" 0 "Off" ;
VAL_ 930 BalrMdeSelRight_B_Stat 1 "Enable" 0 "Disable" ;
VAL_ 930 BalrMdeRight_D_Stat 3 "NotUsed" 2 "High" 1 "Medium" 0 "Low" ;
VAL_ 930 BalrLckRight_B_Stat 1 "Enable" 0 "Disable" ;
VAL_ 930 BalrChimeRight_D_Rq 3 "NotUsed" 2 "Soft" 1 "Normal" 0 "Off" ;
VAL_ 930 CamraRearOn_B_RqBalrr 1 "Active" 0 "Inactive" ;
VAL_ 930 DrLckActv_B_RqBalrr 1 "Active" 0 "Null" ;
VAL_ 929 BalrChimeLeft_D_Rq 3 "NotUsed" 2 "Soft" 1 "Normal" 0 "Off" ;
VAL_ 929 BalrLeft_D_Stat 3 "Inhibited" 2 "Disabled" 1 "On" 0 "Off" ;
VAL_ 929 WndwPsngrRear_D_RqBalrl 3 "NotUsed" 2 "Stop" 1 "AutoUp" 0 "NoRequest" ;
VAL_ 929 WndwPsngr_D_RqBalrl 3 "NotUsed" 2 "Stop" 1 "AutoUp" 0 "NoRequest" ;
VAL_ 929 WndwDrvRear_D_RqBalrl 3 "NotUsed" 2 "Stop" 1 "AutoUp" 0 "NoRequest" ;
VAL_ 929 WndwDrv_D_RqBalrl 3 "NotUsed" 2 "Stop" 1 "AutoUp" 0 "NoRequest" ;
VAL_ 929 BalrSnsLeft_D_Falt 3 "Invalid" 2 "SystemFailure" 1 "Blocked" 0 "Clear" ;
VAL_ 929 BalrMdeSelLeft_B_Stat 1 "Enable" 0 "Disable" ;
VAL_ 929 BalrMdeLeft_D_Stat 3 "NotUsed" 2 "High" 1 "Medium" 0 "Low" ;
VAL_ 929 BalrLckLeft_B_Stat 1 "Enable" 0 "Disable" ;
VAL_ 929 CamraRearOn_B_RqBalrl 1 "Active" 0 "Inactive" ;
VAL_ 929 DrLckActv_B_RqBalrl 1 "Active" 0 "Null" ;
VAL_ 929 BalrWndwLeft_B_Stat 1 "Enable" 0 "Disable" ;
VAL_ 391 ACU_CtrlChimeChan_Rq 3 "Reserved2" 2 "Reserved1" 1 "Mute" 0 "Inactive" ;
VAL_ 670 DrHandleOuterRl_D_Stat 7 "NotUsed" 6 "Transition" 5 "FlushFault" 4 "DeployFault2" 3 "DeployFault1" 2 "Flush" 1 "Deploy" 0 "None" ;
VAL_ 670 DrHandleOuterFl_D_Stat 7 "NotUsed" 6 "Transition" 5 "FlushFault" 4 "DeployFault2" 3 "DeployFault1" 2 "Flush" 1 "Deploy" 0 "None" ;
VAL_ 672 Coding_BtnID_D 1 "Pressed" 0 "Not_Pressed" ;
VAL_ 672 Coding_BtnID_C 1 "Pressed" 0 "Not_Pressed" ;
VAL_ 672 Coding_BtnID_B 1 "Pressed" 0 "Not_Pressed" ;
VAL_ 672 Coding_BtnID_A 1 "Pressed" 0 "Not_Pressed" ;
VAL_ 672 BCP_Audible_Beep_Rq 1 "Active" 0 "Inactive" ;
VAL_ 1205 CstmDrvMdeCfg2_B_Avail 1 "Available" 0 "NotAvailable" ;
VAL_ 1205 CstmDrvMdeCfg1_B_Avail 1 "Available" 0 "NotAvailable" ;
VAL_ 1200 BrkRearPCorrltn_B_Stat 1 "Yes" 0 "No" ;
VAL_ 1200 HsaTrnAout_Tq_Rq 65535 "Fault" 65534 "Unknown" ;
VAL_ 1200 BrkBstrVac_P_Actl 127 "Invalid" ;
VAL_ 1200 YawStabilityIndex 511 "Fault" 510 "NoDataExists" ;
VAL_ 1200 BrkTot_Tq_RqDrv 8191 "Fault" ;
VAL_ 1200 BrkHold_D_Stat 7 "NotUsed_3" 6 "NotUsed_2" 5 "NotUsed_1" 4 "HeldSecondary" 3 "HeldSecure" 2 "Held" 1 "Inactive" 0 "Off" ;
VAL_ 1200 HsaStat_D_Dsply 7 "NotUsed3" 6 "NotUsed2" 5 "NotUsed1" 4 "NotAvailable" 3 "SlowReleaseWithChime" 2 "SlowReleaseWithoutChime" 1 "Active" 0 "Inactive" ;
VAL_ 1018 TrlrTireSensILM_D_Stat 15 "NotSupported" 14 "NotUsed10" 13 "NotUsed9" 12 "NotUsed8" 11 "NotUsed7" 10 "NotUsed6" 9 "NotUsed5" 8 "NotUsed4" 7 "NotUsed3" 6 "NotUsed2" 5 "NotUsed1" 4 "Alert" 3 "Fault" 2 "Low" 1 "Normal" 0 "Unknown" ;
VAL_ 1018 TrlrTireSensILF_D_Stat 15 "NotSupported" 14 "NotUsed10" 13 "NotUsed9" 12 "NotUsed8" 11 "NotUsed7" 10 "NotUsed6" 9 "NotUsed5" 8 "NotUsed4" 7 "NotUsed3" 6 "NotUsed2" 5 "NotUsed1" 4 "Alert" 3 "Fault" 2 "Low" 1 "Normal" 0 "Unknown" ;
VAL_ 1018 TrlrTireILR_P_Actl 65534 "Invalid" 65535 "NotSupported" ;
VAL_ 1018 TrlrTireILM_P_Actl 65534 "Invalid" 65535 "NotSupported" ;
VAL_ 1018 TrlrTireILF_P_Actl 65534 "Invalid" 65535 "NotSupported" ;
VAL_ 1018 TrlrTireSensILR_D_Stat 15 "NotSupported" 14 "NotUsed10" 13 "NotUsed9" 12 "NotUsed8" 11 "NotUsed7" 10 "NotUsed6" 9 "NotUsed5" 8 "NotUsed4" 7 "NotUsed3" 6 "NotUsed2" 5 "NotUsed1" 4 "Alert" 3 "Fault" 2 "Low" 1 "Normal" 0 "Unknown" ;
VAL_ 1238 FbaMsg_D_Rq 3 "Faulty" 2 "Unavailable" 1 "Off" 0 "Null" ;
VAL_ 1238 FbaMnu_D_Rq 3 "NotUsed" 2 "Active" 1 "Inactive" 0 "None" ;
VAL_ 1238 Fba_D_Stat 3 "NotUsed" 2 "Disabled" 1 "On" 0 "Off" ;
VAL_ 1238 FbaAlrt_D_Dsply 3 "Both" 2 "Text" 1 "Graphic" 0 "Off" ;
VAL_ 1238 TjaLcEnbl_D_Stat 0 "Inactive" 1 "Off" 2 "On" 3 "NotUsed" ;
VAL_ 1238 TjaCanclMsgTxt_D_Dsply 15 "NotUsed_9" 14 "NotUsed_8" 13 "NotUsed_7" 12 "NotUsed_6" 11 "NotUsed_5" 10 "NotUsed_4" 9 "NotUsed_3" 8 "NotUsed_2" 7 "NotUsed_1" 6 "DriverNotSeen2" 5 "DriverNotSeen1" 4 "HandsFreeUnavailInThisArea" 3 "HandsFreeUnavailForMaxSpd" 2 "CancelledForLaneConditions" 1 "CancelledForRoadCurvature" 0 "NoMessage" ;
VAL_ 1238 GfhbMnu_D_Rq 3 "EnableADB" 2 "EnableGFHB" 1 "Disable" 0 "Null" ;
VAL_ 1238 AhbcMnu_D_Rq 3 "NotUsed" 2 "Enable" 1 "Disable" 0 "Null" ;
VAL_ 1238 TjaLaneBias_D_Stat 7 "NotUsed" 6 "ElBiasRight" 5 "ElBiasLeft" 4 "SystemBiasRight" 3 "SystemBiasLeft" 2 "ManualBiasRight" 1 "ManualBiasLeft" 0 "NoBias" ;
VAL_ 1238 TjaLcWarn_D_Rq 7 "NotUsed_2" 6 "NotUsed_1" 5 "CancelSpeedTooLow" 4 "CancelLaneBusy" 3 "CancelNoLane" 2 "SystemCancel" 1 "DriverCancel" 0 "NoWarning" ;
VAL_ 1238 TjaLcMsgTxt_D_Rq 7 "NotUsed_2" 6 "NotUsed_1" 5 "TurnOffIndicator" 4 "AlcOff" 3 "AlcOn" 2 "LcSuggestionRight" 1 "LcSuggestionLeft" 0 "NoMessage" ;
VAL_ 1238 TjaLc_D_Stat 15 "NotUsed_7" 14 "NotUsed_6" 13 "NotUsed_5" 12 "NotUsed_4" 11 "NotUsed_3" 10 "NotUsed_2" 9 "NotUsed_1" 8 "LcActiveRight" 7 "LcActiveLeft" 6 "PreparingRight" 5 "PreparingLeft" 4 "AvailableLeftRight" 3 "AvailableRight" 2 "AvailableLeft" 1 "Standby" 0 "Off" ;
VAL_ 1238 TjaLaneBiasEnbl_D_Stat 3 "NotUsed" 0 "Inactive" 2 "Enable" 1 "Disable" ;
VAL_ 1238 IaccVAdjReas_D_Dsply 15 "NotUsed_21" 11 "NotUsed_1" 10 "SpeedSign" 9 "LeftRamp" 8 "RightRamp" 7 "Roundabout_CCW" 6 "Roundabout_CW" 5 "LeftCurve" 4 "RightCurve" 3 "LeftTurnIntersection" 2 "RightTurnIntersection" 1 "RoadGeometryUnavailable" 0 "NoDisplay" ;
VAL_ 766 McCntrStckNotfn_B_Stat 1 "On" 0 "Off" ;
VAL_ 766 McSelMsgId_B_Stat 1 "Valid" 0 "Invalid" ;
VAL_ 766 McSelChoice_D_Stat 7 "Choice7" 6 "Choice6" 5 "Choice5" 4 "Choice4" 3 "Choice3" 2 "Choice2" 1 "Choice1" 0 "Ok" ;
VAL_ 766 McPrsntMsgId_B_Stat 1 "Valid" 0 "Invalid" ;
VAL_ 766 McPrsntActv_D_Stat 7 "NotUsed_4" 6 "NotUsed_3" 5 "NotUsed_2" 4 "NotUsed_1" 3 "Deactivated" 2 "UpdateGranted" 1 "ActiveGranted" 0 "Inactive" ;
VAL_ 840 FohAddHeater_D_Rq 3 "NotUsed" 2 "On" 1 "Off" 0 "NoModeSelected" ;
VAL_ 840 FohT2Friday_T_Rq 1 "Enable" 0 "Disable" ;
VAL_ 840 FohT1Friday_T_Rq 1 "Enable" 0 "Disable" ;
VAL_ 840 FohT2Wednesday_T_Rq 1 "Enable" 0 "Disable" ;
VAL_ 840 FohT2Tuesday_T_Rq 1 "Enable" 0 "Disable" ;
VAL_ 840 FohT2Thursday_T_Rq 1 "Enable" 0 "Disable" ;
VAL_ 840 FohT2Sunday_T_Rq 1 "Enable" 0 "Disable" ;
VAL_ 840 FohT2Saturday_T_Rq 1 "Enable" 0 "Disable" ;
VAL_ 840 FohT2Monday_T_Rq 1 "Enable" 0 "Disable" ;
VAL_ 840 FohT1Wednesday_T_Rq 1 "Enable" 0 "Disable" ;
VAL_ 840 FohT1Tuesday_T_Rq 1 "Enable" 0 "Disable" ;
VAL_ 840 FohT1Thursday_T_Rq 1 "Enable" 0 "Disable" ;
VAL_ 840 FohT1Sunday_T_Rq 1 "Enable" 0 "Disable" ;
VAL_ 840 FohT1Saturday_T_Rq 1 "Enable" 0 "Disable" ;
VAL_ 840 FohT1Monday_T_Rq 1 "Enable" 0 "Disable" ;
VAL_ 494 HEC_TUPresetArea_Rq 13 "reserved" 12 "GetSAT3PresetData" 11 "GetSAT2PresetData" 15 "reserved_last" 10 "GetSAT1PresetData" 9 "GetDAB2PresetData" 8 "GetDAB1PresetData" 7 "Reserved1" 6 "GetAmPresetData" 5 "GetAmAstPresetData" 4 "GetFmAstPresetData" 3 "GetFm3PresetData" 2 "GetFm2PresetData" 1 "GetFm1PresetData" 0 "Inactive" ;
VAL_ 494 HEC_SetCurrTUBand_Rq 12 "reserved" 11 "SAT3" 10 "SAT2" 15 "reserved_last" 9 "SAT1" 8 "DAB2" 7 "DAB1" 6 "AmAst" 5 "Am" 4 "FmAst" 3 "Fm3" 2 "Fm2" 1 "Fm1" 0 "Inactive" ;
